VERSION ""

NS_ :

BS_:

BU_:  Inverter  Battery  Charger  Host

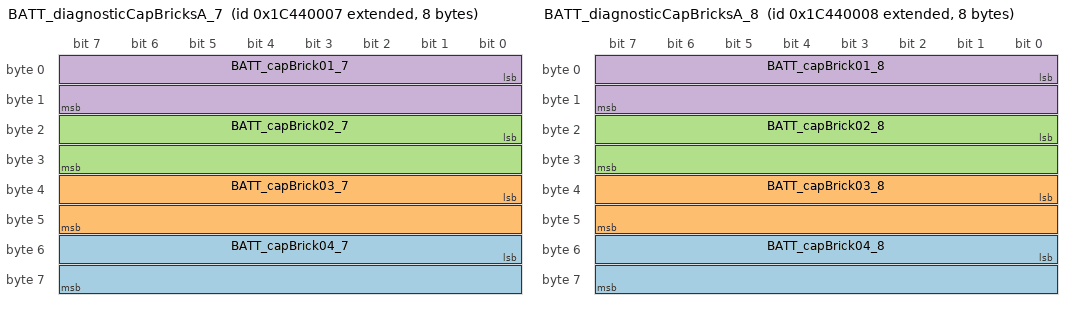
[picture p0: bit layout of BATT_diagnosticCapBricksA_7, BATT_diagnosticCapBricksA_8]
BO_ 2621702151 BATT_diagnosticCapBricksA_7: 8 Battery
 SG_ BATT_capBrick04_7 : 48|16@1+ (0.00075,0) [0|49.15125] "Ah" Host
 SG_ BATT_capBrick03_7 : 32|16@1+ (0.00075,0) [0|49.15125] "Ah" Host
 SG_ BATT_capBrick02_7 : 16|16@1+ (0.00075,0) [0|49.15125] "Ah" Host
 SG_ BATT_capBrick01_7 : 0|16@1+ (0.00075,0) [0|49.15125] "Ah" Host

BO_ 2621702152 BATT_diagnosticCapBricksA_8: 8 Battery
 SG_ BATT_capBrick04_8 : 48|16@1+ (0.00075,0) [0|49.15125] "Ah" Host
 SG_ BATT_capBrick03_8 : 32|16@1+ (0.00075,0) [0|49.15125] "Ah" Host
 SG_ BATT_capBrick02_8 : 16|16@1+ (0.00075,0) [0|49.15125] "Ah" Host
 SG_ BATT_capBrick01_8 : 0|16@1+ (0.00075,0) [0|49.15125] "Ah" Host

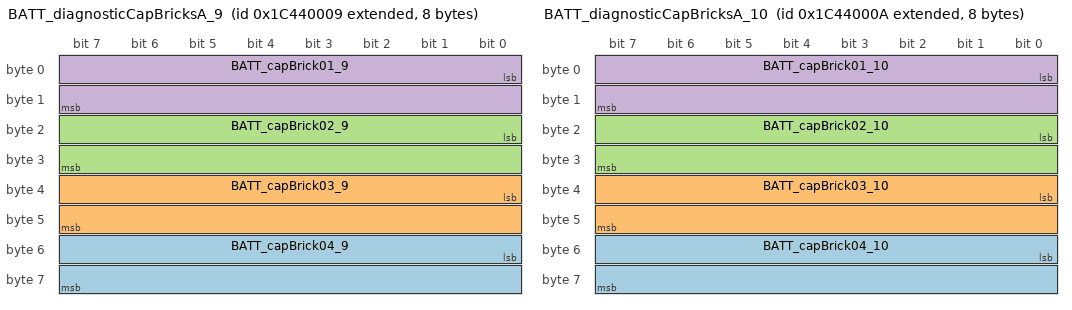
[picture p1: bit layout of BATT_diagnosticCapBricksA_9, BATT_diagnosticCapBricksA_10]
BO_ 2621702153 BATT_diagnosticCapBricksA_9: 8 Battery
 SG_ BATT_capBrick04_9 : 48|16@1+ (0.00075,0) [0|49.15125] "Ah" Host
 SG_ BATT_capBrick03_9 : 32|16@1+ (0.00075,0) [0|49.15125] "Ah" Host
 SG_ BATT_capBrick02_9 : 16|16@1+ (0.00075,0) [0|49.15125] "Ah" Host
 SG_ BATT_capBrick01_9 : 0|16@1+ (0.00075,0) [0|49.15125] "Ah" Host

BO_ 2621702154 BATT_diagnosticCapBricksA_10: 8 Battery
 SG_ BATT_capBrick04_10 : 48|16@1+ (0.00075,0) [0|49.15125] "Ah" Host
 SG_ BATT_capBrick03_10 : 32|16@1+ (0.00075,0) [0|49.15125] "Ah" Host
 SG_ BATT_capBrick02_10 : 16|16@1+ (0.00075,0) [0|49.15125] "Ah" Host
 SG_ BATT_capBrick01_10 : 0|16@1+ (0.00075,0) [0|49.15125] "Ah" Host

BO_ 2621702155 BATT_diagnosticCapBricksA_11: 8 Battery
 SG_ BATT_capBrick04_11 : 48|16@1+ (0.00075,0) [0|49.15125] "Ah" Host
 SG_ BATT_capBrick03_11 : 32|16@1+ (0.00075,0) [0|49.15125] "Ah" Host
 SG_ BATT_capBrick02_11 : 16|16@1+ (0.00075,0) [0|49.15125] "Ah" Host
 SG_ BATT_capBrick01_11 : 0|16@1+ (0.00075,0) [0|49.15125] "Ah" Host

BO_ 2621964288 BATT_diagnosticCapBricksB_0: 8 Battery
 SG_ BATT_capBrick08_0 : 48|16@1+ (0.00075,0) [0|49.15125] "Ah" Host
 SG_ BATT_capBrick07_0 : 32|16@1+ (0.00075,0) [0|49.15125] "Ah" Host
 SG_ BATT_capBrick06_0 : 16|16@1+ (0.00075,0) [0|49.15125] "Ah" Host
 SG_ BATT_capBrick05_0 : 0|16@1+ (0.00075,0) [0|49.15125] "Ah" Host

BO_ 2621964289 BATT_diagnosticCapBricksB_1: 8 Battery
 SG_ BATT_capBrick08_1 : 48|16@1+ (0.00075,0) [0|49.15125] "Ah" Host
 SG_ BATT_capBrick07_1 : 32|16@1+ (0.00075,0) [0|49.15125] "Ah" Host
 SG_ BATT_capBrick06_1 : 16|16@1+ (0.00075,0) [0|49.15125] "Ah" Host
 SG_ BATT_capBrick05_1 : 0|16@1+ (0.00075,0) [0|49.15125] "Ah" Host

BO_ 2621964290 BATT_diagnosticCapBricksB_2: 8 Battery
 SG_ BATT_capBrick08_2 : 48|16@1+ (0.00075,0) [0|49.15125] "Ah" Host
 SG_ BATT_capBrick07_2 : 32|16@1+ (0.00075,0) [0|49.15125] "Ah" Host
 SG_ BATT_capBrick06_2 : 16|16@1+ (0.00075,0) [0|49.15125] "Ah" Host
 SG_ BATT_capBrick05_2 : 0|16@1+ (0.00075,0) [0|49.15125] "Ah" Host

BO_ 2621964291 BATT_diagnosticCapBricksB_3: 8 Battery
 SG_ BATT_capBrick08_3 : 48|16@1+ (0.00075,0) [0|49.15125] "Ah" Host
 SG_ BATT_capBrick07_3 : 32|16@1+ (0.00075,0) [0|49.15125] "Ah" Host
 SG_ BATT_capBrick06_3 : 16|16@1+ (0.00075,0) [0|49.15125] "Ah" Host
 SG_ BATT_capBrick05_3 : 0|16@1+ (0.00075,0) [0|49.15125] "Ah" Host

BO_ 2621964292 BATT_diagnosticCapBricksB_4: 8 Battery
 SG_ BATT_capBrick08_4 : 48|16@1+ (0.00075,0) [0|49.15125] "Ah" Host
 SG_ BATT_capBrick07_4 : 32|16@1+ (0.00075,0) [0|49.15125] "Ah" Host
 SG_ BATT_capBrick06_4 : 16|16@1+ (0.00075,0) [0|49.15125] "Ah" Host
 SG_ BATT_capBrick05_4 : 0|16@1+ (0.00075,0) [0|49.15125] "Ah" Host

BO_ 2621964293 BATT_diagnosticCapBricksB_5: 8 Battery
 SG_ BATT_capBrick08_5 : 48|16@1+ (0.00075,0) [0|49.15125] "Ah" Host
 SG_ BATT_capBrick07_5 : 32|16@1+ (0.00075,0) [0|49.15125] "Ah" Host
 SG_ BATT_capBrick06_5 : 16|16@1+ (0.00075,0) [0|49.15125] "Ah" Host
 SG_ BATT_capBrick05_5 : 0|16@1+ (0.00075,0) [0|49.15125] "Ah" Host

BO_ 2621964294 BATT_diagnosticCapBricksB_6: 8 Battery
 SG_ BATT_capBrick08_6 : 48|16@1+ (0.00075,0) [0|49.15125] "Ah" Host
 SG_ BATT_capBrick07_6 : 32|16@1+ (0.00075,0) [0|49.15125] "Ah" Host
 SG_ BATT_capBrick06_6 : 16|16@1+ (0.00075,0) [0|49.15125] "Ah" Host
 SG_ BATT_capBrick05_6 : 0|16@1+ (0.00075,0) [0|49.15125] "Ah" Host

BO_ 2621964295 BATT_diagnosticCapBricksB_7: 8 Battery
 SG_ BATT_capBrick08_7 : 48|16@1+ (0.00075,0) [0|49.15125] "Ah" Host
 SG_ BATT_capBrick07_7 : 32|16@1+ (0.00075,0) [0|49.15125] "Ah" Host
 SG_ BATT_capBrick06_7 : 16|16@1+ (0.00075,0) [0|49.15125] "Ah" Host
 SG_ BATT_capBrick05_7 : 0|16@1+ (0.00075,0) [0|49.15125] "Ah" Host

BO_ 2621964296 BATT_diagnosticCapBricksB_8: 8 Battery
 SG_ BATT_capBrick08_8 : 48|16@1+ (0.00075,0) [0|49.15125] "Ah" Host
 SG_ BATT_capBrick07_8 : 32|16@1+ (0.00075,0) [0|49.15125] "Ah" Host
 SG_ BATT_capBrick06_8 : 16|16@1+ (0.00075,0) [0|49.15125] "Ah" Host
 SG_ BATT_capBrick05_8 : 0|16@1+ (0.00075,0) [0|49.15125] "Ah" Host

BO_ 2621964297 BATT_diagnosticCapBricksB_9: 8 Battery
 SG_ BATT_capBrick08_9 : 48|16@1+ (0.00075,0) [0|49.15125] "Ah" Host
 SG_ BATT_capBrick07_9 : 32|16@1+ (0.00075,0) [0|49.15125] "Ah" Host
 SG_ BATT_capBrick06_9 : 16|16@1+ (0.00075,0) [0|49.15125] "Ah" Host
 SG_ BATT_capBrick05_9 : 0|16@1+ (0.00075,0) [0|49.15125] "Ah" Host

BO_ 2621964298 BATT_diagnosticCapBricksB_10: 8 Battery
 SG_ BATT_capBrick08_10 : 48|16@1+ (0.00075,0) [0|49.15125] "Ah" Host
 SG_ BATT_capBrick07_10 : 32|16@1+ (0.00075,0) [0|49.15125] "Ah" Host
 SG_ BATT_capBrick06_10 : 16|16@1+ (0.00075,0) [0|49.15125] "Ah" Host
 SG_ BATT_capBrick05_10 : 0|16@1+ (0.00075,0) [0|49.15125] "Ah" Host

BO_ 2621964299 BATT_diagnosticCapBricksB_11: 8 Battery
 SG_ BATT_capBrick08_11 : 48|16@1+ (0.00075,0) [0|49.15125] "Ah" Host
 SG_ BATT_capBrick07_11 : 32|16@1+ (0.00075,0) [0|49.15125] "Ah" Host
 SG_ BATT_capBrick06_11 : 16|16@1+ (0.00075,0) [0|49.15125] "Ah" Host
 SG_ BATT_capBrick05_11 : 0|16@1+ (0.00075,0) [0|49.15125] "Ah" Host

BO_ 2622226432 BATT_diagnosticCapBricksC_0: 8 Battery
 SG_ BATT_capBrick12_0 : 48|16@1+ (0.00075,0) [0|49.15125] "Ah" Host
 SG_ BATT_capBrick11_0 : 32|16@1+ (0.00075,0) [0|49.15125] "Ah" Host
 SG_ BATT_capBrick09_0 : 0|16@1+ (0.00075,0) [0|49.15125] "Ah" Host
 SG_ BATT_capBrick10_0 : 16|16@1+ (0.00075,0) [0|49.15125] "Ah" Host

BO_ 2622226433 BATT_diagnosticCapBricksC_1: 8 Battery
 SG_ BATT_capBrick12_1 : 48|16@1+ (0.00075,0) [0|49.15125] "Ah" Host
 SG_ BATT_capBrick11_1 : 32|16@1+ (0.00075,0) [0|49.15125] "Ah" Host
 SG_ BATT_capBrick09_1 : 0|16@1+ (0.00075,0) [0|49.15125] "Ah" Host
 SG_ BATT_capBrick10_1 : 16|16@1+ (0.00075,0) [0|49.15125] "Ah" Host

BO_ 2622226434 BATT_diagnosticCapBricksC_2: 8 Battery
 SG_ BATT_capBrick12_2 : 48|16@1+ (0.00075,0) [0|49.15125] "Ah" Host
 SG_ BATT_capBrick11_2 : 32|16@1+ (0.00075,0) [0|49.15125] "Ah" Host
 SG_ BATT_capBrick09_2 : 0|16@1+ (0.00075,0) [0|49.15125] "Ah" Host
 SG_ BATT_capBrick10_2 : 16|16@1+ (0.00075,0) [0|49.15125] "Ah" Host

BO_ 2622226435 BATT_diagnosticCapBricksC_3: 8 Battery
 SG_ BATT_capBrick12_3 : 48|16@1+ (0.00075,0) [0|49.15125] "Ah" Host
 SG_ BATT_capBrick11_3 : 32|16@1+ (0.00075,0) [0|49.15125] "Ah" Host
 SG_ BATT_capBrick09_3 : 0|16@1+ (0.00075,0) [0|49.15125] "Ah" Host
 SG_ BATT_capBrick10_3 : 16|16@1+ (0.00075,0) [0|49.15125] "Ah" Host

BO_ 2622226436 BATT_diagnosticCapBricksC_4: 8 Battery
 SG_ BATT_capBrick12_4 : 48|16@1+ (0.00075,0) [0|49.15125] "Ah" Host
 SG_ BATT_capBrick11_4 : 32|16@1+ (0.00075,0) [0|49.15125] "Ah" Host
 SG_ BATT_capBrick09_4 : 0|16@1+ (0.00075,0) [0|49.15125] "Ah" Host
 SG_ BATT_capBrick10_4 : 16|16@1+ (0.00075,0) [0|49.15125] "Ah" Host

BO_ 2622226437 BATT_diagnosticCapBricksC_5: 8 Battery
 SG_ BATT_capBrick12_5 : 48|16@1+ (0.00075,0) [0|49.15125] "Ah" Host
 SG_ BATT_capBrick11_5 : 32|16@1+ (0.00075,0) [0|49.15125] "Ah" Host
 SG_ BATT_capBrick09_5 : 0|16@1+ (0.00075,0) [0|49.15125] "Ah" Host
 SG_ BATT_capBrick10_5 : 16|16@1+ (0.00075,0) [0|49.15125] "Ah" Host

BO_ 2622226438 BATT_diagnosticCapBricksC_6: 8 Battery
 SG_ BATT_capBrick12_6 : 48|16@1+ (0.00075,0) [0|49.15125] "Ah" Host
 SG_ BATT_capBrick11_6 : 32|16@1+ (0.00075,0) [0|49.15125] "Ah" Host
 SG_ BATT_capBrick09_6 : 0|16@1+ (0.00075,0) [0|49.15125] "Ah" Host
 SG_ BATT_capBrick10_6 : 16|16@1+ (0.00075,0) [0|49.15125] "Ah" Host

BO_ 2622226439 BATT_diagnosticCapBricksC_7: 8 Battery
 SG_ BATT_capBrick12_7 : 48|16@1+ (0.00075,0) [0|49.15125] "Ah" Host
 SG_ BATT_capBrick11_7 : 32|16@1+ (0.00075,0) [0|49.15125] "Ah" Host
 SG_ BATT_capBrick09_7 : 0|16@1+ (0.00075,0) [0|49.15125] "Ah" Host
 SG_ BATT_capBrick10_7 : 16|16@1+ (0.00075,0) [0|49.15125] "Ah" Host

BO_ 2622226440 BATT_diagnosticCapBricksC_8: 8 Battery
 SG_ BATT_capBrick12_8 : 48|16@1+ (0.00075,0) [0|49.15125] "Ah" Host
 SG_ BATT_capBrick11_8 : 32|16@1+ (0.00075,0) [0|49.15125] "Ah" Host
 SG_ BATT_capBrick09_8 : 0|16@1+ (0.00075,0) [0|49.15125] "Ah" Host
 SG_ BATT_capBrick10_8 : 16|16@1+ (0.00075,0) [0|49.15125] "Ah" Host

BO_ 2622226441 BATT_diagnosticCapBricksC_9: 8 Battery
 SG_ BATT_capBrick12_9 : 48|16@1+ (0.00075,0) [0|49.15125] "Ah" Host
 SG_ BATT_capBrick11_9 : 32|16@1+ (0.00075,0) [0|49.15125] "Ah" Host
 SG_ BATT_capBrick09_9 : 0|16@1+ (0.00075,0) [0|49.15125] "Ah" Host
 SG_ BATT_capBrick10_9 : 16|16@1+ (0.00075,0) [0|49.15125] "Ah" Host

BO_ 2622226442 BATT_diagnosticCapBricksC_10: 8 Battery
 SG_ BATT_capBrick12_10 : 48|16@1+ (0.00075,0) [0|49.15125] "Ah" Host
 SG_ BATT_capBrick11_10 : 32|16@1+ (0.00075,0) [0|49.15125] "Ah" Host
 SG_ BATT_capBrick09_10 : 0|16@1+ (0.00075,0) [0|49.15125] "Ah" Host
 SG_ BATT_capBrick10_10 : 16|16@1+ (0.00075,0) [0|49.15125] "Ah" Host

BO_ 2622226443 BATT_diagnosticCapBricksC_11: 8 Battery
 SG_ BATT_capBrick12_11 : 48|16@1+ (0.00075,0) [0|49.15125] "Ah" Host
 SG_ BATT_capBrick11_11 : 32|16@1+ (0.00075,0) [0|49.15125] "Ah" Host
 SG_ BATT_capBrick09_11 : 0|16@1+ (0.00075,0) [0|49.15125] "Ah" Host
 SG_ BATT_capBrick10_11 : 16|16@1+ (0.00075,0) [0|49.15125] "Ah" Host

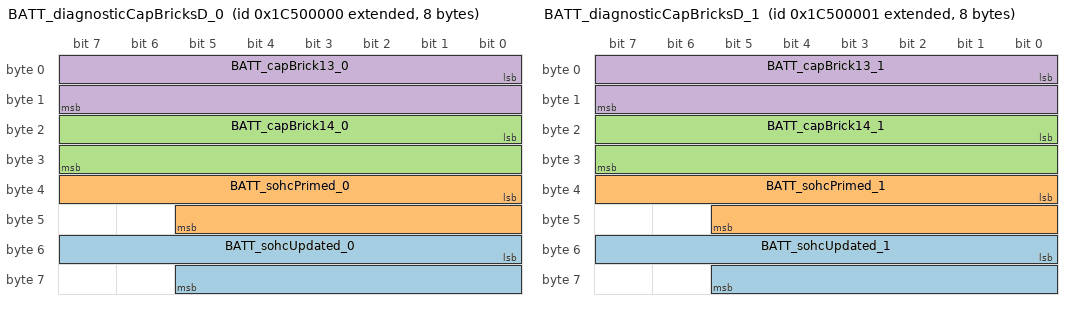
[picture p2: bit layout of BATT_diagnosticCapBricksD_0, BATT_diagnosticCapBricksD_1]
BO_ 2622488576 BATT_diagnosticCapBricksD_0: 8 Battery
 SG_ BATT_sohcUpdated_0 : 48|14@1+ (1,0) [0|16383] "" Host
 SG_ BATT_sohcPrimed_0 : 32|14@1+ (1,0) [0|16383] "" Host
 SG_ BATT_capBrick14_0 : 16|16@1+ (0.00075,0) [0|49.15125] "Ah" Host
 SG_ BATT_capBrick13_0 : 0|16@1+ (0.00075,0) [0|49.15125] "Ah" Host

BO_ 2622488577 BATT_diagnosticCapBricksD_1: 8 Battery
 SG_ BATT_sohcUpdated_1 : 48|14@1+ (1,0) [0|16383] "" Host
 SG_ BATT_sohcPrimed_1 : 32|14@1+ (1,0) [0|16383] "" Host
 SG_ BATT_capBrick14_1 : 16|16@1+ (0.00075,0) [0|49.15125] "Ah" Host
 SG_ BATT_capBrick13_1 : 0|16@1+ (0.00075,0) [0|49.15125] "Ah" Host

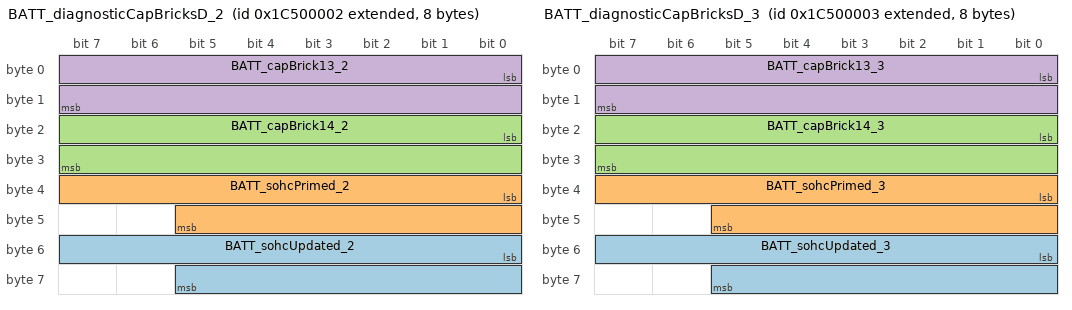
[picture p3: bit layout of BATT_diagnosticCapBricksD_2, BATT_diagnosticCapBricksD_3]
BO_ 2622488578 BATT_diagnosticCapBricksD_2: 8 Battery
 SG_ BATT_sohcUpdated_2 : 48|14@1+ (1,0) [0|16383] "" Host
 SG_ BATT_sohcPrimed_2 : 32|14@1+ (1,0) [0|16383] "" Host
 SG_ BATT_capBrick14_2 : 16|16@1+ (0.00075,0) [0|49.15125] "Ah" Host
 SG_ BATT_capBrick13_2 : 0|16@1+ (0.00075,0) [0|49.15125] "Ah" Host

BO_ 2622488579 BATT_diagnosticCapBricksD_3: 8 Battery
 SG_ BATT_sohcUpdated_3 : 48|14@1+ (1,0) [0|16383] "" Host
 SG_ BATT_sohcPrimed_3 : 32|14@1+ (1,0) [0|16383] "" Host
 SG_ BATT_capBrick14_3 : 16|16@1+ (0.00075,0) [0|49.15125] "Ah" Host
 SG_ BATT_capBrick13_3 : 0|16@1+ (0.00075,0) [0|49.15125] "Ah" Host

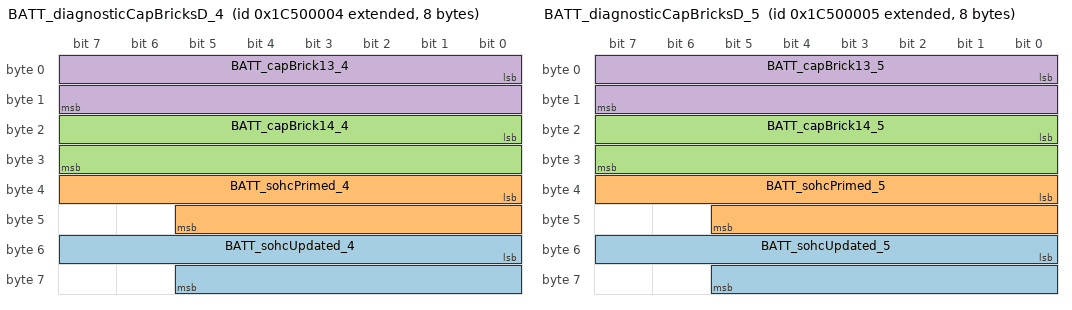
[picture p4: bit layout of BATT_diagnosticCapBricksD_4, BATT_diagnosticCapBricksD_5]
BO_ 2622488580 BATT_diagnosticCapBricksD_4: 8 Battery
 SG_ BATT_sohcUpdated_4 : 48|14@1+ (1,0) [0|16383] "" Host
 SG_ BATT_sohcPrimed_4 : 32|14@1+ (1,0) [0|16383] "" Host
 SG_ BATT_capBrick14_4 : 16|16@1+ (0.00075,0) [0|49.15125] "Ah" Host
 SG_ BATT_capBrick13_4 : 0|16@1+ (0.00075,0) [0|49.15125] "Ah" Host

BO_ 2622488581 BATT_diagnosticCapBricksD_5: 8 Battery
 SG_ BATT_sohcUpdated_5 : 48|14@1+ (1,0) [0|16383] "" Host
 SG_ BATT_sohcPrimed_5 : 32|14@1+ (1,0) [0|16383] "" Host
 SG_ BATT_capBrick14_5 : 16|16@1+ (0.00075,0) [0|49.15125] "Ah" Host
 SG_ BATT_capBrick13_5 : 0|16@1+ (0.00075,0) [0|49.15125] "Ah" Host

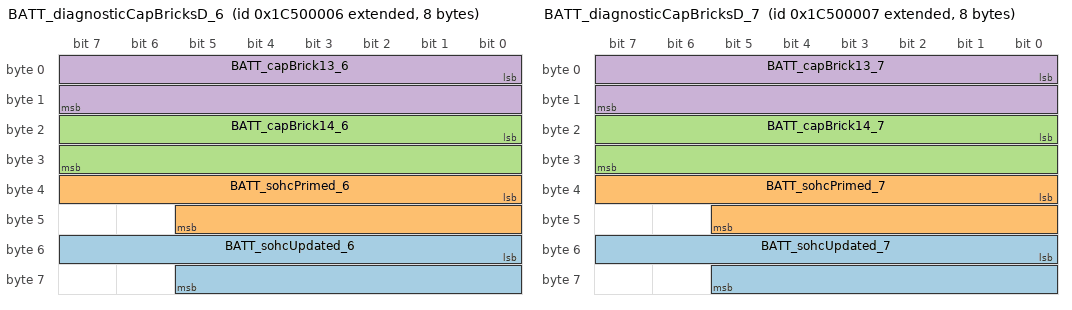
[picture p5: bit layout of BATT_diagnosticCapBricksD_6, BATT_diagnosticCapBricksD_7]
BO_ 2622488582 BATT_diagnosticCapBricksD_6: 8 Battery
 SG_ BATT_sohcUpdated_6 : 48|14@1+ (1,0) [0|16383] "" Host
 SG_ BATT_sohcPrimed_6 : 32|14@1+ (1,0) [0|16383] "" Host
 SG_ BATT_capBrick14_6 : 16|16@1+ (0.00075,0) [0|49.15125] "Ah" Host
 SG_ BATT_capBrick13_6 : 0|16@1+ (0.00075,0) [0|49.15125] "Ah" Host

BO_ 2622488583 BATT_diagnosticCapBricksD_7: 8 Battery
 SG_ BATT_sohcUpdated_7 : 48|14@1+ (1,0) [0|16383] "" Host
 SG_ BATT_sohcPrimed_7 : 32|14@1+ (1,0) [0|16383] "" Host
 SG_ BATT_capBrick14_7 : 16|16@1+ (0.00075,0) [0|49.15125] "Ah" Host
 SG_ BATT_capBrick13_7 : 0|16@1+ (0.00075,0) [0|49.15125] "Ah" Host

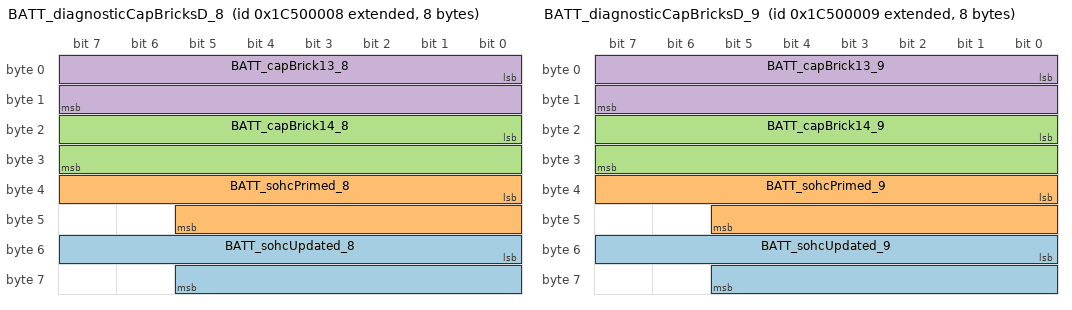
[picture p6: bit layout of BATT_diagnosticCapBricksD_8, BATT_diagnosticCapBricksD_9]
BO_ 2622488584 BATT_diagnosticCapBricksD_8: 8 Battery
 SG_ BATT_sohcUpdated_8 : 48|14@1+ (1,0) [0|16383] "" Host
 SG_ BATT_sohcPrimed_8 : 32|14@1+ (1,0) [0|16383] "" Host
 SG_ BATT_capBrick14_8 : 16|16@1+ (0.00075,0) [0|49.15125] "Ah" Host
 SG_ BATT_capBrick13_8 : 0|16@1+ (0.00075,0) [0|49.15125] "Ah" Host

BO_ 2622488585 BATT_diagnosticCapBricksD_9: 8 Battery
 SG_ BATT_sohcUpdated_9 : 48|14@1+ (1,0) [0|16383] "" Host
 SG_ BATT_sohcPrimed_9 : 32|14@1+ (1,0) [0|16383] "" Host
 SG_ BATT_capBrick14_9 : 16|16@1+ (0.00075,0) [0|49.15125] "Ah" Host
 SG_ BATT_capBrick13_9 : 0|16@1+ (0.00075,0) [0|49.15125] "Ah" Host

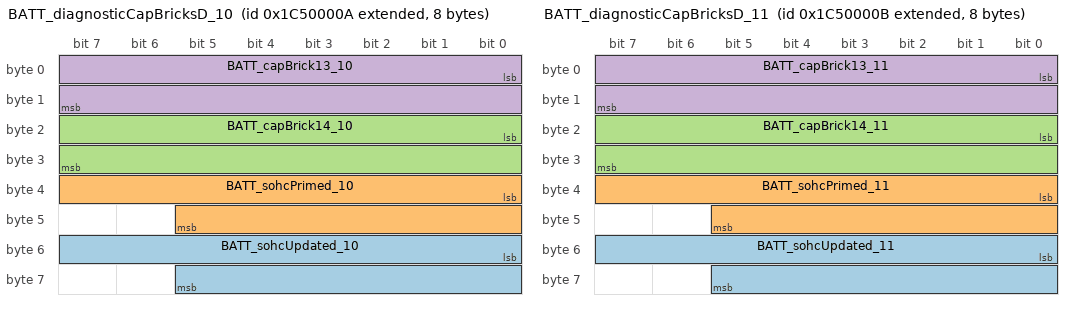
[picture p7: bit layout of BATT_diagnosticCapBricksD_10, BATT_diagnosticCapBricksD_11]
BO_ 2622488586 BATT_diagnosticCapBricksD_10: 8 Battery
 SG_ BATT_sohcUpdated_10 : 48|14@1+ (1,0) [0|16383] "" Host
 SG_ BATT_sohcPrimed_10 : 32|14@1+ (1,0) [0|16383] "" Host
 SG_ BATT_capBrick14_10 : 16|16@1+ (0.00075,0) [0|49.15125] "Ah" Host
 SG_ BATT_capBrick13_10 : 0|16@1+ (0.00075,0) [0|49.15125] "Ah" Host

BO_ 2622488587 BATT_diagnosticCapBricksD_11: 8 Battery
 SG_ BATT_sohcUpdated_11 : 48|14@1+ (1,0) [0|16383] "" Host
 SG_ BATT_sohcPrimed_11 : 32|14@1+ (1,0) [0|16383] "" Host
 SG_ BATT_capBrick14_11 : 16|16@1+ (0.00075,0) [0|49.15125] "Ah" Host
 SG_ BATT_capBrick13_11 : 0|16@1+ (0.00075,0) [0|49.15125] "Ah" Host

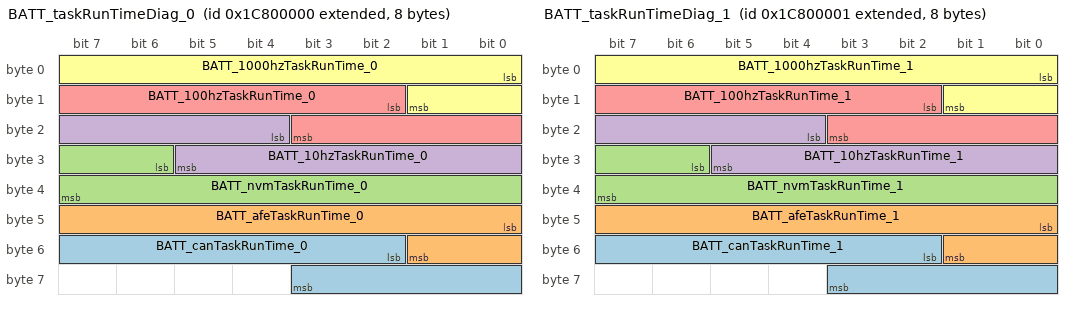
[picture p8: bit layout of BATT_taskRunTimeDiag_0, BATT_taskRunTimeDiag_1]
BO_ 2625634304 BATT_taskRunTimeDiag_0: 8 Battery
 SG_ BATT_canTaskRunTime_0 : 50|10@1+ (1,0) [0|1023] "ms" Host
 SG_ BATT_afeTaskRunTime_0 : 40|10@1+ (1,0) [0|1023] "ms" Host
 SG_ BATT_nvmTaskRunTime_0 : 30|10@1+ (1,0) [0|1023] "ms" Host
 SG_ BATT_10hzTaskRunTime_0 : 20|10@1+ (1,0) [0|1023] "ms" Host
 SG_ BATT_100hzTaskRunTime_0 : 10|10@1+ (1,0) [0|1023] "ms" Host
 SG_ BATT_1000hzTaskRunTime_0 : 0|10@1+ (1,0) [0|1023] "ms" Host

BO_ 2625634305 BATT_taskRunTimeDiag_1: 8 Battery
 SG_ BATT_canTaskRunTime_1 : 50|10@1+ (1,0) [0|1023] "ms" Host
 SG_ BATT_afeTaskRunTime_1 : 40|10@1+ (1,0) [0|1023] "ms" Host
 SG_ BATT_nvmTaskRunTime_1 : 30|10@1+ (1,0) [0|1023] "ms" Host
 SG_ BATT_10hzTaskRunTime_1 : 20|10@1+ (1,0) [0|1023] "ms" Host
 SG_ BATT_100hzTaskRunTime_1 : 10|10@1+ (1,0) [0|1023] "ms" Host
 SG_ BATT_1000hzTaskRunTime_1 : 0|10@1+ (1,0) [0|1023] "ms" Host

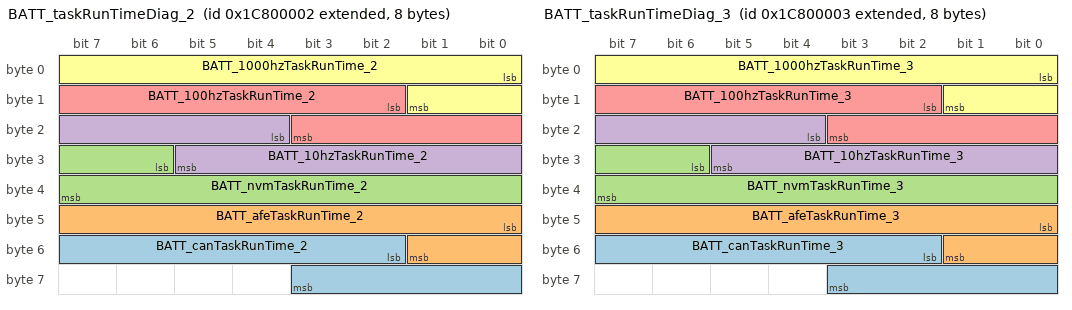
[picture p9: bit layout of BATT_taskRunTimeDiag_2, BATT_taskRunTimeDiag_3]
BO_ 2625634306 BATT_taskRunTimeDiag_2: 8 Battery
 SG_ BATT_canTaskRunTime_2 : 50|10@1+ (1,0) [0|1023] "ms" Host
 SG_ BATT_afeTaskRunTime_2 : 40|10@1+ (1,0) [0|1023] "ms" Host
 SG_ BATT_nvmTaskRunTime_2 : 30|10@1+ (1,0) [0|1023] "ms" Host
 SG_ BATT_10hzTaskRunTime_2 : 20|10@1+ (1,0) [0|1023] "ms" Host
 SG_ BATT_100hzTaskRunTime_2 : 10|10@1+ (1,0) [0|1023] "ms" Host
 SG_ BATT_1000hzTaskRunTime_2 : 0|10@1+ (1,0) [0|1023] "ms" Host

BO_ 2625634307 BATT_taskRunTimeDiag_3: 8 Battery
 SG_ BATT_canTaskRunTime_3 : 50|10@1+ (1,0) [0|1023] "ms" Host
 SG_ BATT_afeTaskRunTime_3 : 40|10@1+ (1,0) [0|1023] "ms" Host
 SG_ BATT_nvmTaskRunTime_3 : 30|10@1+ (1,0) [0|1023] "ms" Host
 SG_ BATT_10hzTaskRunTime_3 : 20|10@1+ (1,0) [0|1023] "ms" Host
 SG_ BATT_100hzTaskRunTime_3 : 10|10@1+ (1,0) [0|1023] "ms" Host
 SG_ BATT_1000hzTaskRunTime_3 : 0|10@1+ (1,0) [0|1023] "ms" Host

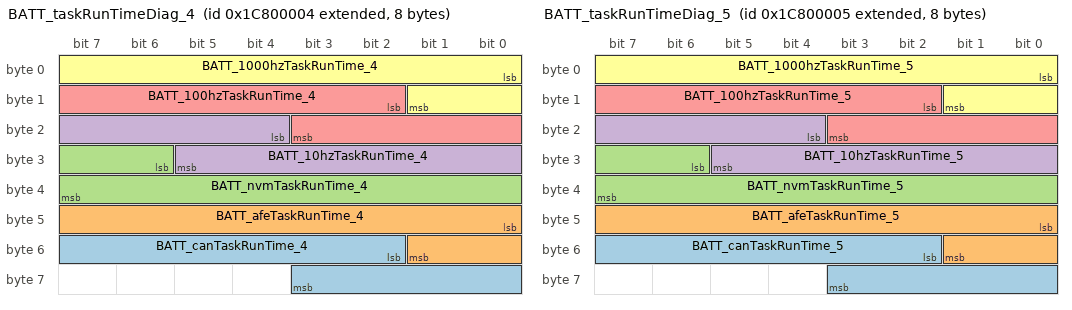
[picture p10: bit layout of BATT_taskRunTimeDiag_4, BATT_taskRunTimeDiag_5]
BO_ 2625634308 BATT_taskRunTimeDiag_4: 8 Battery
 SG_ BATT_canTaskRunTime_4 : 50|10@1+ (1,0) [0|1023] "ms" Host
 SG_ BATT_afeTaskRunTime_4 : 40|10@1+ (1,0) [0|1023] "ms" Host
 SG_ BATT_nvmTaskRunTime_4 : 30|10@1+ (1,0) [0|1023] "ms" Host
 SG_ BATT_10hzTaskRunTime_4 : 20|10@1+ (1,0) [0|1023] "ms" Host
 SG_ BATT_100hzTaskRunTime_4 : 10|10@1+ (1,0) [0|1023] "ms" Host
 SG_ BATT_1000hzTaskRunTime_4 : 0|10@1+ (1,0) [0|1023] "ms" Host

BO_ 2625634309 BATT_taskRunTimeDiag_5: 8 Battery
 SG_ BATT_canTaskRunTime_5 : 50|10@1+ (1,0) [0|1023] "ms" Host
 SG_ BATT_afeTaskRunTime_5 : 40|10@1+ (1,0) [0|1023] "ms" Host
 SG_ BATT_nvmTaskRunTime_5 : 30|10@1+ (1,0) [0|1023] "ms" Host
 SG_ BATT_10hzTaskRunTime_5 : 20|10@1+ (1,0) [0|1023] "ms" Host
 SG_ BATT_100hzTaskRunTime_5 : 10|10@1+ (1,0) [0|1023] "ms" Host
 SG_ BATT_1000hzTaskRunTime_5 : 0|10@1+ (1,0) [0|1023] "ms" Host

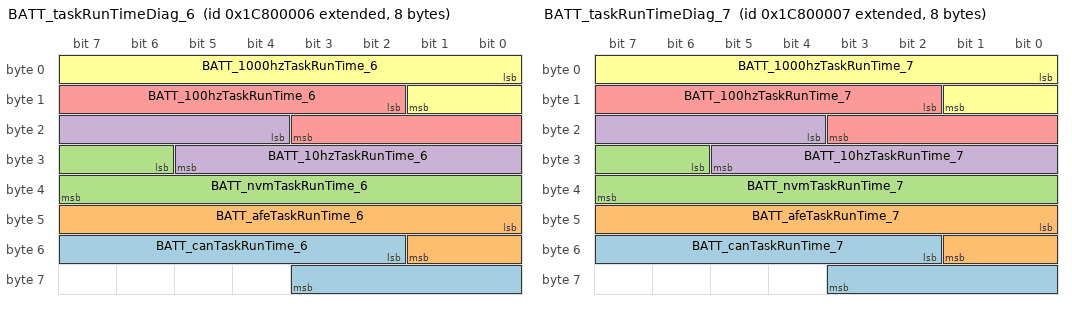
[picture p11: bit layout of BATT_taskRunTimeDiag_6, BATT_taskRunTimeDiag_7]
BO_ 2625634310 BATT_taskRunTimeDiag_6: 8 Battery
 SG_ BATT_canTaskRunTime_6 : 50|10@1+ (1,0) [0|1023] "ms" Host
 SG_ BATT_afeTaskRunTime_6 : 40|10@1+ (1,0) [0|1023] "ms" Host
 SG_ BATT_nvmTaskRunTime_6 : 30|10@1+ (1,0) [0|1023] "ms" Host
 SG_ BATT_10hzTaskRunTime_6 : 20|10@1+ (1,0) [0|1023] "ms" Host
 SG_ BATT_100hzTaskRunTime_6 : 10|10@1+ (1,0) [0|1023] "ms" Host
 SG_ BATT_1000hzTaskRunTime_6 : 0|10@1+ (1,0) [0|1023] "ms" Host

BO_ 2625634311 BATT_taskRunTimeDiag_7: 8 Battery
 SG_ BATT_canTaskRunTime_7 : 50|10@1+ (1,0) [0|1023] "ms" Host
 SG_ BATT_afeTaskRunTime_7 : 40|10@1+ (1,0) [0|1023] "ms" Host
 SG_ BATT_nvmTaskRunTime_7 : 30|10@1+ (1,0) [0|1023] "ms" Host
 SG_ BATT_10hzTaskRunTime_7 : 20|10@1+ (1,0) [0|1023] "ms" Host
 SG_ BATT_100hzTaskRunTime_7 : 10|10@1+ (1,0) [0|1023] "ms" Host
 SG_ BATT_1000hzTaskRunTime_7 : 0|10@1+ (1,0) [0|1023] "ms" Host

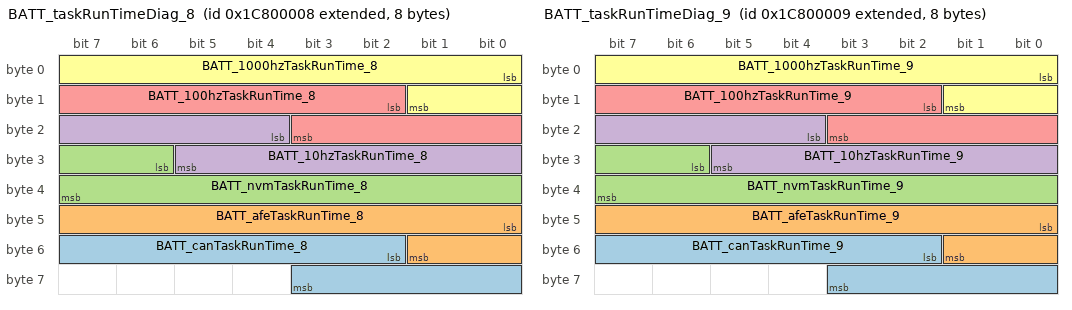
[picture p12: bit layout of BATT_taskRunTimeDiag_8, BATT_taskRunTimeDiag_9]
BO_ 2625634312 BATT_taskRunTimeDiag_8: 8 Battery
 SG_ BATT_canTaskRunTime_8 : 50|10@1+ (1,0) [0|1023] "ms" Host
 SG_ BATT_afeTaskRunTime_8 : 40|10@1+ (1,0) [0|1023] "ms" Host
 SG_ BATT_nvmTaskRunTime_8 : 30|10@1+ (1,0) [0|1023] "ms" Host
 SG_ BATT_10hzTaskRunTime_8 : 20|10@1+ (1,0) [0|1023] "ms" Host
 SG_ BATT_100hzTaskRunTime_8 : 10|10@1+ (1,0) [0|1023] "ms" Host
 SG_ BATT_1000hzTaskRunTime_8 : 0|10@1+ (1,0) [0|1023] "ms" Host

BO_ 2625634313 BATT_taskRunTimeDiag_9: 8 Battery
 SG_ BATT_canTaskRunTime_9 : 50|10@1+ (1,0) [0|1023] "ms" Host
 SG_ BATT_afeTaskRunTime_9 : 40|10@1+ (1,0) [0|1023] "ms" Host
 SG_ BATT_nvmTaskRunTime_9 : 30|10@1+ (1,0) [0|1023] "ms" Host
 SG_ BATT_10hzTaskRunTime_9 : 20|10@1+ (1,0) [0|1023] "ms" Host
 SG_ BATT_100hzTaskRunTime_9 : 10|10@1+ (1,0) [0|1023] "ms" Host
 SG_ BATT_1000hzTaskRunTime_9 : 0|10@1+ (1,0) [0|1023] "ms" Host

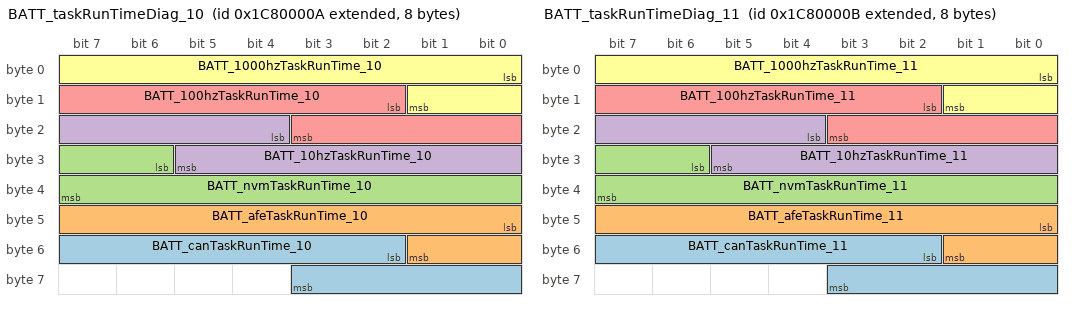
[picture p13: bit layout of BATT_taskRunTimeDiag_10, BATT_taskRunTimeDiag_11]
BO_ 2625634314 BATT_taskRunTimeDiag_10: 8 Battery
 SG_ BATT_canTaskRunTime_10 : 50|10@1+ (1,0) [0|1023] "ms" Host
 SG_ BATT_afeTaskRunTime_10 : 40|10@1+ (1,0) [0|1023] "ms" Host
 SG_ BATT_nvmTaskRunTime_10 : 30|10@1+ (1,0) [0|1023] "ms" Host
 SG_ BATT_10hzTaskRunTime_10 : 20|10@1+ (1,0) [0|1023] "ms" Host
 SG_ BATT_100hzTaskRunTime_10 : 10|10@1+ (1,0) [0|1023] "ms" Host
 SG_ BATT_1000hzTaskRunTime_10 : 0|10@1+ (1,0) [0|1023] "ms" Host

BO_ 2625634315 BATT_taskRunTimeDiag_11: 8 Battery
 SG_ BATT_canTaskRunTime_11 : 50|10@1+ (1,0) [0|1023] "ms" Host
 SG_ BATT_afeTaskRunTime_11 : 40|10@1+ (1,0) [0|1023] "ms" Host
 SG_ BATT_nvmTaskRunTime_11 : 30|10@1+ (1,0) [0|1023] "ms" Host
 SG_ BATT_10hzTaskRunTime_11 : 20|10@1+ (1,0) [0|1023] "ms" Host
 SG_ BATT_100hzTaskRunTime_11 : 10|10@1+ (1,0) [0|1023] "ms" Host
 SG_ BATT_1000hzTaskRunTime_11 : 0|10@1+ (1,0) [0|1023] "ms" Host

BO_ 2625896448 BATT_diagnosticVBricksA_0: 8 Battery
 SG_ BATT_vBrick02_0 : 16|16@1+ (7.6e-05,0) [0|4.98066] "V" Host
 SG_ BATT_vBrick03_0 : 32|16@1+ (7.6e-05,0) [0|4.98066] "V" Host
 SG_ BATT_vBrick01_0 : 0|16@1+ (7.6e-05,0) [0|4.98066] "V" Host
 SG_ BATT_vBrick04_0 : 48|16@1+ (7.6e-05,0) [0|4.98066] "V" Host

BO_ 2625896449 BATT_diagnosticVBricksA_1: 8 Battery
 SG_ BATT_vBrick02_1 : 16|16@1+ (7.6e-05,0) [0|4.98066] "V" Host
 SG_ BATT_vBrick03_1 : 32|16@1+ (7.6e-05,0) [0|4.98066] "V" Host
 SG_ BATT_vBrick01_1 : 0|16@1+ (7.6e-05,0) [0|4.98066] "V" Host
 SG_ BATT_vBrick04_1 : 48|16@1+ (7.6e-05,0) [0|4.98066] "V" Host

BO_ 2625896450 BATT_diagnosticVBricksA_2: 8 Battery
 SG_ BATT_vBrick02_2 : 16|16@1+ (7.6e-05,0) [0|4.98066] "V" Host
 SG_ BATT_vBrick03_2 : 32|16@1+ (7.6e-05,0) [0|4.98066] "V" Host
 SG_ BATT_vBrick01_2 : 0|16@1+ (7.6e-05,0) [0|4.98066] "V" Host
 SG_ BATT_vBrick04_2 : 48|16@1+ (7.6e-05,0) [0|4.98066] "V" Host

BO_ 2625896451 BATT_diagnosticVBricksA_3: 8 Battery
 SG_ BATT_vBrick02_3 : 16|16@1+ (7.6e-05,0) [0|4.98066] "V" Host
 SG_ BATT_vBrick03_3 : 32|16@1+ (7.6e-05,0) [0|4.98066] "V" Host
 SG_ BATT_vBrick01_3 : 0|16@1+ (7.6e-05,0) [0|4.98066] "V" Host
 SG_ BATT_vBrick04_3 : 48|16@1+ (7.6e-05,0) [0|4.98066] "V" Host

BO_ 2625896452 BATT_diagnosticVBricksA_4: 8 Battery
 SG_ BATT_vBrick02_4 : 16|16@1+ (7.6e-05,0) [0|4.98066] "V" Host
 SG_ BATT_vBrick03_4 : 32|16@1+ (7.6e-05,0) [0|4.98066] "V" Host
 SG_ BATT_vBrick01_4 : 0|16@1+ (7.6e-05,0) [0|4.98066] "V" Host
 SG_ BATT_vBrick04_4 : 48|16@1+ (7.6e-05,0) [0|4.98066] "V" Host

BO_ 2625896453 BATT_diagnosticVBricksA_5: 8 Battery
 SG_ BATT_vBrick02_5 : 16|16@1+ (7.6e-05,0) [0|4.98066] "V" Host
 SG_ BATT_vBrick03_5 : 32|16@1+ (7.6e-05,0) [0|4.98066] "V" Host
 SG_ BATT_vBrick01_5 : 0|16@1+ (7.6e-05,0) [0|4.98066] "V" Host
 SG_ BATT_vBrick04_5 : 48|16@1+ (7.6e-05,0) [0|4.98066] "V" Host

BO_ 2625896454 BATT_diagnosticVBricksA_6: 8 Battery
 SG_ BATT_vBrick02_6 : 16|16@1+ (7.6e-05,0) [0|4.98066] "V" Host
 SG_ BATT_vBrick03_6 : 32|16@1+ (7.6e-05,0) [0|4.98066] "V" Host
 SG_ BATT_vBrick01_6 : 0|16@1+ (7.6e-05,0) [0|4.98066] "V" Host
 SG_ BATT_vBrick04_6 : 48|16@1+ (7.6e-05,0) [0|4.98066] "V" Host

BO_ 2625896455 BATT_diagnosticVBricksA_7: 8 Battery
 SG_ BATT_vBrick02_7 : 16|16@1+ (7.6e-05,0) [0|4.98066] "V" Host
 SG_ BATT_vBrick03_7 : 32|16@1+ (7.6e-05,0) [0|4.98066] "V" Host
 SG_ BATT_vBrick01_7 : 0|16@1+ (7.6e-05,0) [0|4.98066] "V" Host
 SG_ BATT_vBrick04_7 : 48|16@1+ (7.6e-05,0) [0|4.98066] "V" Host

BO_ 2625896456 BATT_diagnosticVBricksA_8: 8 Battery
 SG_ BATT_vBrick02_8 : 16|16@1+ (7.6e-05,0) [0|4.98066] "V" Host
 SG_ BATT_vBrick03_8 : 32|16@1+ (7.6e-05,0) [0|4.98066] "V" Host
 SG_ BATT_vBrick01_8 : 0|16@1+ (7.6e-05,0) [0|4.98066] "V" Host
 SG_ BATT_vBrick04_8 : 48|16@1+ (7.6e-05,0) [0|4.98066] "V" Host

BO_ 2625896457 BATT_diagnosticVBricksA_9: 8 Battery
 SG_ BATT_vBrick02_9 : 16|16@1+ (7.6e-05,0) [0|4.98066] "V" Host
 SG_ BATT_vBrick03_9 : 32|16@1+ (7.6e-05,0) [0|4.98066] "V" Host
 SG_ BATT_vBrick01_9 : 0|16@1+ (7.6e-05,0) [0|4.98066] "V" Host
 SG_ BATT_vBrick04_9 : 48|16@1+ (7.6e-05,0) [0|4.98066] "V" Host

BO_ 2625896458 BATT_diagnosticVBricksA_10: 8 Battery
 SG_ BATT_vBrick02_10 : 16|16@1+ (7.6e-05,0) [0|4.98066] "V" Host
 SG_ BATT_vBrick03_10 : 32|16@1+ (7.6e-05,0) [0|4.98066] "V" Host
 SG_ BATT_vBrick01_10 : 0|16@1+ (7.6e-05,0) [0|4.98066] "V" Host
 SG_ BATT_vBrick04_10 : 48|16@1+ (7.6e-05,0) [0|4.98066] "V" Host

BO_ 2625896459 BATT_diagnosticVBricksA_11: 8 Battery
 SG_ BATT_vBrick02_11 : 16|16@1+ (7.6e-05,0) [0|4.98066] "V" Host
 SG_ BATT_vBrick03_11 : 32|16@1+ (7.6e-05,0) [0|4.98066] "V" Host
 SG_ BATT_vBrick01_11 : 0|16@1+ (7.6e-05,0) [0|4.98066] "V" Host
 SG_ BATT_vBrick04_11 : 48|16@1+ (7.6e-05,0) [0|4.98066] "V" Host

BO_ 2626158592 BATT_diagnosticVBricksB_0: 8 Battery
 SG_ BATT_vBrick06_0 : 16|16@1+ (7.6e-05,0) [0|4.98066] "V" Host
 SG_ BATT_vBrick07_0 : 32|16@1+ (7.6e-05,0) [0|4.98066] "V" Host
 SG_ BATT_vBrick05_0 : 0|16@1+ (7.6e-05,0) [0|4.98066] "V" Host
 SG_ BATT_vBrick08_0 : 48|16@1+ (7.6e-05,0) [0|4.98066] "V" Host

BO_ 2626158593 BATT_diagnosticVBricksB_1: 8 Battery
 SG_ BATT_vBrick06_1 : 16|16@1+ (7.6e-05,0) [0|4.98066] "V" Host
 SG_ BATT_vBrick07_1 : 32|16@1+ (7.6e-05,0) [0|4.98066] "V" Host
 SG_ BATT_vBrick05_1 : 0|16@1+ (7.6e-05,0) [0|4.98066] "V" Host
 SG_ BATT_vBrick08_1 : 48|16@1+ (7.6e-05,0) [0|4.98066] "V" Host

BO_ 2626158594 BATT_diagnosticVBricksB_2: 8 Battery
 SG_ BATT_vBrick06_2 : 16|16@1+ (7.6e-05,0) [0|4.98066] "V" Host
 SG_ BATT_vBrick07_2 : 32|16@1+ (7.6e-05,0) [0|4.98066] "V" Host
 SG_ BATT_vBrick05_2 : 0|16@1+ (7.6e-05,0) [0|4.98066] "V" Host
 SG_ BATT_vBrick08_2 : 48|16@1+ (7.6e-05,0) [0|4.98066] "V" Host

BO_ 2626158595 BATT_diagnosticVBricksB_3: 8 Battery
 SG_ BATT_vBrick06_3 : 16|16@1+ (7.6e-05,0) [0|4.98066] "V" Host
 SG_ BATT_vBrick07_3 : 32|16@1+ (7.6e-05,0) [0|4.98066] "V" Host
 SG_ BATT_vBrick05_3 : 0|16@1+ (7.6e-05,0) [0|4.98066] "V" Host
 SG_ BATT_vBrick08_3 : 48|16@1+ (7.6e-05,0) [0|4.98066] "V" Host

BO_ 2626158596 BATT_diagnosticVBricksB_4: 8 Battery
 SG_ BATT_vBrick06_4 : 16|16@1+ (7.6e-05,0) [0|4.98066] "V" Host
 SG_ BATT_vBrick07_4 : 32|16@1+ (7.6e-05,0) [0|4.98066] "V" Host
 SG_ BATT_vBrick05_4 : 0|16@1+ (7.6e-05,0) [0|4.98066] "V" Host
 SG_ BATT_vBrick08_4 : 48|16@1+ (7.6e-05,0) [0|4.98066] "V" Host

BO_ 2626158597 BATT_diagnosticVBricksB_5: 8 Battery
 SG_ BATT_vBrick06_5 : 16|16@1+ (7.6e-05,0) [0|4.98066] "V" Host
 SG_ BATT_vBrick07_5 : 32|16@1+ (7.6e-05,0) [0|4.98066] "V" Host
 SG_ BATT_vBrick05_5 : 0|16@1+ (7.6e-05,0) [0|4.98066] "V" Host
 SG_ BATT_vBrick08_5 : 48|16@1+ (7.6e-05,0) [0|4.98066] "V" Host

BO_ 2626158598 BATT_diagnosticVBricksB_6: 8 Battery
 SG_ BATT_vBrick06_6 : 16|16@1+ (7.6e-05,0) [0|4.98066] "V" Host
 SG_ BATT_vBrick07_6 : 32|16@1+ (7.6e-05,0) [0|4.98066] "V" Host
 SG_ BATT_vBrick05_6 : 0|16@1+ (7.6e-05,0) [0|4.98066] "V" Host
 SG_ BATT_vBrick08_6 : 48|16@1+ (7.6e-05,0) [0|4.98066] "V" Host

BO_ 2626158599 BATT_diagnosticVBricksB_7: 8 Battery
 SG_ BATT_vBrick06_7 : 16|16@1+ (7.6e-05,0) [0|4.98066] "V" Host
 SG_ BATT_vBrick07_7 : 32|16@1+ (7.6e-05,0) [0|4.98066] "V" Host
 SG_ BATT_vBrick05_7 : 0|16@1+ (7.6e-05,0) [0|4.98066] "V" Host
 SG_ BATT_vBrick08_7 : 48|16@1+ (7.6e-05,0) [0|4.98066] "V" Host

BO_ 2626158600 BATT_diagnosticVBricksB_8: 8 Battery
 SG_ BATT_vBrick06_8 : 16|16@1+ (7.6e-05,0) [0|4.98066] "V" Host
 SG_ BATT_vBrick07_8 : 32|16@1+ (7.6e-05,0) [0|4.98066] "V" Host
 SG_ BATT_vBrick05_8 : 0|16@1+ (7.6e-05,0) [0|4.98066] "V" Host
 SG_ BATT_vBrick08_8 : 48|16@1+ (7.6e-05,0) [0|4.98066] "V" Host

BO_ 2626158601 BATT_diagnosticVBricksB_9: 8 Battery
 SG_ BATT_vBrick06_9 : 16|16@1+ (7.6e-05,0) [0|4.98066] "V" Host
 SG_ BATT_vBrick07_9 : 32|16@1+ (7.6e-05,0) [0|4.98066] "V" Host
 SG_ BATT_vBrick05_9 : 0|16@1+ (7.6e-05,0) [0|4.98066] "V" Host
 SG_ BATT_vBrick08_9 : 48|16@1+ (7.6e-05,0) [0|4.98066] "V" Host

BO_ 2626158602 BATT_diagnosticVBricksB_10: 8 Battery
 SG_ BATT_vBrick06_10 : 16|16@1+ (7.6e-05,0) [0|4.98066] "V" Host
 SG_ BATT_vBrick07_10 : 32|16@1+ (7.6e-05,0) [0|4.98066] "V" Host
 SG_ BATT_vBrick05_10 : 0|16@1+ (7.6e-05,0) [0|4.98066] "V" Host
 SG_ BATT_vBrick08_10 : 48|16@1+ (7.6e-05,0) [0|4.98066] "V" Host

BO_ 2626158603 BATT_diagnosticVBricksB_11: 8 Battery
 SG_ BATT_vBrick06_11 : 16|16@1+ (7.6e-05,0) [0|4.98066] "V" Host
 SG_ BATT_vBrick07_11 : 32|16@1+ (7.6e-05,0) [0|4.98066] "V" Host
 SG_ BATT_vBrick05_11 : 0|16@1+ (7.6e-05,0) [0|4.98066] "V" Host
 SG_ BATT_vBrick08_11 : 48|16@1+ (7.6e-05,0) [0|4.98066] "V" Host

BO_ 2626420736 BATT_diagnosticVBricksC_0: 8 Battery
 SG_ BATT_vBrick12_0 : 48|16@1+ (7.6e-05,0) [0|4.98066] "V" Host
 SG_ BATT_vBrick11_0 : 32|16@1+ (7.6e-05,0) [0|4.98066] "V" Host
 SG_ BATT_vBrick10_0 : 16|16@1+ (7.6e-05,0) [0|4.98066] "V" Host
 SG_ BATT_vBrick09_0 : 0|16@1+ (7.6e-05,0) [0|4.98066] "V" Host

BO_ 2626420737 BATT_diagnosticVBricksC_1: 8 Battery
 SG_ BATT_vBrick12_1 : 48|16@1+ (7.6e-05,0) [0|4.98066] "V" Host
 SG_ BATT_vBrick11_1 : 32|16@1+ (7.6e-05,0) [0|4.98066] "V" Host
 SG_ BATT_vBrick10_1 : 16|16@1+ (7.6e-05,0) [0|4.98066] "V" Host
 SG_ BATT_vBrick09_1 : 0|16@1+ (7.6e-05,0) [0|4.98066] "V" Host

BO_ 2626420738 BATT_diagnosticVBricksC_2: 8 Battery
 SG_ BATT_vBrick12_2 : 48|16@1+ (7.6e-05,0) [0|4.98066] "V" Host
 SG_ BATT_vBrick11_2 : 32|16@1+ (7.6e-05,0) [0|4.98066] "V" Host
 SG_ BATT_vBrick10_2 : 16|16@1+ (7.6e-05,0) [0|4.98066] "V" Host
 SG_ BATT_vBrick09_2 : 0|16@1+ (7.6e-05,0) [0|4.98066] "V" Host

BO_ 2626420739 BATT_diagnosticVBricksC_3: 8 Battery
 SG_ BATT_vBrick12_3 : 48|16@1+ (7.6e-05,0) [0|4.98066] "V" Host
 SG_ BATT_vBrick11_3 : 32|16@1+ (7.6e-05,0) [0|4.98066] "V" Host
 SG_ BATT_vBrick10_3 : 16|16@1+ (7.6e-05,0) [0|4.98066] "V" Host
 SG_ BATT_vBrick09_3 : 0|16@1+ (7.6e-05,0) [0|4.98066] "V" Host

BO_ 2626420740 BATT_diagnosticVBricksC_4: 8 Battery
 SG_ BATT_vBrick12_4 : 48|16@1+ (7.6e-05,0) [0|4.98066] "V" Host
 SG_ BATT_vBrick11_4 : 32|16@1+ (7.6e-05,0) [0|4.98066] "V" Host
 SG_ BATT_vBrick10_4 : 16|16@1+ (7.6e-05,0) [0|4.98066] "V" Host
 SG_ BATT_vBrick09_4 : 0|16@1+ (7.6e-05,0) [0|4.98066] "V" Host

BO_ 2626420741 BATT_diagnosticVBricksC_5: 8 Battery
 SG_ BATT_vBrick12_5 : 48|16@1+ (7.6e-05,0) [0|4.98066] "V" Host
 SG_ BATT_vBrick11_5 : 32|16@1+ (7.6e-05,0) [0|4.98066] "V" Host
 SG_ BATT_vBrick10_5 : 16|16@1+ (7.6e-05,0) [0|4.98066] "V" Host
 SG_ BATT_vBrick09_5 : 0|16@1+ (7.6e-05,0) [0|4.98066] "V" Host

BO_ 2626420742 BATT_diagnosticVBricksC_6: 8 Battery
 SG_ BATT_vBrick12_6 : 48|16@1+ (7.6e-05,0) [0|4.98066] "V" Host
 SG_ BATT_vBrick11_6 : 32|16@1+ (7.6e-05,0) [0|4.98066] "V" Host
 SG_ BATT_vBrick10_6 : 16|16@1+ (7.6e-05,0) [0|4.98066] "V" Host
 SG_ BATT_vBrick09_6 : 0|16@1+ (7.6e-05,0) [0|4.98066] "V" Host

BO_ 2626420743 BATT_diagnosticVBricksC_7: 8 Battery
 SG_ BATT_vBrick12_7 : 48|16@1+ (7.6e-05,0) [0|4.98066] "V" Host
 SG_ BATT_vBrick11_7 : 32|16@1+ (7.6e-05,0) [0|4.98066] "V" Host
 SG_ BATT_vBrick10_7 : 16|16@1+ (7.6e-05,0) [0|4.98066] "V" Host
 SG_ BATT_vBrick09_7 : 0|16@1+ (7.6e-05,0) [0|4.98066] "V" Host

BO_ 2626420744 BATT_diagnosticVBricksC_8: 8 Battery
 SG_ BATT_vBrick12_8 : 48|16@1+ (7.6e-05,0) [0|4.98066] "V" Host
 SG_ BATT_vBrick11_8 : 32|16@1+ (7.6e-05,0) [0|4.98066] "V" Host
 SG_ BATT_vBrick10_8 : 16|16@1+ (7.6e-05,0) [0|4.98066] "V" Host
 SG_ BATT_vBrick09_8 : 0|16@1+ (7.6e-05,0) [0|4.98066] "V" Host

BO_ 2626420745 BATT_diagnosticVBricksC_9: 8 Battery
 SG_ BATT_vBrick12_9 : 48|16@1+ (7.6e-05,0) [0|4.98066] "V" Host
 SG_ BATT_vBrick11_9 : 32|16@1+ (7.6e-05,0) [0|4.98066] "V" Host
 SG_ BATT_vBrick10_9 : 16|16@1+ (7.6e-05,0) [0|4.98066] "V" Host
 SG_ BATT_vBrick09_9 : 0|16@1+ (7.6e-05,0) [0|4.98066] "V" Host

BO_ 2626420746 BATT_diagnosticVBricksC_10: 8 Battery
 SG_ BATT_vBrick12_10 : 48|16@1+ (7.6e-05,0) [0|4.98066] "V" Host
 SG_ BATT_vBrick11_10 : 32|16@1+ (7.6e-05,0) [0|4.98066] "V" Host
 SG_ BATT_vBrick10_10 : 16|16@1+ (7.6e-05,0) [0|4.98066] "V" Host
 SG_ BATT_vBrick09_10 : 0|16@1+ (7.6e-05,0) [0|4.98066] "V" Host

BO_ 2626420747 BATT_diagnosticVBricksC_11: 8 Battery
 SG_ BATT_vBrick12_11 : 48|16@1+ (7.6e-05,0) [0|4.98066] "V" Host
 SG_ BATT_vBrick11_11 : 32|16@1+ (7.6e-05,0) [0|4.98066] "V" Host
 SG_ BATT_vBrick10_11 : 16|16@1+ (7.6e-05,0) [0|4.98066] "V" Host
 SG_ BATT_vBrick09_11 : 0|16@1+ (7.6e-05,0) [0|4.98066] "V" Host

BO_ 2626682880 BATT_diagnosticVBricksD_0: 4 Battery
 SG_ BATT_vBrick14_0 : 16|16@1+ (7.6e-05,0) [0|4.98066] "V" Host
 SG_ BATT_vBrick13_0 : 0|16@1+ (7.6e-05,0) [0|4.98066] "V" Host

BO_ 2626682881 BATT_diagnosticVBricksD_1: 4 Battery
 SG_ BATT_vBrick14_1 : 16|16@1+ (7.6e-05,0) [0|4.98066] "V" Host
 SG_ BATT_vBrick13_1 : 0|16@1+ (7.6e-05,0) [0|4.98066] "V" Host

BO_ 2626682882 BATT_diagnosticVBricksD_2: 4 Battery
 SG_ BATT_vBrick14_2 : 16|16@1+ (7.6e-05,0) [0|4.98066] "V" Host
 SG_ BATT_vBrick13_2 : 0|16@1+ (7.6e-05,0) [0|4.98066] "V" Host

BO_ 2626682883 BATT_diagnosticVBricksD_3: 4 Battery
 SG_ BATT_vBrick14_3 : 16|16@1+ (7.6e-05,0) [0|4.98066] "V" Host
 SG_ BATT_vBrick13_3 : 0|16@1+ (7.6e-05,0) [0|4.98066] "V" Host

BO_ 2626682884 BATT_diagnosticVBricksD_4: 4 Battery
 SG_ BATT_vBrick14_4 : 16|16@1+ (7.6e-05,0) [0|4.98066] "V" Host
 SG_ BATT_vBrick13_4 : 0|16@1+ (7.6e-05,0) [0|4.98066] "V" Host

BO_ 2626682885 BATT_diagnosticVBricksD_5: 4 Battery
 SG_ BATT_vBrick14_5 : 16|16@1+ (7.6e-05,0) [0|4.98066] "V" Host
 SG_ BATT_vBrick13_5 : 0|16@1+ (7.6e-05,0) [0|4.98066] "V" Host

BO_ 2626682886 BATT_diagnosticVBricksD_6: 4 Battery
 SG_ BATT_vBrick14_6 : 16|16@1+ (7.6e-05,0) [0|4.98066] "V" Host
 SG_ BATT_vBrick13_6 : 0|16@1+ (7.6e-05,0) [0|4.98066] "V" Host

BO_ 2626682887 BATT_diagnosticVBricksD_7: 4 Battery
 SG_ BATT_vBrick14_7 : 16|16@1+ (7.6e-05,0) [0|4.98066] "V" Host
 SG_ BATT_vBrick13_7 : 0|16@1+ (7.6e-05,0) [0|4.98066] "V" Host

BO_ 2626682888 BATT_diagnosticVBricksD_8: 4 Battery
 SG_ BATT_vBrick14_8 : 16|16@1+ (7.6e-05,0) [0|4.98066] "V" Host
 SG_ BATT_vBrick13_8 : 0|16@1+ (7.6e-05,0) [0|4.98066] "V" Host

BO_ 2626682889 BATT_diagnosticVBricksD_9: 4 Battery
 SG_ BATT_vBrick14_9 : 16|16@1+ (7.6e-05,0) [0|4.98066] "V" Host
 SG_ BATT_vBrick13_9 : 0|16@1+ (7.6e-05,0) [0|4.98066] "V" Host

BO_ 2626682890 BATT_diagnosticVBricksD_10: 4 Battery
 SG_ BATT_vBrick14_10 : 16|16@1+ (7.6e-05,0) [0|4.98066] "V" Host
 SG_ BATT_vBrick13_10 : 0|16@1+ (7.6e-05,0) [0|4.98066] "V" Host

BO_ 2626682891 BATT_diagnosticVBricksD_11: 4 Battery
 SG_ BATT_vBrick14_11 : 16|16@1+ (7.6e-05,0) [0|4.98066] "V" Host
 SG_ BATT_vBrick13_11 : 0|16@1+ (7.6e-05,0) [0|4.98066] "V" Host

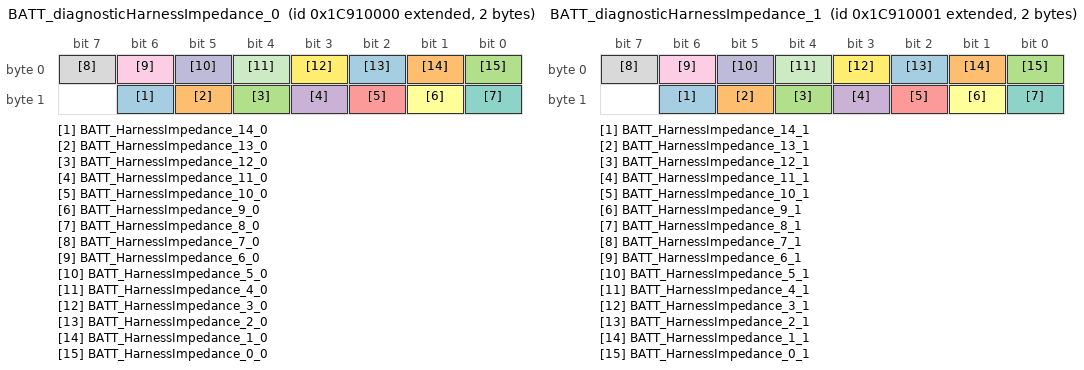
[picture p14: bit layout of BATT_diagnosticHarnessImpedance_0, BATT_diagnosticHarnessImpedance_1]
BO_ 2626748416 BATT_diagnosticHarnessImpedance_0: 2 Battery
 SG_ BATT_HarnessImpedance_14_0 : 14|1@1+ (1,0) [0|1] "mOhms" Host
 SG_ BATT_HarnessImpedance_13_0 : 13|1@1+ (1,0) [0|1] "mOhms" Host
 SG_ BATT_HarnessImpedance_12_0 : 12|1@1+ (1,0) [0|1] "mOhms" Host
 SG_ BATT_HarnessImpedance_11_0 : 11|1@1+ (1,0) [0|1] "mOhms" Host
 SG_ BATT_HarnessImpedance_10_0 : 10|1@1+ (1,0) [0|1] "mOhms" Host
 SG_ BATT_HarnessImpedance_9_0 : 9|1@1+ (1,0) [0|1] "mOhms" Host
 SG_ BATT_HarnessImpedance_8_0 : 8|1@1+ (1,0) [0|1] "mOhms" Host
 SG_ BATT_HarnessImpedance_7_0 : 7|1@1+ (1,0) [0|1] "mOhms" Host
 SG_ BATT_HarnessImpedance_6_0 : 6|1@1+ (1,0) [0|1] "mOhms" Host
 SG_ BATT_HarnessImpedance_5_0 : 5|1@1+ (1,0) [0|1] "mOhms" Host
 SG_ BATT_HarnessImpedance_4_0 : 4|1@1+ (1,0) [0|1] "mOhms" Host
 SG_ BATT_HarnessImpedance_3_0 : 3|1@1+ (1,0) [0|1] "mOhms" Host
 SG_ BATT_HarnessImpedance_2_0 : 2|1@1+ (1,0) [0|1] "mOhms" Host
 SG_ BATT_HarnessImpedance_1_0 : 1|1@1+ (1,0) [0|1] "mOhms" Host
 SG_ BATT_HarnessImpedance_0_0 : 0|1@1+ (1,0) [0|1] "mOhms" Host

BO_ 2626748417 BATT_diagnosticHarnessImpedance_1: 2 Battery
 SG_ BATT_HarnessImpedance_14_1 : 14|1@1+ (1,0) [0|1] "mOhms" Host
 SG_ BATT_HarnessImpedance_13_1 : 13|1@1+ (1,0) [0|1] "mOhms" Host
 SG_ BATT_HarnessImpedance_12_1 : 12|1@1+ (1,0) [0|1] "mOhms" Host
 SG_ BATT_HarnessImpedance_11_1 : 11|1@1+ (1,0) [0|1] "mOhms" Host
 SG_ BATT_HarnessImpedance_10_1 : 10|1@1+ (1,0) [0|1] "mOhms" Host
 SG_ BATT_HarnessImpedance_9_1 : 9|1@1+ (1,0) [0|1] "mOhms" Host
 SG_ BATT_HarnessImpedance_8_1 : 8|1@1+ (1,0) [0|1] "mOhms" Host
 SG_ BATT_HarnessImpedance_7_1 : 7|1@1+ (1,0) [0|1] "mOhms" Host
 SG_ BATT_HarnessImpedance_6_1 : 6|1@1+ (1,0) [0|1] "mOhms" Host
 SG_ BATT_HarnessImpedance_5_1 : 5|1@1+ (1,0) [0|1] "mOhms" Host
 SG_ BATT_HarnessImpedance_4_1 : 4|1@1+ (1,0) [0|1] "mOhms" Host
 SG_ BATT_HarnessImpedance_3_1 : 3|1@1+ (1,0) [0|1] "mOhms" Host
 SG_ BATT_HarnessImpedance_2_1 : 2|1@1+ (1,0) [0|1] "mOhms" Host
 SG_ BATT_HarnessImpedance_1_1 : 1|1@1+ (1,0) [0|1] "mOhms" Host
 SG_ BATT_HarnessImpedance_0_1 : 0|1@1+ (1,0) [0|1] "mOhms" Host

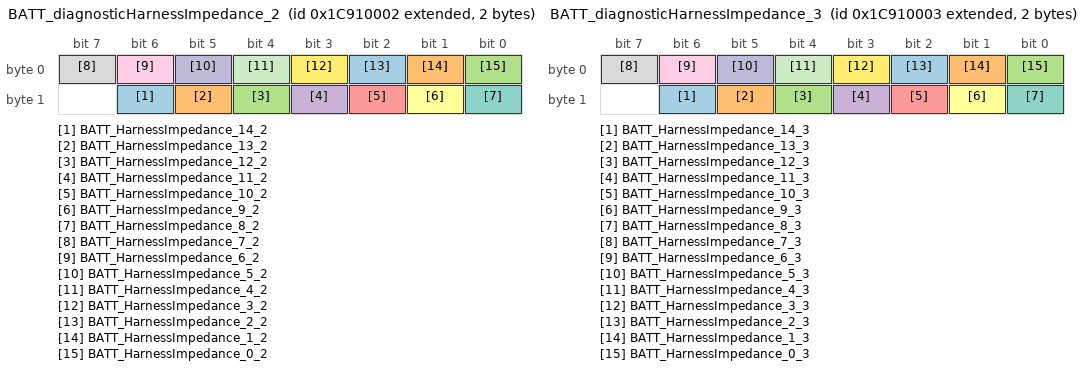
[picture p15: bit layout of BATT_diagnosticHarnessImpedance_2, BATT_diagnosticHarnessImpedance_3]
BO_ 2626748418 BATT_diagnosticHarnessImpedance_2: 2 Battery
 SG_ BATT_HarnessImpedance_14_2 : 14|1@1+ (1,0) [0|1] "mOhms" Host
 SG_ BATT_HarnessImpedance_13_2 : 13|1@1+ (1,0) [0|1] "mOhms" Host
 SG_ BATT_HarnessImpedance_12_2 : 12|1@1+ (1,0) [0|1] "mOhms" Host
 SG_ BATT_HarnessImpedance_11_2 : 11|1@1+ (1,0) [0|1] "mOhms" Host
 SG_ BATT_HarnessImpedance_10_2 : 10|1@1+ (1,0) [0|1] "mOhms" Host
 SG_ BATT_HarnessImpedance_9_2 : 9|1@1+ (1,0) [0|1] "mOhms" Host
 SG_ BATT_HarnessImpedance_8_2 : 8|1@1+ (1,0) [0|1] "mOhms" Host
 SG_ BATT_HarnessImpedance_7_2 : 7|1@1+ (1,0) [0|1] "mOhms" Host
 SG_ BATT_HarnessImpedance_6_2 : 6|1@1+ (1,0) [0|1] "mOhms" Host
 SG_ BATT_HarnessImpedance_5_2 : 5|1@1+ (1,0) [0|1] "mOhms" Host
 SG_ BATT_HarnessImpedance_4_2 : 4|1@1+ (1,0) [0|1] "mOhms" Host
 SG_ BATT_HarnessImpedance_3_2 : 3|1@1+ (1,0) [0|1] "mOhms" Host
 SG_ BATT_HarnessImpedance_2_2 : 2|1@1+ (1,0) [0|1] "mOhms" Host
 SG_ BATT_HarnessImpedance_1_2 : 1|1@1+ (1,0) [0|1] "mOhms" Host
 SG_ BATT_HarnessImpedance_0_2 : 0|1@1+ (1,0) [0|1] "mOhms" Host

BO_ 2626748419 BATT_diagnosticHarnessImpedance_3: 2 Battery
 SG_ BATT_HarnessImpedance_14_3 : 14|1@1+ (1,0) [0|1] "mOhms" Host
 SG_ BATT_HarnessImpedance_13_3 : 13|1@1+ (1,0) [0|1] "mOhms" Host
 SG_ BATT_HarnessImpedance_12_3 : 12|1@1+ (1,0) [0|1] "mOhms" Host
 SG_ BATT_HarnessImpedance_11_3 : 11|1@1+ (1,0) [0|1] "mOhms" Host
 SG_ BATT_HarnessImpedance_10_3 : 10|1@1+ (1,0) [0|1] "mOhms" Host
 SG_ BATT_HarnessImpedance_9_3 : 9|1@1+ (1,0) [0|1] "mOhms" Host
 SG_ BATT_HarnessImpedance_8_3 : 8|1@1+ (1,0) [0|1] "mOhms" Host
 SG_ BATT_HarnessImpedance_7_3 : 7|1@1+ (1,0) [0|1] "mOhms" Host
 SG_ BATT_HarnessImpedance_6_3 : 6|1@1+ (1,0) [0|1] "mOhms" Host
 SG_ BATT_HarnessImpedance_5_3 : 5|1@1+ (1,0) [0|1] "mOhms" Host
 SG_ BATT_HarnessImpedance_4_3 : 4|1@1+ (1,0) [0|1] "mOhms" Host
 SG_ BATT_HarnessImpedance_3_3 : 3|1@1+ (1,0) [0|1] "mOhms" Host
 SG_ BATT_HarnessImpedance_2_3 : 2|1@1+ (1,0) [0|1] "mOhms" Host
 SG_ BATT_HarnessImpedance_1_3 : 1|1@1+ (1,0) [0|1] "mOhms" Host
 SG_ BATT_HarnessImpedance_0_3 : 0|1@1+ (1,0) [0|1] "mOhms" Host

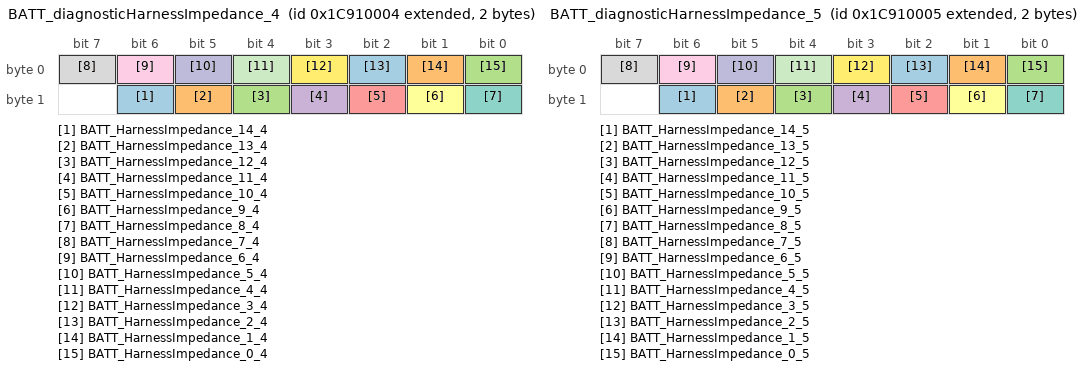
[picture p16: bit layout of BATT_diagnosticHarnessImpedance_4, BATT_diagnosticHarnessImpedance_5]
BO_ 2626748420 BATT_diagnosticHarnessImpedance_4: 2 Battery
 SG_ BATT_HarnessImpedance_14_4 : 14|1@1+ (1,0) [0|1] "mOhms" Host
 SG_ BATT_HarnessImpedance_13_4 : 13|1@1+ (1,0) [0|1] "mOhms" Host
 SG_ BATT_HarnessImpedance_12_4 : 12|1@1+ (1,0) [0|1] "mOhms" Host
 SG_ BATT_HarnessImpedance_11_4 : 11|1@1+ (1,0) [0|1] "mOhms" Host
 SG_ BATT_HarnessImpedance_10_4 : 10|1@1+ (1,0) [0|1] "mOhms" Host
 SG_ BATT_HarnessImpedance_9_4 : 9|1@1+ (1,0) [0|1] "mOhms" Host
 SG_ BATT_HarnessImpedance_8_4 : 8|1@1+ (1,0) [0|1] "mOhms" Host
 SG_ BATT_HarnessImpedance_7_4 : 7|1@1+ (1,0) [0|1] "mOhms" Host
 SG_ BATT_HarnessImpedance_6_4 : 6|1@1+ (1,0) [0|1] "mOhms" Host
 SG_ BATT_HarnessImpedance_5_4 : 5|1@1+ (1,0) [0|1] "mOhms" Host
 SG_ BATT_HarnessImpedance_4_4 : 4|1@1+ (1,0) [0|1] "mOhms" Host
 SG_ BATT_HarnessImpedance_3_4 : 3|1@1+ (1,0) [0|1] "mOhms" Host
 SG_ BATT_HarnessImpedance_2_4 : 2|1@1+ (1,0) [0|1] "mOhms" Host
 SG_ BATT_HarnessImpedance_1_4 : 1|1@1+ (1,0) [0|1] "mOhms" Host
 SG_ BATT_HarnessImpedance_0_4 : 0|1@1+ (1,0) [0|1] "mOhms" Host

BO_ 2626748421 BATT_diagnosticHarnessImpedance_5: 2 Battery
 SG_ BATT_HarnessImpedance_14_5 : 14|1@1+ (1,0) [0|1] "mOhms" Host
 SG_ BATT_HarnessImpedance_13_5 : 13|1@1+ (1,0) [0|1] "mOhms" Host
 SG_ BATT_HarnessImpedance_12_5 : 12|1@1+ (1,0) [0|1] "mOhms" Host
 SG_ BATT_HarnessImpedance_11_5 : 11|1@1+ (1,0) [0|1] "mOhms" Host
 SG_ BATT_HarnessImpedance_10_5 : 10|1@1+ (1,0) [0|1] "mOhms" Host
 SG_ BATT_HarnessImpedance_9_5 : 9|1@1+ (1,0) [0|1] "mOhms" Host
 SG_ BATT_HarnessImpedance_8_5 : 8|1@1+ (1,0) [0|1] "mOhms" Host
 SG_ BATT_HarnessImpedance_7_5 : 7|1@1+ (1,0) [0|1] "mOhms" Host
 SG_ BATT_HarnessImpedance_6_5 : 6|1@1+ (1,0) [0|1] "mOhms" Host
 SG_ BATT_HarnessImpedance_5_5 : 5|1@1+ (1,0) [0|1] "mOhms" Host
 SG_ BATT_HarnessImpedance_4_5 : 4|1@1+ (1,0) [0|1] "mOhms" Host
 SG_ BATT_HarnessImpedance_3_5 : 3|1@1+ (1,0) [0|1] "mOhms" Host
 SG_ BATT_HarnessImpedance_2_5 : 2|1@1+ (1,0) [0|1] "mOhms" Host
 SG_ BATT_HarnessImpedance_1_5 : 1|1@1+ (1,0) [0|1] "mOhms" Host
 SG_ BATT_HarnessImpedance_0_5 : 0|1@1+ (1,0) [0|1] "mOhms" Host

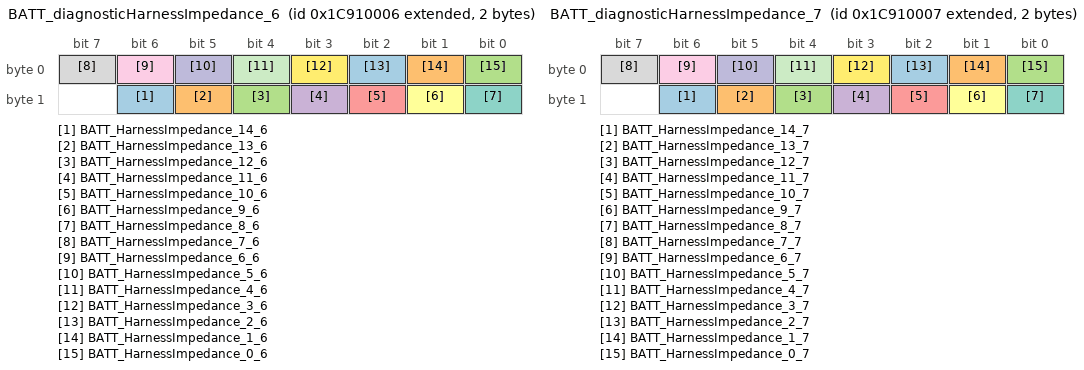
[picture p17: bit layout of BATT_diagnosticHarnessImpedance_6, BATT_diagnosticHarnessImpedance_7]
BO_ 2626748422 BATT_diagnosticHarnessImpedance_6: 2 Battery
 SG_ BATT_HarnessImpedance_14_6 : 14|1@1+ (1,0) [0|1] "mOhms" Host
 SG_ BATT_HarnessImpedance_13_6 : 13|1@1+ (1,0) [0|1] "mOhms" Host
 SG_ BATT_HarnessImpedance_12_6 : 12|1@1+ (1,0) [0|1] "mOhms" Host
 SG_ BATT_HarnessImpedance_11_6 : 11|1@1+ (1,0) [0|1] "mOhms" Host
 SG_ BATT_HarnessImpedance_10_6 : 10|1@1+ (1,0) [0|1] "mOhms" Host
 SG_ BATT_HarnessImpedance_9_6 : 9|1@1+ (1,0) [0|1] "mOhms" Host
 SG_ BATT_HarnessImpedance_8_6 : 8|1@1+ (1,0) [0|1] "mOhms" Host
 SG_ BATT_HarnessImpedance_7_6 : 7|1@1+ (1,0) [0|1] "mOhms" Host
 SG_ BATT_HarnessImpedance_6_6 : 6|1@1+ (1,0) [0|1] "mOhms" Host
 SG_ BATT_HarnessImpedance_5_6 : 5|1@1+ (1,0) [0|1] "mOhms" Host
 SG_ BATT_HarnessImpedance_4_6 : 4|1@1+ (1,0) [0|1] "mOhms" Host
 SG_ BATT_HarnessImpedance_3_6 : 3|1@1+ (1,0) [0|1] "mOhms" Host
 SG_ BATT_HarnessImpedance_2_6 : 2|1@1+ (1,0) [0|1] "mOhms" Host
 SG_ BATT_HarnessImpedance_1_6 : 1|1@1+ (1,0) [0|1] "mOhms" Host
 SG_ BATT_HarnessImpedance_0_6 : 0|1@1+ (1,0) [0|1] "mOhms" Host

BO_ 2626748423 BATT_diagnosticHarnessImpedance_7: 2 Battery
 SG_ BATT_HarnessImpedance_14_7 : 14|1@1+ (1,0) [0|1] "mOhms" Host
 SG_ BATT_HarnessImpedance_13_7 : 13|1@1+ (1,0) [0|1] "mOhms" Host
 SG_ BATT_HarnessImpedance_12_7 : 12|1@1+ (1,0) [0|1] "mOhms" Host
 SG_ BATT_HarnessImpedance_11_7 : 11|1@1+ (1,0) [0|1] "mOhms" Host
 SG_ BATT_HarnessImpedance_10_7 : 10|1@1+ (1,0) [0|1] "mOhms" Host
 SG_ BATT_HarnessImpedance_9_7 : 9|1@1+ (1,0) [0|1] "mOhms" Host
 SG_ BATT_HarnessImpedance_8_7 : 8|1@1+ (1,0) [0|1] "mOhms" Host
 SG_ BATT_HarnessImpedance_7_7 : 7|1@1+ (1,0) [0|1] "mOhms" Host
 SG_ BATT_HarnessImpedance_6_7 : 6|1@1+ (1,0) [0|1] "mOhms" Host
 SG_ BATT_HarnessImpedance_5_7 : 5|1@1+ (1,0) [0|1] "mOhms" Host
 SG_ BATT_HarnessImpedance_4_7 : 4|1@1+ (1,0) [0|1] "mOhms" Host
 SG_ BATT_HarnessImpedance_3_7 : 3|1@1+ (1,0) [0|1] "mOhms" Host
 SG_ BATT_HarnessImpedance_2_7 : 2|1@1+ (1,0) [0|1] "mOhms" Host
 SG_ BATT_HarnessImpedance_1_7 : 1|1@1+ (1,0) [0|1] "mOhms" Host
 SG_ BATT_HarnessImpedance_0_7 : 0|1@1+ (1,0) [0|1] "mOhms" Host

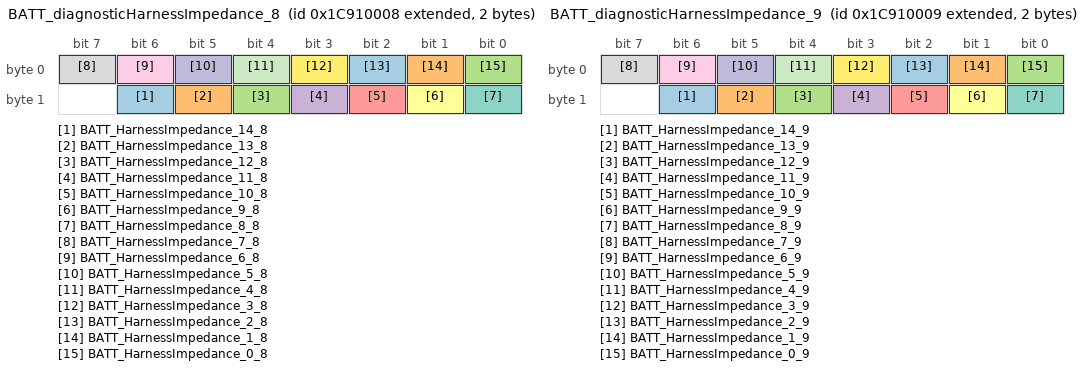
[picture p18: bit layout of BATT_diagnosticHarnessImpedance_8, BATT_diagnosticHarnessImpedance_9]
BO_ 2626748424 BATT_diagnosticHarnessImpedance_8: 2 Battery
 SG_ BATT_HarnessImpedance_14_8 : 14|1@1+ (1,0) [0|1] "mOhms" Host
 SG_ BATT_HarnessImpedance_13_8 : 13|1@1+ (1,0) [0|1] "mOhms" Host
 SG_ BATT_HarnessImpedance_12_8 : 12|1@1+ (1,0) [0|1] "mOhms" Host
 SG_ BATT_HarnessImpedance_11_8 : 11|1@1+ (1,0) [0|1] "mOhms" Host
 SG_ BATT_HarnessImpedance_10_8 : 10|1@1+ (1,0) [0|1] "mOhms" Host
 SG_ BATT_HarnessImpedance_9_8 : 9|1@1+ (1,0) [0|1] "mOhms" Host
 SG_ BATT_HarnessImpedance_8_8 : 8|1@1+ (1,0) [0|1] "mOhms" Host
 SG_ BATT_HarnessImpedance_7_8 : 7|1@1+ (1,0) [0|1] "mOhms" Host
 SG_ BATT_HarnessImpedance_6_8 : 6|1@1+ (1,0) [0|1] "mOhms" Host
 SG_ BATT_HarnessImpedance_5_8 : 5|1@1+ (1,0) [0|1] "mOhms" Host
 SG_ BATT_HarnessImpedance_4_8 : 4|1@1+ (1,0) [0|1] "mOhms" Host
 SG_ BATT_HarnessImpedance_3_8 : 3|1@1+ (1,0) [0|1] "mOhms" Host
 SG_ BATT_HarnessImpedance_2_8 : 2|1@1+ (1,0) [0|1] "mOhms" Host
 SG_ BATT_HarnessImpedance_1_8 : 1|1@1+ (1,0) [0|1] "mOhms" Host
 SG_ BATT_HarnessImpedance_0_8 : 0|1@1+ (1,0) [0|1] "mOhms" Host

BO_ 2626748425 BATT_diagnosticHarnessImpedance_9: 2 Battery
 SG_ BATT_HarnessImpedance_14_9 : 14|1@1+ (1,0) [0|1] "mOhms" Host
 SG_ BATT_HarnessImpedance_13_9 : 13|1@1+ (1,0) [0|1] "mOhms" Host
 SG_ BATT_HarnessImpedance_12_9 : 12|1@1+ (1,0) [0|1] "mOhms" Host
 SG_ BATT_HarnessImpedance_11_9 : 11|1@1+ (1,0) [0|1] "mOhms" Host
 SG_ BATT_HarnessImpedance_10_9 : 10|1@1+ (1,0) [0|1] "mOhms" Host
 SG_ BATT_HarnessImpedance_9_9 : 9|1@1+ (1,0) [0|1] "mOhms" Host
 SG_ BATT_HarnessImpedance_8_9 : 8|1@1+ (1,0) [0|1] "mOhms" Host
 SG_ BATT_HarnessImpedance_7_9 : 7|1@1+ (1,0) [0|1] "mOhms" Host
 SG_ BATT_HarnessImpedance_6_9 : 6|1@1+ (1,0) [0|1] "mOhms" Host
 SG_ BATT_HarnessImpedance_5_9 : 5|1@1+ (1,0) [0|1] "mOhms" Host
 SG_ BATT_HarnessImpedance_4_9 : 4|1@1+ (1,0) [0|1] "mOhms" Host
 SG_ BATT_HarnessImpedance_3_9 : 3|1@1+ (1,0) [0|1] "mOhms" Host
 SG_ BATT_HarnessImpedance_2_9 : 2|1@1+ (1,0) [0|1] "mOhms" Host
 SG_ BATT_HarnessImpedance_1_9 : 1|1@1+ (1,0) [0|1] "mOhms" Host
 SG_ BATT_HarnessImpedance_0_9 : 0|1@1+ (1,0) [0|1] "mOhms" Host

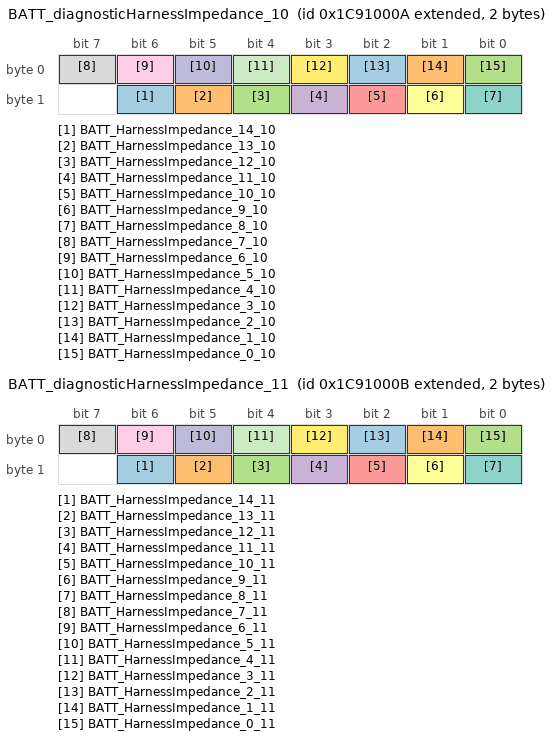
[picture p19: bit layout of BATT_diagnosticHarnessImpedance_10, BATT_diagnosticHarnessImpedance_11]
BO_ 2626748426 BATT_diagnosticHarnessImpedance_10: 2 Battery
 SG_ BATT_HarnessImpedance_14_10 : 14|1@1+ (1,0) [0|1] "mOhms" Host
 SG_ BATT_HarnessImpedance_13_10 : 13|1@1+ (1,0) [0|1] "mOhms" Host
 SG_ BATT_HarnessImpedance_12_10 : 12|1@1+ (1,0) [0|1] "mOhms" Host
 SG_ BATT_HarnessImpedance_11_10 : 11|1@1+ (1,0) [0|1] "mOhms" Host
 SG_ BATT_HarnessImpedance_10_10 : 10|1@1+ (1,0) [0|1] "mOhms" Host
 SG_ BATT_HarnessImpedance_9_10 : 9|1@1+ (1,0) [0|1] "mOhms" Host
 SG_ BATT_HarnessImpedance_8_10 : 8|1@1+ (1,0) [0|1] "mOhms" Host
 SG_ BATT_HarnessImpedance_7_10 : 7|1@1+ (1,0) [0|1] "mOhms" Host
 SG_ BATT_HarnessImpedance_6_10 : 6|1@1+ (1,0) [0|1] "mOhms" Host
 SG_ BATT_HarnessImpedance_5_10 : 5|1@1+ (1,0) [0|1] "mOhms" Host
 SG_ BATT_HarnessImpedance_4_10 : 4|1@1+ (1,0) [0|1] "mOhms" Host
 SG_ BATT_HarnessImpedance_3_10 : 3|1@1+ (1,0) [0|1] "mOhms" Host
 SG_ BATT_HarnessImpedance_2_10 : 2|1@1+ (1,0) [0|1] "mOhms" Host
 SG_ BATT_HarnessImpedance_1_10 : 1|1@1+ (1,0) [0|1] "mOhms" Host
 SG_ BATT_HarnessImpedance_0_10 : 0|1@1+ (1,0) [0|1] "mOhms" Host

BO_ 2626748427 BATT_diagnosticHarnessImpedance_11: 2 Battery
 SG_ BATT_HarnessImpedance_14_11 : 14|1@1+ (1,0) [0|1] "mOhms" Host
 SG_ BATT_HarnessImpedance_13_11 : 13|1@1+ (1,0) [0|1] "mOhms" Host
 SG_ BATT_HarnessImpedance_12_11 : 12|1@1+ (1,0) [0|1] "mOhms" Host
 SG_ BATT_HarnessImpedance_11_11 : 11|1@1+ (1,0) [0|1] "mOhms" Host
 SG_ BATT_HarnessImpedance_10_11 : 10|1@1+ (1,0) [0|1] "mOhms" Host
 SG_ BATT_HarnessImpedance_9_11 : 9|1@1+ (1,0) [0|1] "mOhms" Host
 SG_ BATT_HarnessImpedance_8_11 : 8|1@1+ (1,0) [0|1] "mOhms" Host
 SG_ BATT_HarnessImpedance_7_11 : 7|1@1+ (1,0) [0|1] "mOhms" Host
 SG_ BATT_HarnessImpedance_6_11 : 6|1@1+ (1,0) [0|1] "mOhms" Host
 SG_ BATT_HarnessImpedance_5_11 : 5|1@1+ (1,0) [0|1] "mOhms" Host
 SG_ BATT_HarnessImpedance_4_11 : 4|1@1+ (1,0) [0|1] "mOhms" Host
 SG_ BATT_HarnessImpedance_3_11 : 3|1@1+ (1,0) [0|1] "mOhms" Host
 SG_ BATT_HarnessImpedance_2_11 : 2|1@1+ (1,0) [0|1] "mOhms" Host
 SG_ BATT_HarnessImpedance_1_11 : 1|1@1+ (1,0) [0|1] "mOhms" Host
 SG_ BATT_HarnessImpedance_0_11 : 0|1@1+ (1,0) [0|1] "mOhms" Host

BO_ 2626813952 BATT_diagnosticHrnsImpDleta_0_0: 8 Battery
 SG_ BATT_HrnsImpDelta_3_0 : 48|16@1- (0.001,0) [-32.768|32.767] "mV" Host
 SG_ BATT_HrnsImpDelta_2_0 : 32|16@1- (0.001,0) [-32.768|32.767] "mV" Host
 SG_ BATT_HrnsImpDelta_1_0 : 16|16@1- (0.001,0) [-32.768|32.767] "mV" Host
 SG_ BATT_HrnsImpDelta_0_0 : 0|16@1- (0.001,0) [-32.768|32.767] "mV" Host

BO_ 2626813953 BATT_diagnosticHrnsImpDleta_0_1: 8 Battery
 SG_ BATT_HrnsImpDelta_3_1 : 48|16@1- (0.001,0) [-32.768|32.767] "mV" Host
 SG_ BATT_HrnsImpDelta_2_1 : 32|16@1- (0.001,0) [-32.768|32.767] "mV" Host
 SG_ BATT_HrnsImpDelta_1_1 : 16|16@1- (0.001,0) [-32.768|32.767] "mV" Host
 SG_ BATT_HrnsImpDelta_0_1 : 0|16@1- (0.001,0) [-32.768|32.767] "mV" Host

BO_ 2626813954 BATT_diagnosticHrnsImpDleta_0_2: 8 Battery
 SG_ BATT_HrnsImpDelta_3_2 : 48|16@1- (0.001,0) [-32.768|32.767] "mV" Host
 SG_ BATT_HrnsImpDelta_2_2 : 32|16@1- (0.001,0) [-32.768|32.767] "mV" Host
 SG_ BATT_HrnsImpDelta_1_2 : 16|16@1- (0.001,0) [-32.768|32.767] "mV" Host
 SG_ BATT_HrnsImpDelta_0_2 : 0|16@1- (0.001,0) [-32.768|32.767] "mV" Host

BO_ 2626813955 BATT_diagnosticHrnsImpDleta_0_3: 8 Battery
 SG_ BATT_HrnsImpDelta_3_3 : 48|16@1- (0.001,0) [-32.768|32.767] "mV" Host
 SG_ BATT_HrnsImpDelta_2_3 : 32|16@1- (0.001,0) [-32.768|32.767] "mV" Host
 SG_ BATT_HrnsImpDelta_1_3 : 16|16@1- (0.001,0) [-32.768|32.767] "mV" Host
 SG_ BATT_HrnsImpDelta_0_3 : 0|16@1- (0.001,0) [-32.768|32.767] "mV" Host

BO_ 2626813956 BATT_diagnosticHrnsImpDleta_0_4: 8 Battery
 SG_ BATT_HrnsImpDelta_3_4 : 48|16@1- (0.001,0) [-32.768|32.767] "mV" Host
 SG_ BATT_HrnsImpDelta_2_4 : 32|16@1- (0.001,0) [-32.768|32.767] "mV" Host
 SG_ BATT_HrnsImpDelta_1_4 : 16|16@1- (0.001,0) [-32.768|32.767] "mV" Host
 SG_ BATT_HrnsImpDelta_0_4 : 0|16@1- (0.001,0) [-32.768|32.767] "mV" Host

BO_ 2626813957 BATT_diagnosticHrnsImpDleta_0_5: 8 Battery
 SG_ BATT_HrnsImpDelta_3_5 : 48|16@1- (0.001,0) [-32.768|32.767] "mV" Host
 SG_ BATT_HrnsImpDelta_2_5 : 32|16@1- (0.001,0) [-32.768|32.767] "mV" Host
 SG_ BATT_HrnsImpDelta_1_5 : 16|16@1- (0.001,0) [-32.768|32.767] "mV" Host
 SG_ BATT_HrnsImpDelta_0_5 : 0|16@1- (0.001,0) [-32.768|32.767] "mV" Host

CM_ BO_ 2621702151 "Capacity of bricks 1-4";
CM_ SG_ 2621702151 BATT_capBrick04_7 "Capacity of brick 4";
CM_ SG_ 2621702151 BATT_capBrick03_7 "Capacity of brick 3";
CM_ SG_ 2621702151 BATT_capBrick02_7 "Capacity of brick 2";
CM_ SG_ 2621702151 BATT_capBrick01_7 "Capacity of brick 1";
CM_ BO_ 2621702152 "Capacity of bricks 1-4";
CM_ SG_ 2621702152 BATT_capBrick04_8 "Capacity of brick 4";
CM_ SG_ 2621702152 BATT_capBrick03_8 "Capacity of brick 3";
CM_ SG_ 2621702152 BATT_capBrick02_8 "Capacity of brick 2";
CM_ SG_ 2621702152 BATT_capBrick01_8 "Capacity of brick 1";
CM_ BO_ 2621702153 "Capacity of bricks 1-4";
CM_ SG_ 2621702153 BATT_capBrick04_9 "Capacity of brick 4";
CM_ SG_ 2621702153 BATT_capBrick03_9 "Capacity of brick 3";
CM_ SG_ 2621702153 BATT_capBrick02_9 "Capacity of brick 2";
CM_ SG_ 2621702153 BATT_capBrick01_9 "Capacity of brick 1";
CM_ BO_ 2621702154 "Capacity of bricks 1-4";
CM_ SG_ 2621702154 BATT_capBrick04_10 "Capacity of brick 4";
CM_ SG_ 2621702154 BATT_capBrick03_10 "Capacity of brick 3";
CM_ SG_ 2621702154 BATT_capBrick02_10 "Capacity of brick 2";
CM_ SG_ 2621702154 BATT_capBrick01_10 "Capacity of brick 1";
CM_ BO_ 2621702155 "Capacity of bricks 1-4";
CM_ SG_ 2621702155 BATT_capBrick04_11 "Capacity of brick 4";
CM_ SG_ 2621702155 BATT_capBrick03_11 "Capacity of brick 3";
CM_ SG_ 2621702155 BATT_capBrick02_11 "Capacity of brick 2";
CM_ SG_ 2621702155 BATT_capBrick01_11 "Capacity of brick 1";
CM_ BO_ 2621964288 "Capacity of bricks 5-8";
CM_ SG_ 2621964288 BATT_capBrick08_0 "Capacity of brick 8";
CM_ SG_ 2621964288 BATT_capBrick07_0 "Capacity of brick 7";
CM_ SG_ 2621964288 BATT_capBrick06_0 "Capacity of brick 6";
CM_ SG_ 2621964288 BATT_capBrick05_0 "Capacity of brick 5";
CM_ BO_ 2621964289 "Capacity of bricks 5-8";
CM_ SG_ 2621964289 BATT_capBrick08_1 "Capacity of brick 8";
CM_ SG_ 2621964289 BATT_capBrick07_1 "Capacity of brick 7";
CM_ SG_ 2621964289 BATT_capBrick06_1 "Capacity of brick 6";
CM_ SG_ 2621964289 BATT_capBrick05_1 "Capacity of brick 5";
CM_ BO_ 2621964290 "Capacity of bricks 5-8";
CM_ SG_ 2621964290 BATT_capBrick08_2 "Capacity of brick 8";
CM_ SG_ 2621964290 BATT_capBrick07_2 "Capacity of brick 7";
CM_ SG_ 2621964290 BATT_capBrick06_2 "Capacity of brick 6";
CM_ SG_ 2621964290 BATT_capBrick05_2 "Capacity of brick 5";
CM_ BO_ 2621964291 "Capacity of bricks 5-8";
CM_ SG_ 2621964291 BATT_capBrick08_3 "Capacity of brick 8";
CM_ SG_ 2621964291 BATT_capBrick07_3 "Capacity of brick 7";
CM_ SG_ 2621964291 BATT_capBrick06_3 "Capacity of brick 6";
CM_ SG_ 2621964291 BATT_capBrick05_3 "Capacity of brick 5";
CM_ BO_ 2621964292 "Capacity of bricks 5-8";
CM_ SG_ 2621964292 BATT_capBrick08_4 "Capacity of brick 8";
CM_ SG_ 2621964292 BATT_capBrick07_4 "Capacity of brick 7";
CM_ SG_ 2621964292 BATT_capBrick06_4 "Capacity of brick 6";
CM_ SG_ 2621964292 BATT_capBrick05_4 "Capacity of brick 5";
CM_ BO_ 2621964293 "Capacity of bricks 5-8";
CM_ SG_ 2621964293 BATT_capBrick08_5 "Capacity of brick 8";
CM_ SG_ 2621964293 BATT_capBrick07_5 "Capacity of brick 7";
CM_ SG_ 2621964293 BATT_capBrick06_5 "Capacity of brick 6";
CM_ SG_ 2621964293 BATT_capBrick05_5 "Capacity of brick 5";
CM_ BO_ 2621964294 "Capacity of bricks 5-8";
CM_ SG_ 2621964294 BATT_capBrick08_6 "Capacity of brick 8";
CM_ SG_ 2621964294 BATT_capBrick07_6 "Capacity of brick 7";
CM_ SG_ 2621964294 BATT_capBrick06_6 "Capacity of brick 6";
CM_ SG_ 2621964294 BATT_capBrick05_6 "Capacity of brick 5";
CM_ BO_ 2621964295 "Capacity of bricks 5-8";
CM_ SG_ 2621964295 BATT_capBrick08_7 "Capacity of brick 8";
CM_ SG_ 2621964295 BATT_capBrick07_7 "Capacity of brick 7";
CM_ SG_ 2621964295 BATT_capBrick06_7 "Capacity of brick 6";
CM_ SG_ 2621964295 BATT_capBrick05_7 "Capacity of brick 5";
CM_ BO_ 2621964296 "Capacity of bricks 5-8";
CM_ SG_ 2621964296 BATT_capBrick08_8 "Capacity of brick 8";
CM_ SG_ 2621964296 BATT_capBrick07_8 "Capacity of brick 7";
CM_ SG_ 2621964296 BATT_capBrick06_8 "Capacity of brick 6";
CM_ SG_ 2621964296 BATT_capBrick05_8 "Capacity of brick 5";
CM_ BO_ 2621964297 "Capacity of bricks 5-8";
CM_ SG_ 2621964297 BATT_capBrick08_9 "Capacity of brick 8";
CM_ SG_ 2621964297 BATT_capBrick07_9 "Capacity of brick 7";
CM_ SG_ 2621964297 BATT_capBrick06_9 "Capacity of brick 6";
CM_ SG_ 2621964297 BATT_capBrick05_9 "Capacity of brick 5";
CM_ BO_ 2621964298 "Capacity of bricks 5-8";
CM_ SG_ 2621964298 BATT_capBrick08_10 "Capacity of brick 8";
CM_ SG_ 2621964298 BATT_capBrick07_10 "Capacity of brick 7";
CM_ SG_ 2621964298 BATT_capBrick06_10 "Capacity of brick 6";
CM_ SG_ 2621964298 BATT_capBrick05_10 "Capacity of brick 5";
CM_ BO_ 2621964299 "Capacity of bricks 5-8";
CM_ SG_ 2621964299 BATT_capBrick08_11 "Capacity of brick 8";
CM_ SG_ 2621964299 BATT_capBrick07_11 "Capacity of brick 7";
CM_ SG_ 2621964299 BATT_capBrick06_11 "Capacity of brick 6";
CM_ SG_ 2621964299 BATT_capBrick05_11 "Capacity of brick 5";
CM_ BO_ 2622226432 "Capacity of bricks 9-12";
CM_ SG_ 2622226432 BATT_capBrick12_0 "Capacity of brick 12";
CM_ SG_ 2622226432 BATT_capBrick11_0 "Capacity of brick 11";
CM_ SG_ 2622226432 BATT_capBrick09_0 "Capacity of brick 9";
CM_ SG_ 2622226432 BATT_capBrick10_0 "Capacity of brick 10";
CM_ BO_ 2622226433 "Capacity of bricks 9-12";
CM_ SG_ 2622226433 BATT_capBrick12_1 "Capacity of brick 12";
CM_ SG_ 2622226433 BATT_capBrick11_1 "Capacity of brick 11";
CM_ SG_ 2622226433 BATT_capBrick09_1 "Capacity of brick 9";
CM_ SG_ 2622226433 BATT_capBrick10_1 "Capacity of brick 10";
CM_ BO_ 2622226434 "Capacity of bricks 9-12";
CM_ SG_ 2622226434 BATT_capBrick12_2 "Capacity of brick 12";
CM_ SG_ 2622226434 BATT_capBrick11_2 "Capacity of brick 11";
CM_ SG_ 2622226434 BATT_capBrick09_2 "Capacity of brick 9";
CM_ SG_ 2622226434 BATT_capBrick10_2 "Capacity of brick 10";
CM_ BO_ 2622226435 "Capacity of bricks 9-12";
CM_ SG_ 2622226435 BATT_capBrick12_3 "Capacity of brick 12";
CM_ SG_ 2622226435 BATT_capBrick11_3 "Capacity of brick 11";
CM_ SG_ 2622226435 BATT_capBrick09_3 "Capacity of brick 9";
CM_ SG_ 2622226435 BATT_capBrick10_3 "Capacity of brick 10";
CM_ BO_ 2622226436 "Capacity of bricks 9-12";
CM_ SG_ 2622226436 BATT_capBrick12_4 "Capacity of brick 12";
CM_ SG_ 2622226436 BATT_capBrick11_4 "Capacity of brick 11";
CM_ SG_ 2622226436 BATT_capBrick09_4 "Capacity of brick 9";
CM_ SG_ 2622226436 BATT_capBrick10_4 "Capacity of brick 10";
CM_ BO_ 2622226437 "Capacity of bricks 9-12";
CM_ SG_ 2622226437 BATT_capBrick12_5 "Capacity of brick 12";
CM_ SG_ 2622226437 BATT_capBrick11_5 "Capacity of brick 11";
CM_ SG_ 2622226437 BATT_capBrick09_5 "Capacity of brick 9";
CM_ SG_ 2622226437 BATT_capBrick10_5 "Capacity of brick 10";
CM_ BO_ 2622226438 "Capacity of bricks 9-12";
CM_ SG_ 2622226438 BATT_capBrick12_6 "Capacity of brick 12";
CM_ SG_ 2622226438 BATT_capBrick11_6 "Capacity of brick 11";
CM_ SG_ 2622226438 BATT_capBrick09_6 "Capacity of brick 9";
CM_ SG_ 2622226438 BATT_capBrick10_6 "Capacity of brick 10";
CM_ BO_ 2622226439 "Capacity of bricks 9-12";
CM_ SG_ 2622226439 BATT_capBrick12_7 "Capacity of brick 12";
CM_ SG_ 2622226439 BATT_capBrick11_7 "Capacity of brick 11";
CM_ SG_ 2622226439 BATT_capBrick09_7 "Capacity of brick 9";
CM_ SG_ 2622226439 BATT_capBrick10_7 "Capacity of brick 10";
CM_ BO_ 2622226440 "Capacity of bricks 9-12";
CM_ SG_ 2622226440 BATT_capBrick12_8 "Capacity of brick 12";
CM_ SG_ 2622226440 BATT_capBrick11_8 "Capacity of brick 11";
CM_ SG_ 2622226440 BATT_capBrick09_8 "Capacity of brick 9";
CM_ SG_ 2622226440 BATT_capBrick10_8 "Capacity of brick 10";
CM_ BO_ 2622226441 "Capacity of bricks 9-12";
CM_ SG_ 2622226441 BATT_capBrick12_9 "Capacity of brick 12";
CM_ SG_ 2622226441 BATT_capBrick11_9 "Capacity of brick 11";
CM_ SG_ 2622226441 BATT_capBrick09_9 "Capacity of brick 9";
CM_ SG_ 2622226441 BATT_capBrick10_9 "Capacity of brick 10";
CM_ BO_ 2622226442 "Capacity of bricks 9-12";
CM_ SG_ 2622226442 BATT_capBrick12_10 "Capacity of brick 12";
CM_ SG_ 2622226442 BATT_capBrick11_10 "Capacity of brick 11";
CM_ SG_ 2622226442 BATT_capBrick09_10 "Capacity of brick 9";
CM_ SG_ 2622226442 BATT_capBrick10_10 "Capacity of brick 10";
CM_ BO_ 2622226443 "Capacity of bricks 9-12";
CM_ SG_ 2622226443 BATT_capBrick12_11 "Capacity of brick 12";
CM_ SG_ 2622226443 BATT_capBrick11_11 "Capacity of brick 11";
CM_ SG_ 2622226443 BATT_capBrick09_11 "Capacity of brick 9";
CM_ SG_ 2622226443 BATT_capBrick10_11 "Capacity of brick 10";
CM_ BO_ 2622488576 "Capacity of bricks 13-14";
CM_ SG_ 2622488576 BATT_sohcUpdated_0 "SOHC Updated Mask";
CM_ SG_ 2622488576 BATT_sohcPrimed_0 "SOHC Primed Mask";
CM_ SG_ 2622488576 BATT_capBrick14_0 "Capacity of brick 14";
CM_ SG_ 2622488576 BATT_capBrick13_0 "Capacity of brick 13";
CM_ BO_ 2622488577 "Capacity of bricks 13-14";
CM_ SG_ 2622488577 BATT_sohcUpdated_1 "SOHC Updated Mask";
CM_ SG_ 2622488577 BATT_sohcPrimed_1 "SOHC Primed Mask";
CM_ SG_ 2622488577 BATT_capBrick14_1 "Capacity of brick 14";
CM_ SG_ 2622488577 BATT_capBrick13_1 "Capacity of brick 13";
CM_ BO_ 2622488578 "Capacity of bricks 13-14";
CM_ SG_ 2622488578 BATT_sohcUpdated_2 "SOHC Updated Mask";
CM_ SG_ 2622488578 BATT_sohcPrimed_2 "SOHC Primed Mask";
CM_ SG_ 2622488578 BATT_capBrick14_2 "Capacity of brick 14";
CM_ SG_ 2622488578 BATT_capBrick13_2 "Capacity of brick 13";
CM_ BO_ 2622488579 "Capacity of bricks 13-14";
CM_ SG_ 2622488579 BATT_sohcUpdated_3 "SOHC Updated Mask";
CM_ SG_ 2622488579 BATT_sohcPrimed_3 "SOHC Primed Mask";
CM_ SG_ 2622488579 BATT_capBrick14_3 "Capacity of brick 14";
CM_ SG_ 2622488579 BATT_capBrick13_3 "Capacity of brick 13";
CM_ BO_ 2622488580 "Capacity of bricks 13-14";
CM_ SG_ 2622488580 BATT_sohcUpdated_4 "SOHC Updated Mask";
CM_ SG_ 2622488580 BATT_sohcPrimed_4 "SOHC Primed Mask";
CM_ SG_ 2622488580 BATT_capBrick14_4 "Capacity of brick 14";
CM_ SG_ 2622488580 BATT_capBrick13_4 "Capacity of brick 13";
CM_ BO_ 2622488581 "Capacity of bricks 13-14";
CM_ SG_ 2622488581 BATT_sohcUpdated_5 "SOHC Updated Mask";
CM_ SG_ 2622488581 BATT_sohcPrimed_5 "SOHC Primed Mask";
CM_ SG_ 2622488581 BATT_capBrick14_5 "Capacity of brick 14";
CM_ SG_ 2622488581 BATT_capBrick13_5 "Capacity of brick 13";
CM_ BO_ 2622488582 "Capacity of bricks 13-14";
CM_ SG_ 2622488582 BATT_sohcUpdated_6 "SOHC Updated Mask";
CM_ SG_ 2622488582 BATT_sohcPrimed_6 "SOHC Primed Mask";
CM_ SG_ 2622488582 BATT_capBrick14_6 "Capacity of brick 14";
CM_ SG_ 2622488582 BATT_capBrick13_6 "Capacity of brick 13";
CM_ BO_ 2622488583 "Capacity of bricks 13-14";
CM_ SG_ 2622488583 BATT_sohcUpdated_7 "SOHC Updated Mask";
CM_ SG_ 2622488583 BATT_sohcPrimed_7 "SOHC Primed Mask";
CM_ SG_ 2622488583 BATT_capBrick14_7 "Capacity of brick 14";
CM_ SG_ 2622488583 BATT_capBrick13_7 "Capacity of brick 13";
CM_ BO_ 2622488584 "Capacity of bricks 13-14";
CM_ SG_ 2622488584 BATT_sohcUpdated_8 "SOHC Updated Mask";
CM_ SG_ 2622488584 BATT_sohcPrimed_8 "SOHC Primed Mask";
CM_ SG_ 2622488584 BATT_capBrick14_8 "Capacity of brick 14";
CM_ SG_ 2622488584 BATT_capBrick13_8 "Capacity of brick 13";
CM_ BO_ 2622488585 "Capacity of bricks 13-14";
CM_ SG_ 2622488585 BATT_sohcUpdated_9 "SOHC Updated Mask";
CM_ SG_ 2622488585 BATT_sohcPrimed_9 "SOHC Primed Mask";
CM_ SG_ 2622488585 BATT_capBrick14_9 "Capacity of brick 14";
CM_ SG_ 2622488585 BATT_capBrick13_9 "Capacity of brick 13";
CM_ BO_ 2622488586 "Capacity of bricks 13-14";
CM_ SG_ 2622488586 BATT_sohcUpdated_10 "SOHC Updated Mask";
CM_ SG_ 2622488586 BATT_sohcPrimed_10 "SOHC Primed Mask";
CM_ SG_ 2622488586 BATT_capBrick14_10 "Capacity of brick 14";
CM_ SG_ 2622488586 BATT_capBrick13_10 "Capacity of brick 13";
CM_ BO_ 2622488587 "Capacity of bricks 13-14";
CM_ SG_ 2622488587 BATT_sohcUpdated_11 "SOHC Updated Mask";
CM_ SG_ 2622488587 BATT_sohcPrimed_11 "SOHC Primed Mask";
CM_ SG_ 2622488587 BATT_capBrick14_11 "Capacity of brick 14";
CM_ SG_ 2622488587 BATT_capBrick13_11 "Capacity of brick 13";
CM_ BO_ 2625896448 "Voltages of bricks 1-4";
CM_ SG_ 2625896448 BATT_vBrick02_0 "Voltage of brick 2";
CM_ SG_ 2625896448 BATT_vBrick03_0 "Voltage of brick 3";
CM_ SG_ 2625896448 BATT_vBrick01_0 "Voltage of brick 1";
CM_ SG_ 2625896448 BATT_vBrick04_0 "Voltage of brick 4";
CM_ BO_ 2625896449 "Voltages of bricks 1-4";
CM_ SG_ 2625896449 BATT_vBrick02_1 "Voltage of brick 2";
CM_ SG_ 2625896449 BATT_vBrick03_1 "Voltage of brick 3";
CM_ SG_ 2625896449 BATT_vBrick01_1 "Voltage of brick 1";
CM_ SG_ 2625896449 BATT_vBrick04_1 "Voltage of brick 4";
CM_ BO_ 2625896450 "Voltages of bricks 1-4";
CM_ SG_ 2625896450 BATT_vBrick02_2 "Voltage of brick 2";
CM_ SG_ 2625896450 BATT_vBrick03_2 "Voltage of brick 3";
CM_ SG_ 2625896450 BATT_vBrick01_2 "Voltage of brick 1";
CM_ SG_ 2625896450 BATT_vBrick04_2 "Voltage of brick 4";
CM_ BO_ 2625896451 "Voltages of bricks 1-4";
CM_ SG_ 2625896451 BATT_vBrick02_3 "Voltage of brick 2";
CM_ SG_ 2625896451 BATT_vBrick03_3 "Voltage of brick 3";
CM_ SG_ 2625896451 BATT_vBrick01_3 "Voltage of brick 1";
CM_ SG_ 2625896451 BATT_vBrick04_3 "Voltage of brick 4";
CM_ BO_ 2625896452 "Voltages of bricks 1-4";
CM_ SG_ 2625896452 BATT_vBrick02_4 "Voltage of brick 2";
CM_ SG_ 2625896452 BATT_vBrick03_4 "Voltage of brick 3";
CM_ SG_ 2625896452 BATT_vBrick01_4 "Voltage of brick 1";
CM_ SG_ 2625896452 BATT_vBrick04_4 "Voltage of brick 4";
CM_ BO_ 2625896453 "Voltages of bricks 1-4";
CM_ SG_ 2625896453 BATT_vBrick02_5 "Voltage of brick 2";
CM_ SG_ 2625896453 BATT_vBrick03_5 "Voltage of brick 3";
CM_ SG_ 2625896453 BATT_vBrick01_5 "Voltage of brick 1";
CM_ SG_ 2625896453 BATT_vBrick04_5 "Voltage of brick 4";
CM_ BO_ 2625896454 "Voltages of bricks 1-4";
CM_ SG_ 2625896454 BATT_vBrick02_6 "Voltage of brick 2";
CM_ SG_ 2625896454 BATT_vBrick03_6 "Voltage of brick 3";
CM_ SG_ 2625896454 BATT_vBrick01_6 "Voltage of brick 1";
CM_ SG_ 2625896454 BATT_vBrick04_6 "Voltage of brick 4";
CM_ BO_ 2625896455 "Voltages of bricks 1-4";
CM_ SG_ 2625896455 BATT_vBrick02_7 "Voltage of brick 2";
CM_ SG_ 2625896455 BATT_vBrick03_7 "Voltage of brick 3";
CM_ SG_ 2625896455 BATT_vBrick01_7 "Voltage of brick 1";
CM_ SG_ 2625896455 BATT_vBrick04_7 "Voltage of brick 4";
CM_ BO_ 2625896456 "Voltages of bricks 1-4";
CM_ SG_ 2625896456 BATT_vBrick02_8 "Voltage of brick 2";
CM_ SG_ 2625896456 BATT_vBrick03_8 "Voltage of brick 3";
CM_ SG_ 2625896456 BATT_vBrick01_8 "Voltage of brick 1";
CM_ SG_ 2625896456 BATT_vBrick04_8 "Voltage of brick 4";
CM_ BO_ 2625896457 "Voltages of bricks 1-4";
CM_ SG_ 2625896457 BATT_vBrick02_9 "Voltage of brick 2";
CM_ SG_ 2625896457 BATT_vBrick03_9 "Voltage of brick 3";
CM_ SG_ 2625896457 BATT_vBrick01_9 "Voltage of brick 1";
CM_ SG_ 2625896457 BATT_vBrick04_9 "Voltage of brick 4";
CM_ BO_ 2625896458 "Voltages of bricks 1-4";
CM_ SG_ 2625896458 BATT_vBrick02_10 "Voltage of brick 2";
CM_ SG_ 2625896458 BATT_vBrick03_10 "Voltage of brick 3";
CM_ SG_ 2625896458 BATT_vBrick01_10 "Voltage of brick 1";
CM_ SG_ 2625896458 BATT_vBrick04_10 "Voltage of brick 4";
CM_ BO_ 2625896459 "Voltages of bricks 1-4";
CM_ SG_ 2625896459 BATT_vBrick02_11 "Voltage of brick 2";
CM_ SG_ 2625896459 BATT_vBrick03_11 "Voltage of brick 3";
CM_ SG_ 2625896459 BATT_vBrick01_11 "Voltage of brick 1";
CM_ SG_ 2625896459 BATT_vBrick04_11 "Voltage of brick 4";
CM_ BO_ 2626158592 "Voltages of bricks 5-8";
CM_ SG_ 2626158592 BATT_vBrick06_0 "Voltage of brick 6";
CM_ SG_ 2626158592 BATT_vBrick07_0 "Voltage of brick 7";
CM_ SG_ 2626158592 BATT_vBrick05_0 "Voltage of brick 5";
CM_ SG_ 2626158592 BATT_vBrick08_0 "Voltage of brick 8";
CM_ BO_ 2626158593 "Voltages of bricks 5-8";
CM_ SG_ 2626158593 BATT_vBrick06_1 "Voltage of brick 6";
CM_ SG_ 2626158593 BATT_vBrick07_1 "Voltage of brick 7";
CM_ SG_ 2626158593 BATT_vBrick05_1 "Voltage of brick 5";
CM_ SG_ 2626158593 BATT_vBrick08_1 "Voltage of brick 8";
CM_ BO_ 2626158594 "Voltages of bricks 5-8";
CM_ SG_ 2626158594 BATT_vBrick06_2 "Voltage of brick 6";
CM_ SG_ 2626158594 BATT_vBrick07_2 "Voltage of brick 7";
CM_ SG_ 2626158594 BATT_vBrick05_2 "Voltage of brick 5";
CM_ SG_ 2626158594 BATT_vBrick08_2 "Voltage of brick 8";
CM_ BO_ 2626158595 "Voltages of bricks 5-8";
CM_ SG_ 2626158595 BATT_vBrick06_3 "Voltage of brick 6";
CM_ SG_ 2626158595 BATT_vBrick07_3 "Voltage of brick 7";
CM_ SG_ 2626158595 BATT_vBrick05_3 "Voltage of brick 5";
CM_ SG_ 2626158595 BATT_vBrick08_3 "Voltage of brick 8";
CM_ BO_ 2626158596 "Voltages of bricks 5-8";
CM_ SG_ 2626158596 BATT_vBrick06_4 "Voltage of brick 6";
CM_ SG_ 2626158596 BATT_vBrick07_4 "Voltage of brick 7";
CM_ SG_ 2626158596 BATT_vBrick05_4 "Voltage of brick 5";
CM_ SG_ 2626158596 BATT_vBrick08_4 "Voltage of brick 8";
CM_ BO_ 2626158597 "Voltages of bricks 5-8";
CM_ SG_ 2626158597 BATT_vBrick06_5 "Voltage of brick 6";
CM_ SG_ 2626158597 BATT_vBrick07_5 "Voltage of brick 7";
CM_ SG_ 2626158597 BATT_vBrick05_5 "Voltage of brick 5";
CM_ SG_ 2626158597 BATT_vBrick08_5 "Voltage of brick 8";
CM_ BO_ 2626158598 "Voltages of bricks 5-8";
CM_ SG_ 2626158598 BATT_vBrick06_6 "Voltage of brick 6";
CM_ SG_ 2626158598 BATT_vBrick07_6 "Voltage of brick 7";
CM_ SG_ 2626158598 BATT_vBrick05_6 "Voltage of brick 5";
CM_ SG_ 2626158598 BATT_vBrick08_6 "Voltage of brick 8";
CM_ BO_ 2626158599 "Voltages of bricks 5-8";
CM_ SG_ 2626158599 BATT_vBrick06_7 "Voltage of brick 6";
CM_ SG_ 2626158599 BATT_vBrick07_7 "Voltage of brick 7";
CM_ SG_ 2626158599 BATT_vBrick05_7 "Voltage of brick 5";
CM_ SG_ 2626158599 BATT_vBrick08_7 "Voltage of brick 8";
CM_ BO_ 2626158600 "Voltages of bricks 5-8";
CM_ SG_ 2626158600 BATT_vBrick06_8 "Voltage of brick 6";
CM_ SG_ 2626158600 BATT_vBrick07_8 "Voltage of brick 7";
CM_ SG_ 2626158600 BATT_vBrick05_8 "Voltage of brick 5";
CM_ SG_ 2626158600 BATT_vBrick08_8 "Voltage of brick 8";
CM_ BO_ 2626158601 "Voltages of bricks 5-8";
CM_ SG_ 2626158601 BATT_vBrick06_9 "Voltage of brick 6";
CM_ SG_ 2626158601 BATT_vBrick07_9 "Voltage of brick 7";
CM_ SG_ 2626158601 BATT_vBrick05_9 "Voltage of brick 5";
CM_ SG_ 2626158601 BATT_vBrick08_9 "Voltage of brick 8";
CM_ BO_ 2626158602 "Voltages of bricks 5-8";
CM_ SG_ 2626158602 BATT_vBrick06_10 "Voltage of brick 6";
CM_ SG_ 2626158602 BATT_vBrick07_10 "Voltage of brick 7";
CM_ SG_ 2626158602 BATT_vBrick05_10 "Voltage of brick 5";
CM_ SG_ 2626158602 BATT_vBrick08_10 "Voltage of brick 8";
CM_ BO_ 2626158603 "Voltages of bricks 5-8";
CM_ SG_ 2626158603 BATT_vBrick06_11 "Voltage of brick 6";
CM_ SG_ 2626158603 BATT_vBrick07_11 "Voltage of brick 7";
CM_ SG_ 2626158603 BATT_vBrick05_11 "Voltage of brick 5";
CM_ SG_ 2626158603 BATT_vBrick08_11 "Voltage of brick 8";
CM_ BO_ 2626420736 "Voltages of bricks 9-12";
CM_ SG_ 2626420736 BATT_vBrick12_0 "Voltage of brick 12";
CM_ SG_ 2626420736 BATT_vBrick11_0 "Voltage of brick 11";
CM_ SG_ 2626420736 BATT_vBrick10_0 "Voltage of brick 10";
CM_ SG_ 2626420736 BATT_vBrick09_0 "Voltage of brick 9";
CM_ BO_ 2626420737 "Voltages of bricks 9-12";
CM_ SG_ 2626420737 BATT_vBrick12_1 "Voltage of brick 12";
CM_ SG_ 2626420737 BATT_vBrick11_1 "Voltage of brick 11";
CM_ SG_ 2626420737 BATT_vBrick10_1 "Voltage of brick 10";
CM_ SG_ 2626420737 BATT_vBrick09_1 "Voltage of brick 9";
CM_ BO_ 2626420738 "Voltages of bricks 9-12";
CM_ SG_ 2626420738 BATT_vBrick12_2 "Voltage of brick 12";
CM_ SG_ 2626420738 BATT_vBrick11_2 "Voltage of brick 11";
CM_ SG_ 2626420738 BATT_vBrick10_2 "Voltage of brick 10";
CM_ SG_ 2626420738 BATT_vBrick09_2 "Voltage of brick 9";
CM_ BO_ 2626420739 "Voltages of bricks 9-12";
CM_ SG_ 2626420739 BATT_vBrick12_3 "Voltage of brick 12";
CM_ SG_ 2626420739 BATT_vBrick11_3 "Voltage of brick 11";
CM_ SG_ 2626420739 BATT_vBrick10_3 "Voltage of brick 10";
CM_ SG_ 2626420739 BATT_vBrick09_3 "Voltage of brick 9";
CM_ BO_ 2626420740 "Voltages of bricks 9-12";
CM_ SG_ 2626420740 BATT_vBrick12_4 "Voltage of brick 12";
CM_ SG_ 2626420740 BATT_vBrick11_4 "Voltage of brick 11";
CM_ SG_ 2626420740 BATT_vBrick10_4 "Voltage of brick 10";
CM_ SG_ 2626420740 BATT_vBrick09_4 "Voltage of brick 9";
CM_ BO_ 2626420741 "Voltages of bricks 9-12";
CM_ SG_ 2626420741 BATT_vBrick12_5 "Voltage of brick 12";
CM_ SG_ 2626420741 BATT_vBrick11_5 "Voltage of brick 11";
CM_ SG_ 2626420741 BATT_vBrick10_5 "Voltage of brick 10";
CM_ SG_ 2626420741 BATT_vBrick09_5 "Voltage of brick 9";
CM_ BO_ 2626420742 "Voltages of bricks 9-12";
CM_ SG_ 2626420742 BATT_vBrick12_6 "Voltage of brick 12";
CM_ SG_ 2626420742 BATT_vBrick11_6 "Voltage of brick 11";
CM_ SG_ 2626420742 BATT_vBrick10_6 "Voltage of brick 10";
CM_ SG_ 2626420742 BATT_vBrick09_6 "Voltage of brick 9";
CM_ BO_ 2626420743 "Voltages of bricks 9-12";
CM_ SG_ 2626420743 BATT_vBrick12_7 "Voltage of brick 12";
CM_ SG_ 2626420743 BATT_vBrick11_7 "Voltage of brick 11";
CM_ SG_ 2626420743 BATT_vBrick10_7 "Voltage of brick 10";
CM_ SG_ 2626420743 BATT_vBrick09_7 "Voltage of brick 9";
CM_ BO_ 2626420744 "Voltages of bricks 9-12";
CM_ SG_ 2626420744 BATT_vBrick12_8 "Voltage of brick 12";
CM_ SG_ 2626420744 BATT_vBrick11_8 "Voltage of brick 11";
CM_ SG_ 2626420744 BATT_vBrick10_8 "Voltage of brick 10";
CM_ SG_ 2626420744 BATT_vBrick09_8 "Voltage of brick 9";
CM_ BO_ 2626420745 "Voltages of bricks 9-12";
CM_ SG_ 2626420745 BATT_vBrick12_9 "Voltage of brick 12";
CM_ SG_ 2626420745 BATT_vBrick11_9 "Voltage of brick 11";
CM_ SG_ 2626420745 BATT_vBrick10_9 "Voltage of brick 10";
CM_ SG_ 2626420745 BATT_vBrick09_9 "Voltage of brick 9";
CM_ BO_ 2626420746 "Voltages of bricks 9-12";
CM_ SG_ 2626420746 BATT_vBrick12_10 "Voltage of brick 12";
CM_ SG_ 2626420746 BATT_vBrick11_10 "Voltage of brick 11";
CM_ SG_ 2626420746 BATT_vBrick10_10 "Voltage of brick 10";
CM_ SG_ 2626420746 BATT_vBrick09_10 "Voltage of brick 9";
CM_ BO_ 2626420747 "Voltages of bricks 9-12";
CM_ SG_ 2626420747 BATT_vBrick12_11 "Voltage of brick 12";
CM_ SG_ 2626420747 BATT_vBrick11_11 "Voltage of brick 11";
CM_ SG_ 2626420747 BATT_vBrick10_11 "Voltage of brick 10";
CM_ SG_ 2626420747 BATT_vBrick09_11 "Voltage of brick 9";
CM_ BO_ 2626682880 "Voltages of bricks 13-14";
CM_ SG_ 2626682880 BATT_vBrick14_0 "Voltage of brick 14";
CM_ SG_ 2626682880 BATT_vBrick13_0 "Voltage of brick 13";
CM_ BO_ 2626682881 "Voltages of bricks 13-14";
CM_ SG_ 2626682881 BATT_vBrick14_1 "Voltage of brick 14";
CM_ SG_ 2626682881 BATT_vBrick13_1 "Voltage of brick 13";
CM_ BO_ 2626682882 "Voltages of bricks 13-14";
CM_ SG_ 2626682882 BATT_vBrick14_2 "Voltage of brick 14";
CM_ SG_ 2626682882 BATT_vBrick13_2 "Voltage of brick 13";
CM_ BO_ 2626682883 "Voltages of bricks 13-14";
CM_ SG_ 2626682883 BATT_vBrick14_3 "Voltage of brick 14";
CM_ SG_ 2626682883 BATT_vBrick13_3 "Voltage of brick 13";
CM_ BO_ 2626682884 "Voltages of bricks 13-14";
CM_ SG_ 2626682884 BATT_vBrick14_4 "Voltage of brick 14";
CM_ SG_ 2626682884 BATT_vBrick13_4 "Voltage of brick 13";
CM_ BO_ 2626682885 "Voltages of bricks 13-14";
CM_ SG_ 2626682885 BATT_vBrick14_5 "Voltage of brick 14";
CM_ SG_ 2626682885 BATT_vBrick13_5 "Voltage of brick 13";
CM_ BO_ 2626682886 "Voltages of bricks 13-14";
CM_ SG_ 2626682886 BATT_vBrick14_6 "Voltage of brick 14";
CM_ SG_ 2626682886 BATT_vBrick13_6 "Voltage of brick 13";
CM_ BO_ 2626682887 "Voltages of bricks 13-14";
CM_ SG_ 2626682887 BATT_vBrick14_7 "Voltage of brick 14";
CM_ SG_ 2626682887 BATT_vBrick13_7 "Voltage of brick 13";
CM_ BO_ 2626682888 "Voltages of bricks 13-14";
CM_ SG_ 2626682888 BATT_vBrick14_8 "Voltage of brick 14";
CM_ SG_ 2626682888 BATT_vBrick13_8 "Voltage of brick 13";
CM_ BO_ 2626682889 "Voltages of bricks 13-14";
CM_ SG_ 2626682889 BATT_vBrick14_9 "Voltage of brick 14";
CM_ SG_ 2626682889 BATT_vBrick13_9 "Voltage of brick 13";
CM_ BO_ 2626682890 "Voltages of bricks 13-14";
CM_ SG_ 2626682890 BATT_vBrick14_10 "Voltage of brick 14";
CM_ SG_ 2626682890 BATT_vBrick13_10 "Voltage of brick 13";
CM_ BO_ 2626682891 "Voltages of bricks 13-14";
CM_ SG_ 2626682891 BATT_vBrick14_11 "Voltage of brick 14";
CM_ SG_ 2626682891 BATT_vBrick13_11 "Voltage of brick 13";
CM_ BO_ 2626748416 "Harness Impedance";
CM_ SG_ 2626748416 BATT_HarnessImpedance_14_0 "Impedance of Harness
";
CM_ SG_ 2626748416 BATT_HarnessImpedance_13_0 "Impedance of Harness
";
CM_ SG_ 2626748416 BATT_HarnessImpedance_12_0 "Impedance of Harness
";
CM_ SG_ 2626748416 BATT_HarnessImpedance_11_0 "Impedance of Harness
";
CM_ SG_ 2626748416 BATT_HarnessImpedance_10_0 "Impedance of Harness
";
CM_ SG_ 2626748416 BATT_HarnessImpedance_9_0 "Impedance of Harness
";
CM_ SG_ 2626748416 BATT_HarnessImpedance_8_0 "Impedance of Harness
";
CM_ SG_ 2626748416 BATT_HarnessImpedance_7_0 "Impedance of Harness
";
CM_ SG_ 2626748416 BATT_HarnessImpedance_6_0 "Impedance of Harness
";
CM_ SG_ 2626748416 BATT_HarnessImpedance_5_0 "Impedance of Harness
";
CM_ SG_ 2626748416 BATT_HarnessImpedance_4_0 "Impedance of Harness
";
CM_ SG_ 2626748416 BATT_HarnessImpedance_3_0 "Impedance of Harness
";
CM_ SG_ 2626748416 BATT_HarnessImpedance_2_0 "Impedance of Harness
";
CM_ SG_ 2626748416 BATT_HarnessImpedance_1_0 "Impedance of Harness
";
CM_ SG_ 2626748416 BATT_HarnessImpedance_0_0 "Impedance of Harness
";
CM_ BO_ 2626748417 "Harness Impedance";
CM_ SG_ 2626748417 BATT_HarnessImpedance_14_1 "Impedance of Harness
";
CM_ SG_ 2626748417 BATT_HarnessImpedance_13_1 "Impedance of Harness
";
CM_ SG_ 2626748417 BATT_HarnessImpedance_12_1 "Impedance of Harness
";
CM_ SG_ 2626748417 BATT_HarnessImpedance_11_1 "Impedance of Harness
";
CM_ SG_ 2626748417 BATT_HarnessImpedance_10_1 "Impedance of Harness
";
CM_ SG_ 2626748417 BATT_HarnessImpedance_9_1 "Impedance of Harness
";
CM_ SG_ 2626748417 BATT_HarnessImpedance_8_1 "Impedance of Harness
";
CM_ SG_ 2626748417 BATT_HarnessImpedance_7_1 "Impedance of Harness
";
CM_ SG_ 2626748417 BATT_HarnessImpedance_6_1 "Impedance of Harness
";
CM_ SG_ 2626748417 BATT_HarnessImpedance_5_1 "Impedance of Harness
";
CM_ SG_ 2626748417 BATT_HarnessImpedance_4_1 "Impedance of Harness
";
CM_ SG_ 2626748417 BATT_HarnessImpedance_3_1 "Impedance of Harness
";
CM_ SG_ 2626748417 BATT_HarnessImpedance_2_1 "Impedance of Harness
";
CM_ SG_ 2626748417 BATT_HarnessImpedance_1_1 "Impedance of Harness
";
CM_ SG_ 2626748417 BATT_HarnessImpedance_0_1 "Impedance of Harness
";
CM_ BO_ 2626748418 "Harness Impedance";
CM_ SG_ 2626748418 BATT_HarnessImpedance_14_2 "Impedance of Harness
";
CM_ SG_ 2626748418 BATT_HarnessImpedance_13_2 "Impedance of Harness
";
CM_ SG_ 2626748418 BATT_HarnessImpedance_12_2 "Impedance of Harness
";
CM_ SG_ 2626748418 BATT_HarnessImpedance_11_2 "Impedance of Harness
";
CM_ SG_ 2626748418 BATT_HarnessImpedance_10_2 "Impedance of Harness
";
CM_ SG_ 2626748418 BATT_HarnessImpedance_9_2 "Impedance of Harness
";
CM_ SG_ 2626748418 BATT_HarnessImpedance_8_2 "Impedance of Harness
";
CM_ SG_ 2626748418 BATT_HarnessImpedance_7_2 "Impedance of Harness
";
CM_ SG_ 2626748418 BATT_HarnessImpedance_6_2 "Impedance of Harness
";
CM_ SG_ 2626748418 BATT_HarnessImpedance_5_2 "Impedance of Harness
";
CM_ SG_ 2626748418 BATT_HarnessImpedance_4_2 "Impedance of Harness
";
CM_ SG_ 2626748418 BATT_HarnessImpedance_3_2 "Impedance of Harness
";
CM_ SG_ 2626748418 BATT_HarnessImpedance_2_2 "Impedance of Harness
";
CM_ SG_ 2626748418 BATT_HarnessImpedance_1_2 "Impedance of Harness
";
CM_ SG_ 2626748418 BATT_HarnessImpedance_0_2 "Impedance of Harness
";
CM_ BO_ 2626748419 "Harness Impedance";
CM_ SG_ 2626748419 BATT_HarnessImpedance_14_3 "Impedance of Harness
";
CM_ SG_ 2626748419 BATT_HarnessImpedance_13_3 "Impedance of Harness
";
CM_ SG_ 2626748419 BATT_HarnessImpedance_12_3 "Impedance of Harness
";
CM_ SG_ 2626748419 BATT_HarnessImpedance_11_3 "Impedance of Harness
";
CM_ SG_ 2626748419 BATT_HarnessImpedance_10_3 "Impedance of Harness
";
CM_ SG_ 2626748419 BATT_HarnessImpedance_9_3 "Impedance of Harness
";
CM_ SG_ 2626748419 BATT_HarnessImpedance_8_3 "Impedance of Harness
";
CM_ SG_ 2626748419 BATT_HarnessImpedance_7_3 "Impedance of Harness
";
CM_ SG_ 2626748419 BATT_HarnessImpedance_6_3 "Impedance of Harness
";
CM_ SG_ 2626748419 BATT_HarnessImpedance_5_3 "Impedance of Harness
";
CM_ SG_ 2626748419 BATT_HarnessImpedance_4_3 "Impedance of Harness
";
CM_ SG_ 2626748419 BATT_HarnessImpedance_3_3 "Impedance of Harness
";
CM_ SG_ 2626748419 BATT_HarnessImpedance_2_3 "Impedance of Harness
";
CM_ SG_ 2626748419 BATT_HarnessImpedance_1_3 "Impedance of Harness
";
CM_ SG_ 2626748419 BATT_HarnessImpedance_0_3 "Impedance of Harness
";
CM_ BO_ 2626748420 "Harness Impedance";
CM_ SG_ 2626748420 BATT_HarnessImpedance_14_4 "Impedance of Harness
";
CM_ SG_ 2626748420 BATT_HarnessImpedance_13_4 "Impedance of Harness
";
CM_ SG_ 2626748420 BATT_HarnessImpedance_12_4 "Impedance of Harness
";
CM_ SG_ 2626748420 BATT_HarnessImpedance_11_4 "Impedance of Harness
";
CM_ SG_ 2626748420 BATT_HarnessImpedance_10_4 "Impedance of Harness
";
CM_ SG_ 2626748420 BATT_HarnessImpedance_9_4 "Impedance of Harness
";
CM_ SG_ 2626748420 BATT_HarnessImpedance_8_4 "Impedance of Harness
";
CM_ SG_ 2626748420 BATT_HarnessImpedance_7_4 "Impedance of Harness
";
CM_ SG_ 2626748420 BATT_HarnessImpedance_6_4 "Impedance of Harness
";
CM_ SG_ 2626748420 BATT_HarnessImpedance_5_4 "Impedance of Harness
";
CM_ SG_ 2626748420 BATT_HarnessImpedance_4_4 "Impedance of Harness
";
CM_ SG_ 2626748420 BATT_HarnessImpedance_3_4 "Impedance of Harness
";
CM_ SG_ 2626748420 BATT_HarnessImpedance_2_4 "Impedance of Harness
";
CM_ SG_ 2626748420 BATT_HarnessImpedance_1_4 "Impedance of Harness
";
CM_ SG_ 2626748420 BATT_HarnessImpedance_0_4 "Impedance of Harness
";
CM_ BO_ 2626748421 "Harness Impedance";
CM_ SG_ 2626748421 BATT_HarnessImpedance_14_5 "Impedance of Harness
";
CM_ SG_ 2626748421 BATT_HarnessImpedance_13_5 "Impedance of Harness
";
CM_ SG_ 2626748421 BATT_HarnessImpedance_12_5 "Impedance of Harness
";
CM_ SG_ 2626748421 BATT_HarnessImpedance_11_5 "Impedance of Harness
";
CM_ SG_ 2626748421 BATT_HarnessImpedance_10_5 "Impedance of Harness
";
CM_ SG_ 2626748421 BATT_HarnessImpedance_9_5 "Impedance of Harness
";
CM_ SG_ 2626748421 BATT_HarnessImpedance_8_5 "Impedance of Harness
";
CM_ SG_ 2626748421 BATT_HarnessImpedance_7_5 "Impedance of Harness
";
CM_ SG_ 2626748421 BATT_HarnessImpedance_6_5 "Impedance of Harness
";
CM_ SG_ 2626748421 BATT_HarnessImpedance_5_5 "Impedance of Harness
";
CM_ SG_ 2626748421 BATT_HarnessImpedance_4_5 "Impedance of Harness
";
CM_ SG_ 2626748421 BATT_HarnessImpedance_3_5 "Impedance of Harness
";
CM_ SG_ 2626748421 BATT_HarnessImpedance_2_5 "Impedance of Harness
";
CM_ SG_ 2626748421 BATT_HarnessImpedance_1_5 "Impedance of Harness
";
CM_ SG_ 2626748421 BATT_HarnessImpedance_0_5 "Impedance of Harness
";
CM_ BO_ 2626748422 "Harness Impedance";
CM_ SG_ 2626748422 BATT_HarnessImpedance_14_6 "Impedance of Harness
";
CM_ SG_ 2626748422 BATT_HarnessImpedance_13_6 "Impedance of Harness
";
CM_ SG_ 2626748422 BATT_HarnessImpedance_12_6 "Impedance of Harness
";
CM_ SG_ 2626748422 BATT_HarnessImpedance_11_6 "Impedance of Harness
";
CM_ SG_ 2626748422 BATT_HarnessImpedance_10_6 "Impedance of Harness
";
CM_ SG_ 2626748422 BATT_HarnessImpedance_9_6 "Impedance of Harness
";
CM_ SG_ 2626748422 BATT_HarnessImpedance_8_6 "Impedance of Harness
";
CM_ SG_ 2626748422 BATT_HarnessImpedance_7_6 "Impedance of Harness
";
CM_ SG_ 2626748422 BATT_HarnessImpedance_6_6 "Impedance of Harness
";
CM_ SG_ 2626748422 BATT_HarnessImpedance_5_6 "Impedance of Harness
";
CM_ SG_ 2626748422 BATT_HarnessImpedance_4_6 "Impedance of Harness
";
CM_ SG_ 2626748422 BATT_HarnessImpedance_3_6 "Impedance of Harness
";
CM_ SG_ 2626748422 BATT_HarnessImpedance_2_6 "Impedance of Harness
";
CM_ SG_ 2626748422 BATT_HarnessImpedance_1_6 "Impedance of Harness
";
CM_ SG_ 2626748422 BATT_HarnessImpedance_0_6 "Impedance of Harness
";
CM_ BO_ 2626748423 "Harness Impedance";
CM_ SG_ 2626748423 BATT_HarnessImpedance_14_7 "Impedance of Harness
";
CM_ SG_ 2626748423 BATT_HarnessImpedance_13_7 "Impedance of Harness
";
CM_ SG_ 2626748423 BATT_HarnessImpedance_12_7 "Impedance of Harness
";
CM_ SG_ 2626748423 BATT_HarnessImpedance_11_7 "Impedance of Harness
";
CM_ SG_ 2626748423 BATT_HarnessImpedance_10_7 "Impedance of Harness
";
CM_ SG_ 2626748423 BATT_HarnessImpedance_9_7 "Impedance of Harness
";
CM_ SG_ 2626748423 BATT_HarnessImpedance_8_7 "Impedance of Harness
";
CM_ SG_ 2626748423 BATT_HarnessImpedance_7_7 "Impedance of Harness
";
CM_ SG_ 2626748423 BATT_HarnessImpedance_6_7 "Impedance of Harness
";
CM_ SG_ 2626748423 BATT_HarnessImpedance_5_7 "Impedance of Harness
";
CM_ SG_ 2626748423 BATT_HarnessImpedance_4_7 "Impedance of Harness
";
CM_ SG_ 2626748423 BATT_HarnessImpedance_3_7 "Impedance of Harness
";
CM_ SG_ 2626748423 BATT_HarnessImpedance_2_7 "Impedance of Harness
";
CM_ SG_ 2626748423 BATT_HarnessImpedance_1_7 "Impedance of Harness
";
CM_ SG_ 2626748423 BATT_HarnessImpedance_0_7 "Impedance of Harness
";
CM_ BO_ 2626748424 "Harness Impedance";
CM_ SG_ 2626748424 BATT_HarnessImpedance_14_8 "Impedance of Harness
";
CM_ SG_ 2626748424 BATT_HarnessImpedance_13_8 "Impedance of Harness
";
CM_ SG_ 2626748424 BATT_HarnessImpedance_12_8 "Impedance of Harness
";
CM_ SG_ 2626748424 BATT_HarnessImpedance_11_8 "Impedance of Harness
";
CM_ SG_ 2626748424 BATT_HarnessImpedance_10_8 "Impedance of Harness
";
CM_ SG_ 2626748424 BATT_HarnessImpedance_9_8 "Impedance of Harness
";
CM_ SG_ 2626748424 BATT_HarnessImpedance_8_8 "Impedance of Harness
";
CM_ SG_ 2626748424 BATT_HarnessImpedance_7_8 "Impedance of Harness
";
CM_ SG_ 2626748424 BATT_HarnessImpedance_6_8 "Impedance of Harness
";
CM_ SG_ 2626748424 BATT_HarnessImpedance_5_8 "Impedance of Harness
";
CM_ SG_ 2626748424 BATT_HarnessImpedance_4_8 "Impedance of Harness
";
CM_ SG_ 2626748424 BATT_HarnessImpedance_3_8 "Impedance of Harness
";
CM_ SG_ 2626748424 BATT_HarnessImpedance_2_8 "Impedance of Harness
";
CM_ SG_ 2626748424 BATT_HarnessImpedance_1_8 "Impedance of Harness
";
CM_ SG_ 2626748424 BATT_HarnessImpedance_0_8 "Impedance of Harness
";
CM_ BO_ 2626748425 "Harness Impedance";
CM_ SG_ 2626748425 BATT_HarnessImpedance_14_9 "Impedance of Harness
";
CM_ SG_ 2626748425 BATT_HarnessImpedance_13_9 "Impedance of Harness
";
CM_ SG_ 2626748425 BATT_HarnessImpedance_12_9 "Impedance of Harness
";
CM_ SG_ 2626748425 BATT_HarnessImpedance_11_9 "Impedance of Harness
";
CM_ SG_ 2626748425 BATT_HarnessImpedance_10_9 "Impedance of Harness
";
CM_ SG_ 2626748425 BATT_HarnessImpedance_9_9 "Impedance of Harness
";
CM_ SG_ 2626748425 BATT_HarnessImpedance_8_9 "Impedance of Harness
";
CM_ SG_ 2626748425 BATT_HarnessImpedance_7_9 "Impedance of Harness
";
CM_ SG_ 2626748425 BATT_HarnessImpedance_6_9 "Impedance of Harness
";
CM_ SG_ 2626748425 BATT_HarnessImpedance_5_9 "Impedance of Harness
";
CM_ SG_ 2626748425 BATT_HarnessImpedance_4_9 "Impedance of Harness
";
CM_ SG_ 2626748425 BATT_HarnessImpedance_3_9 "Impedance of Harness
";
CM_ SG_ 2626748425 BATT_HarnessImpedance_2_9 "Impedance of Harness
";
CM_ SG_ 2626748425 BATT_HarnessImpedance_1_9 "Impedance of Harness
";
CM_ SG_ 2626748425 BATT_HarnessImpedance_0_9 "Impedance of Harness
";
CM_ BO_ 2626748426 "Harness Impedance";
CM_ SG_ 2626748426 BATT_HarnessImpedance_14_10 "Impedance of Harness
";
CM_ SG_ 2626748426 BATT_HarnessImpedance_13_10 "Impedance of Harness
";
CM_ SG_ 2626748426 BATT_HarnessImpedance_12_10 "Impedance of Harness
";
CM_ SG_ 2626748426 BATT_HarnessImpedance_11_10 "Impedance of Harness
";
CM_ SG_ 2626748426 BATT_HarnessImpedance_10_10 "Impedance of Harness
";
CM_ SG_ 2626748426 BATT_HarnessImpedance_9_10 "Impedance of Harness
";
CM_ SG_ 2626748426 BATT_HarnessImpedance_8_10 "Impedance of Harness
";
CM_ SG_ 2626748426 BATT_HarnessImpedance_7_10 "Impedance of Harness
";
CM_ SG_ 2626748426 BATT_HarnessImpedance_6_10 "Impedance of Harness
";
CM_ SG_ 2626748426 BATT_HarnessImpedance_5_10 "Impedance of Harness
";
CM_ SG_ 2626748426 BATT_HarnessImpedance_4_10 "Impedance of Harness
";
CM_ SG_ 2626748426 BATT_HarnessImpedance_3_10 "Impedance of Harness
";
CM_ SG_ 2626748426 BATT_HarnessImpedance_2_10 "Impedance of Harness
";
CM_ SG_ 2626748426 BATT_HarnessImpedance_1_10 "Impedance of Harness
";
CM_ SG_ 2626748426 BATT_HarnessImpedance_0_10 "Impedance of Harness
";
CM_ BO_ 2626748427 "Harness Impedance";
CM_ SG_ 2626748427 BATT_HarnessImpedance_14_11 "Impedance of Harness
";
CM_ SG_ 2626748427 BATT_HarnessImpedance_13_11 "Impedance of Harness
";
CM_ SG_ 2626748427 BATT_HarnessImpedance_12_11 "Impedance of Harness
";
CM_ SG_ 2626748427 BATT_HarnessImpedance_11_11 "Impedance of Harness
";
CM_ SG_ 2626748427 BATT_HarnessImpedance_10_11 "Impedance of Harness
";
CM_ SG_ 2626748427 BATT_HarnessImpedance_9_11 "Impedance of Harness
";
CM_ SG_ 2626748427 BATT_HarnessImpedance_8_11 "Impedance of Harness
";
CM_ SG_ 2626748427 BATT_HarnessImpedance_7_11 "Impedance of Harness
";
CM_ SG_ 2626748427 BATT_HarnessImpedance_6_11 "Impedance of Harness
";
CM_ SG_ 2626748427 BATT_HarnessImpedance_5_11 "Impedance of Harness
";
CM_ SG_ 2626748427 BATT_HarnessImpedance_4_11 "Impedance of Harness
";
CM_ SG_ 2626748427 BATT_HarnessImpedance_3_11 "Impedance of Harness
";
CM_ SG_ 2626748427 BATT_HarnessImpedance_2_11 "Impedance of Harness
";
CM_ SG_ 2626748427 BATT_HarnessImpedance_1_11 "Impedance of Harness
";
CM_ SG_ 2626748427 BATT_HarnessImpedance_0_11 "Impedance of Harness
";
CM_ BO_ 2626813952 "Harness impedance Delta ";
CM_ SG_ 2626813952 BATT_HrnsImpDelta_3_0 "Delat value of Harness Impedance
";
CM_ SG_ 2626813952 BATT_HrnsImpDelta_2_0 "Delat value of Harness Impedance
";
CM_ SG_ 2626813952 BATT_HrnsImpDelta_1_0 "Delat value of Harness Impedance
";
CM_ SG_ 2626813952 BATT_HrnsImpDelta_0_0 "Delat value of Harness Impedance
";
CM_ BO_ 2626813953 "Harness impedance Delta ";
CM_ SG_ 2626813953 BATT_HrnsImpDelta_3_1 "Delat value of Harness Impedance
";
CM_ SG_ 2626813953 BATT_HrnsImpDelta_2_1 "Delat value of Harness Impedance
";
CM_ SG_ 2626813953 BATT_HrnsImpDelta_1_1 "Delat value of Harness Impedance
";
CM_ SG_ 2626813953 BATT_HrnsImpDelta_0_1 "Delat value of Harness Impedance
";
CM_ BO_ 2626813954 "Harness impedance Delta ";
CM_ SG_ 2626813954 BATT_HrnsImpDelta_3_2 "Delat value of Harness Impedance
";
CM_ SG_ 2626813954 BATT_HrnsImpDelta_2_2 "Delat value of Harness Impedance
";
CM_ SG_ 2626813954 BATT_HrnsImpDelta_1_2 "Delat value of Harness Impedance
";
CM_ SG_ 2626813954 BATT_HrnsImpDelta_0_2 "Delat value of Harness Impedance
";
CM_ BO_ 2626813955 "Harness impedance Delta ";
CM_ SG_ 2626813955 BATT_HrnsImpDelta_3_3 "Delat value of Harness Impedance
";
CM_ SG_ 2626813955 BATT_HrnsImpDelta_2_3 "Delat value of Harness Impedance
";
CM_ SG_ 2626813955 BATT_HrnsImpDelta_1_3 "Delat value of Harness Impedance
";
CM_ SG_ 2626813955 BATT_HrnsImpDelta_0_3 "Delat value of Harness Impedance
";
CM_ BO_ 2626813956 "Harness impedance Delta ";
CM_ SG_ 2626813956 BATT_HrnsImpDelta_3_4 "Delat value of Harness Impedance
";
CM_ SG_ 2626813956 BATT_HrnsImpDelta_2_4 "Delat value of Harness Impedance
";
CM_ SG_ 2626813956 BATT_HrnsImpDelta_1_4 "Delat value of Harness Impedance
";
CM_ SG_ 2626813956 BATT_HrnsImpDelta_0_4 "Delat value of Harness Impedance
";
CM_ BO_ 2626813957 "Harness impedance Delta ";
CM_ SG_ 2626813957 BATT_HrnsImpDelta_3_5 "Delat value of Harness Impedance
";
CM_ SG_ 2626813957 BATT_HrnsImpDelta_2_5 "Delat value of Harness Impedance
";
CM_ SG_ 2626813957 BATT_HrnsImpDelta_1_5 "Delat value of Harness Impedance
";
CM_ SG_ 2626813957 BATT_HrnsImpDelta_0_5 "Delat value of Harness Impedance
";

BA_DEF_ BO_  "GenMsgDiag" ENUM "No","Yes";
BA_DEF_ BO_  "GenMsgInstanced" STRING ;
BA_DEF_ SG_  "GenSigType" ENUM "Extended","Diagnostic","Standard","Modified";
BA_DEF_ BO_  "GenMsgCycleTime" INT 0 0;
BA_DEF_ SG_  "GenSigSNA" INT 0 65535;
BA_DEF_ SG_  "Access" ENUM "r","rw";
BA_DEF_DEF_  "GenMsgDiag" "No";
BA_DEF_DEF_  "GenMsgInstanced" "No";
BA_DEF_DEF_  "GenSigType" "Standard";
BA_DEF_DEF_  "GenMsgCycleTime" 0;
BA_DEF_DEF_  "GenSigSNA" 0;
BA_DEF_DEF_  "Access" "r";
BA_ "GenMsgDiag" BO_ 2621702151 1;
BA_ "GenMsgDiag" BO_ 2621702152 1;
BA_ "GenMsgDiag" BO_ 2621702153 1;
BA_ "GenMsgDiag" BO_ 2621702154 1;
BA_ "GenMsgDiag" BO_ 2621702155 1;
BA_ "GenMsgDiag" BO_ 2621964288 1;
BA_ "GenMsgDiag" BO_ 2621964289 1;
BA_ "GenMsgDiag" BO_ 2621964290 1;
BA_ "GenMsgDiag" BO_ 2621964291 1;
BA_ "GenMsgDiag" BO_ 2621964292 1;
BA_ "GenMsgDiag" BO_ 2621964293 1;
BA_ "GenMsgDiag" BO_ 2621964294 1;
BA_ "GenMsgDiag" BO_ 2621964295 1;
BA_ "GenMsgDiag" BO_ 2621964296 1;
BA_ "GenMsgDiag" BO_ 2621964297 1;
BA_ "GenMsgDiag" BO_ 2621964298 1;
BA_ "GenMsgDiag" BO_ 2621964299 1;
BA_ "GenMsgDiag" BO_ 2622226432 1;
BA_ "GenMsgDiag" BO_ 2622226433 1;
BA_ "GenMsgDiag" BO_ 2622226434 1;
BA_ "GenMsgDiag" BO_ 2622226435 1;
BA_ "GenMsgDiag" BO_ 2622226436 1;
BA_ "GenMsgDiag" BO_ 2622226437 1;
BA_ "GenMsgDiag" BO_ 2622226438 1;
BA_ "GenMsgDiag" BO_ 2622226439 1;
BA_ "GenMsgDiag" BO_ 2622226440 1;
BA_ "GenMsgDiag" BO_ 2622226441 1;
BA_ "GenMsgDiag" BO_ 2622226442 1;
BA_ "GenMsgDiag" BO_ 2622226443 1;
BA_ "GenMsgDiag" BO_ 2622488576 1;
BA_ "GenMsgDiag" BO_ 2622488577 1;
BA_ "GenMsgDiag" BO_ 2622488578 1;
BA_ "GenMsgDiag" BO_ 2622488579 1;
BA_ "GenMsgDiag" BO_ 2622488580 1;
BA_ "GenMsgDiag" BO_ 2622488581 1;
BA_ "GenMsgDiag" BO_ 2622488582 1;
BA_ "GenMsgDiag" BO_ 2622488583 1;
BA_ "GenMsgDiag" BO_ 2622488584 1;
BA_ "GenMsgDiag" BO_ 2622488585 1;
BA_ "GenMsgDiag" BO_ 2622488586 1;
BA_ "GenMsgDiag" BO_ 2622488587 1;
BA_ "GenMsgDiag" BO_ 2625896448 1;
BA_ "GenMsgDiag" BO_ 2625896449 1;
BA_ "GenMsgDiag" BO_ 2625896450 1;
BA_ "GenMsgDiag" BO_ 2625896451 1;
BA_ "GenMsgDiag" BO_ 2625896452 1;
BA_ "GenMsgDiag" BO_ 2625896453 1;
BA_ "GenMsgDiag" BO_ 2625896454 1;
BA_ "GenMsgDiag" BO_ 2625896455 1;
BA_ "GenMsgDiag" BO_ 2625896456 1;
BA_ "GenMsgDiag" BO_ 2625896457 1;
BA_ "GenMsgDiag" BO_ 2625896458 1;
BA_ "GenMsgDiag" BO_ 2625896459 1;
BA_ "GenMsgDiag" BO_ 2626158592 1;
BA_ "GenMsgDiag" BO_ 2626158593 1;
BA_ "GenMsgDiag" BO_ 2626158594 1;
BA_ "GenMsgDiag" BO_ 2626158595 1;
BA_ "GenMsgDiag" BO_ 2626158596 1;
BA_ "GenMsgDiag" BO_ 2626158597 1;
BA_ "GenMsgDiag" BO_ 2626158598 1;
BA_ "GenMsgDiag" BO_ 2626158599 1;
BA_ "GenMsgDiag" BO_ 2626158600 1;
BA_ "GenMsgDiag" BO_ 2626158601 1;
BA_ "GenMsgDiag" BO_ 2626158602 1;
BA_ "GenMsgDiag" BO_ 2626158603 1;
BA_ "GenMsgDiag" BO_ 2626748416 1;
BA_ "GenMsgDiag" BO_ 2626748417 1;
BA_ "GenMsgDiag" BO_ 2626748418 1;
BA_ "GenMsgDiag" BO_ 2626748419 1;
BA_ "GenMsgDiag" BO_ 2626748420 1;
BA_ "GenMsgDiag" BO_ 2626748421 1;
BA_ "GenMsgDiag" BO_ 2626748422 1;
BA_ "GenMsgDiag" BO_ 2626748423 1;
BA_ "GenMsgDiag" BO_ 2626748424 1;
BA_ "GenMsgDiag" BO_ 2626748425 1;
BA_ "GenMsgDiag" BO_ 2626748426 1;
BA_ "GenMsgDiag" BO_ 2626748427 1;
BA_ "GenMsgDiag" BO_ 2626813952 1;
BA_ "GenMsgDiag" BO_ 2626813953 1;
BA_ "GenMsgDiag" BO_ 2626813954 1;
BA_ "GenMsgDiag" BO_ 2626813955 1;
BA_ "GenMsgDiag" BO_ 2626813956 1;
BA_ "GenMsgDiag" BO_ 2626813957 1;
BA_ "GenMsgInstanced" BO_ 2621702151 "False";
BA_ "GenMsgInstanced" BO_ 2621702152 "False";
BA_ "GenMsgInstanced" BO_ 2621702153 "False";
BA_ "GenMsgInstanced" BO_ 2621702154 "False";
BA_ "GenMsgInstanced" BO_ 2621702155 "False";
BA_ "GenMsgInstanced" BO_ 2621964288 "False";
BA_ "GenMsgInstanced" BO_ 2621964289 "False";
BA_ "GenMsgInstanced" BO_ 2621964290 "False";
BA_ "GenMsgInstanced" BO_ 2621964291 "False";
BA_ "GenMsgInstanced" BO_ 2621964292 "False";
BA_ "GenMsgInstanced" BO_ 2621964293 "False";
BA_ "GenMsgInstanced" BO_ 2621964294 "False";
BA_ "GenMsgInstanced" BO_ 2621964295 "False";
BA_ "GenMsgInstanced" BO_ 2621964296 "False";
BA_ "GenMsgInstanced" BO_ 2621964297 "False";
BA_ "GenMsgInstanced" BO_ 2621964298 "False";
BA_ "GenMsgInstanced" BO_ 2621964299 "False";
BA_ "GenMsgInstanced" BO_ 2622226432 "False";
BA_ "GenMsgInstanced" BO_ 2622226433 "False";
BA_ "GenMsgInstanced" BO_ 2622226434 "False";
BA_ "GenMsgInstanced" BO_ 2622226435 "False";
BA_ "GenMsgInstanced" BO_ 2622226436 "False";
BA_ "GenMsgInstanced" BO_ 2622226437 "False";
BA_ "GenMsgInstanced" BO_ 2622226438 "False";
BA_ "GenMsgInstanced" BO_ 2622226439 "False";
BA_ "GenMsgInstanced" BO_ 2622226440 "False";
BA_ "GenMsgInstanced" BO_ 2622226441 "False";
BA_ "GenMsgInstanced" BO_ 2622226442 "False";
BA_ "GenMsgInstanced" BO_ 2622226443 "False";
BA_ "GenMsgInstanced" BO_ 2622488576 "False";
BA_ "GenMsgInstanced" BO_ 2622488577 "False";
BA_ "GenMsgInstanced" BO_ 2622488578 "False";
BA_ "GenMsgInstanced" BO_ 2622488579 "False";
BA_ "GenMsgInstanced" BO_ 2622488580 "False";
BA_ "GenMsgInstanced" BO_ 2622488581 "False";
BA_ "GenMsgInstanced" BO_ 2622488582 "False";
BA_ "GenMsgInstanced" BO_ 2622488583 "False";
BA_ "GenMsgInstanced" BO_ 2622488584 "False";
BA_ "GenMsgInstanced" BO_ 2622488585 "False";
BA_ "GenMsgInstanced" BO_ 2622488586 "False";
BA_ "GenMsgInstanced" BO_ 2622488587 "False";
BA_ "GenMsgInstanced" BO_ 2625634304 "False";
BA_ "GenMsgInstanced" BO_ 2625634305 "False";
BA_ "GenMsgInstanced" BO_ 2625634306 "False";
BA_ "GenMsgInstanced" BO_ 2625634307 "False";
BA_ "GenMsgInstanced" BO_ 2625634308 "False";
BA_ "GenMsgInstanced" BO_ 2625634309 "False";
BA_ "GenMsgInstanced" BO_ 2625634310 "False";
BA_ "GenMsgInstanced" BO_ 2625634311 "False";
BA_ "GenMsgInstanced" BO_ 2625634312 "False";
BA_ "GenMsgInstanced" BO_ 2625634313 "False";
BA_ "GenMsgInstanced" BO_ 2625634314 "False";
BA_ "GenMsgInstanced" BO_ 2625634315 "False";
BA_ "GenMsgInstanced" BO_ 2625896448 "False";
BA_ "GenMsgInstanced" BO_ 2625896449 "False";
BA_ "GenMsgInstanced" BO_ 2625896450 "False";
BA_ "GenMsgInstanced" BO_ 2625896451 "False";
BA_ "GenMsgInstanced" BO_ 2625896452 "False";
BA_ "GenMsgInstanced" BO_ 2625896453 "False";
BA_ "GenMsgInstanced" BO_ 2625896454 "False";
BA_ "GenMsgInstanced" BO_ 2625896455 "False";
BA_ "GenMsgInstanced" BO_ 2625896456 "False";
BA_ "GenMsgInstanced" BO_ 2625896457 "False";
BA_ "GenMsgInstanced" BO_ 2625896458 "False";
BA_ "GenMsgInstanced" BO_ 2625896459 "False";
BA_ "GenMsgInstanced" BO_ 2626158592 "False";
BA_ "GenMsgInstanced" BO_ 2626158593 "False";
BA_ "GenMsgInstanced" BO_ 2626158594 "False";
BA_ "GenMsgInstanced" BO_ 2626158595 "False";
BA_ "GenMsgInstanced" BO_ 2626158596 "False";
BA_ "GenMsgInstanced" BO_ 2626158597 "False";
BA_ "GenMsgInstanced" BO_ 2626158598 "False";
BA_ "GenMsgInstanced" BO_ 2626158599 "False";
BA_ "GenMsgInstanced" BO_ 2626158600 "False";
BA_ "GenMsgInstanced" BO_ 2626158601 "False";
BA_ "GenMsgInstanced" BO_ 2626158602 "False";
BA_ "GenMsgInstanced" BO_ 2626158603 "False";
BA_ "GenMsgInstanced" BO_ 2626420736 "False";
BA_ "GenMsgInstanced" BO_ 2626420737 "False";
BA_ "GenMsgInstanced" BO_ 2626420738 "False";
BA_ "GenMsgInstanced" BO_ 2626420739 "False";
BA_ "GenMsgInstanced" BO_ 2626420740 "False";
BA_ "GenMsgInstanced" BO_ 2626420741 "False";
BA_ "GenMsgInstanced" BO_ 2626420742 "False";
BA_ "GenMsgInstanced" BO_ 2626420743 "False";
BA_ "GenMsgInstanced" BO_ 2626420744 "False";
BA_ "GenMsgInstanced" BO_ 2626420745 "False";
BA_ "GenMsgInstanced" BO_ 2626420746 "False";
BA_ "GenMsgInstanced" BO_ 2626420747 "False";
BA_ "GenMsgInstanced" BO_ 2626682880 "False";
BA_ "GenMsgInstanced" BO_ 2626682881 "False";
BA_ "GenMsgInstanced" BO_ 2626682882 "False";
BA_ "GenMsgInstanced" BO_ 2626682883 "False";
BA_ "GenMsgInstanced" BO_ 2626682884 "False";
BA_ "GenMsgInstanced" BO_ 2626682885 "False";
BA_ "GenMsgInstanced" BO_ 2626682886 "False";
BA_ "GenMsgInstanced" BO_ 2626682887 "False";
BA_ "GenMsgInstanced" BO_ 2626682888 "False";
BA_ "GenMsgInstanced" BO_ 2626682889 "False";
BA_ "GenMsgInstanced" BO_ 2626682890 "False";
BA_ "GenMsgInstanced" BO_ 2626682891 "False";
BA_ "GenMsgInstanced" BO_ 2626748416 "False";
BA_ "GenMsgInstanced" BO_ 2626748417 "False";
BA_ "GenMsgInstanced" BO_ 2626748418 "False";
BA_ "GenMsgInstanced" BO_ 2626748419 "False";
BA_ "GenMsgInstanced" BO_ 2626748420 "False";
BA_ "GenMsgInstanced" BO_ 2626748421 "False";
BA_ "GenMsgInstanced" BO_ 2626748422 "False";
BA_ "GenMsgInstanced" BO_ 2626748423 "False";
BA_ "GenMsgInstanced" BO_ 2626748424 "False";
BA_ "GenMsgInstanced" BO_ 2626748425 "False";
BA_ "GenMsgInstanced" BO_ 2626748426 "False";
BA_ "GenMsgInstanced" BO_ 2626748427 "False";
BA_ "GenMsgInstanced" BO_ 2626813952 "False";
BA_ "GenMsgInstanced" BO_ 2626813953 "False";
BA_ "GenMsgInstanced" BO_ 2626813954 "False";
BA_ "GenMsgInstanced" BO_ 2626813955 "False";
BA_ "GenMsgInstanced" BO_ 2626813956 "False";
BA_ "GenMsgInstanced" BO_ 2626813957 "False";
BA_ "GenSigType" SG_ 2621702151 BATT_capBrick04_7 1;
BA_ "GenSigType" SG_ 2621702151 BATT_capBrick03_7 1;
BA_ "GenSigType" SG_ 2621702151 BATT_capBrick02_7 1;
BA_ "GenSigType" SG_ 2621702151 BATT_capBrick01_7 1;
BA_ "GenSigType" SG_ 2621702152 BATT_capBrick04_8 1;
BA_ "GenSigType" SG_ 2621702152 BATT_capBrick03_8 1;
BA_ "GenSigType" SG_ 2621702152 BATT_capBrick02_8 1;
BA_ "GenSigType" SG_ 2621702152 BATT_capBrick01_8 1;
BA_ "GenSigType" SG_ 2621702153 BATT_capBrick04_9 1;
BA_ "GenSigType" SG_ 2621702153 BATT_capBrick03_9 1;
BA_ "GenSigType" SG_ 2621702153 BATT_capBrick02_9 1;
BA_ "GenSigType" SG_ 2621702153 BATT_capBrick01_9 1;
BA_ "GenSigType" SG_ 2621702154 BATT_capBrick04_10 1;
BA_ "GenSigType" SG_ 2621702154 BATT_capBrick03_10 1;
BA_ "GenSigType" SG_ 2621702154 BATT_capBrick02_10 1;
BA_ "GenSigType" SG_ 2621702154 BATT_capBrick01_10 1;
BA_ "GenSigType" SG_ 2621702155 BATT_capBrick04_11 1;
BA_ "GenSigType" SG_ 2621702155 BATT_capBrick03_11 1;
BA_ "GenSigType" SG_ 2621702155 BATT_capBrick02_11 1;
BA_ "GenSigType" SG_ 2621702155 BATT_capBrick01_11 1;
BA_ "GenSigType" SG_ 2621964288 BATT_capBrick08_0 1;
BA_ "GenSigType" SG_ 2621964288 BATT_capBrick07_0 1;
BA_ "GenSigType" SG_ 2621964288 BATT_capBrick06_0 1;
BA_ "GenSigType" SG_ 2621964288 BATT_capBrick05_0 1;
BA_ "GenSigType" SG_ 2621964289 BATT_capBrick08_1 1;
BA_ "GenSigType" SG_ 2621964289 BATT_capBrick07_1 1;
BA_ "GenSigType" SG_ 2621964289 BATT_capBrick06_1 1;
BA_ "GenSigType" SG_ 2621964289 BATT_capBrick05_1 1;
BA_ "GenSigType" SG_ 2621964290 BATT_capBrick08_2 1;
BA_ "GenSigType" SG_ 2621964290 BATT_capBrick07_2 1;
BA_ "GenSigType" SG_ 2621964290 BATT_capBrick06_2 1;
BA_ "GenSigType" SG_ 2621964290 BATT_capBrick05_2 1;
BA_ "GenSigType" SG_ 2621964291 BATT_capBrick08_3 1;
BA_ "GenSigType" SG_ 2621964291 BATT_capBrick07_3 1;
BA_ "GenSigType" SG_ 2621964291 BATT_capBrick06_3 1;
BA_ "GenSigType" SG_ 2621964291 BATT_capBrick05_3 1;
BA_ "GenSigType" SG_ 2621964292 BATT_capBrick08_4 1;
BA_ "GenSigType" SG_ 2621964292 BATT_capBrick07_4 1;
BA_ "GenSigType" SG_ 2621964292 BATT_capBrick06_4 1;
BA_ "GenSigType" SG_ 2621964292 BATT_capBrick05_4 1;
BA_ "GenSigType" SG_ 2621964293 BATT_capBrick08_5 1;
BA_ "GenSigType" SG_ 2621964293 BATT_capBrick07_5 1;
BA_ "GenSigType" SG_ 2621964293 BATT_capBrick06_5 1;
BA_ "GenSigType" SG_ 2621964293 BATT_capBrick05_5 1;
BA_ "GenSigType" SG_ 2621964294 BATT_capBrick08_6 1;
BA_ "GenSigType" SG_ 2621964294 BATT_capBrick07_6 1;
BA_ "GenSigType" SG_ 2621964294 BATT_capBrick06_6 1;
BA_ "GenSigType" SG_ 2621964294 BATT_capBrick05_6 1;
BA_ "GenSigType" SG_ 2621964295 BATT_capBrick08_7 1;
BA_ "GenSigType" SG_ 2621964295 BATT_capBrick07_7 1;
BA_ "GenSigType" SG_ 2621964295 BATT_capBrick06_7 1;
BA_ "GenSigType" SG_ 2621964295 BATT_capBrick05_7 1;
BA_ "GenSigType" SG_ 2621964296 BATT_capBrick08_8 1;
BA_ "GenSigType" SG_ 2621964296 BATT_capBrick07_8 1;
BA_ "GenSigType" SG_ 2621964296 BATT_capBrick06_8 1;
BA_ "GenSigType" SG_ 2621964296 BATT_capBrick05_8 1;
BA_ "GenSigType" SG_ 2621964297 BATT_capBrick08_9 1;
BA_ "GenSigType" SG_ 2621964297 BATT_capBrick07_9 1;
BA_ "GenSigType" SG_ 2621964297 BATT_capBrick06_9 1;
BA_ "GenSigType" SG_ 2621964297 BATT_capBrick05_9 1;
BA_ "GenSigType" SG_ 2621964298 BATT_capBrick08_10 1;
BA_ "GenSigType" SG_ 2621964298 BATT_capBrick07_10 1;
BA_ "GenSigType" SG_ 2621964298 BATT_capBrick06_10 1;
BA_ "GenSigType" SG_ 2621964298 BATT_capBrick05_10 1;
BA_ "GenSigType" SG_ 2621964299 BATT_capBrick08_11 1;
BA_ "GenSigType" SG_ 2621964299 BATT_capBrick07_11 1;
BA_ "GenSigType" SG_ 2621964299 BATT_capBrick06_11 1;
BA_ "GenSigType" SG_ 2621964299 BATT_capBrick05_11 1;
BA_ "GenSigType" SG_ 2622226432 BATT_capBrick12_0 1;
BA_ "GenSigType" SG_ 2622226432 BATT_capBrick11_0 1;
BA_ "GenSigType" SG_ 2622226432 BATT_capBrick09_0 1;
BA_ "GenSigType" SG_ 2622226432 BATT_capBrick10_0 1;
BA_ "GenSigType" SG_ 2622226433 BATT_capBrick12_1 1;
BA_ "GenSigType" SG_ 2622226433 BATT_capBrick11_1 1;
BA_ "GenSigType" SG_ 2622226433 BATT_capBrick09_1 1;
BA_ "GenSigType" SG_ 2622226433 BATT_capBrick10_1 1;
BA_ "GenSigType" SG_ 2622226434 BATT_capBrick12_2 1;
BA_ "GenSigType" SG_ 2622226434 BATT_capBrick11_2 1;
BA_ "GenSigType" SG_ 2622226434 BATT_capBrick09_2 1;
BA_ "GenSigType" SG_ 2622226434 BATT_capBrick10_2 1;
BA_ "GenSigType" SG_ 2622226435 BATT_capBrick12_3 1;
BA_ "GenSigType" SG_ 2622226435 BATT_capBrick11_3 1;
BA_ "GenSigType" SG_ 2622226435 BATT_capBrick09_3 1;
BA_ "GenSigType" SG_ 2622226435 BATT_capBrick10_3 1;
BA_ "GenSigType" SG_ 2622226436 BATT_capBrick12_4 1;
BA_ "GenSigType" SG_ 2622226436 BATT_capBrick11_4 1;
BA_ "GenSigType" SG_ 2622226436 BATT_capBrick09_4 1;
BA_ "GenSigType" SG_ 2622226436 BATT_capBrick10_4 1;
BA_ "GenSigType" SG_ 2622226437 BATT_capBrick12_5 1;
BA_ "GenSigType" SG_ 2622226437 BATT_capBrick11_5 1;
BA_ "GenSigType" SG_ 2622226437 BATT_capBrick09_5 1;
BA_ "GenSigType" SG_ 2622226437 BATT_capBrick10_5 1;
BA_ "GenSigType" SG_ 2622226438 BATT_capBrick12_6 1;
BA_ "GenSigType" SG_ 2622226438 BATT_capBrick11_6 1;
BA_ "GenSigType" SG_ 2622226438 BATT_capBrick09_6 1;
BA_ "GenSigType" SG_ 2622226438 BATT_capBrick10_6 1;
BA_ "GenSigType" SG_ 2622226439 BATT_capBrick12_7 1;
BA_ "GenSigType" SG_ 2622226439 BATT_capBrick11_7 1;
BA_ "GenSigType" SG_ 2622226439 BATT_capBrick09_7 1;
BA_ "GenSigType" SG_ 2622226439 BATT_capBrick10_7 1;
BA_ "GenSigType" SG_ 2622226440 BATT_capBrick12_8 1;
BA_ "GenSigType" SG_ 2622226440 BATT_capBrick11_8 1;
BA_ "GenSigType" SG_ 2622226440 BATT_capBrick09_8 1;
BA_ "GenSigType" SG_ 2622226440 BATT_capBrick10_8 1;
BA_ "GenSigType" SG_ 2622226441 BATT_capBrick12_9 1;
BA_ "GenSigType" SG_ 2622226441 BATT_capBrick11_9 1;
BA_ "GenSigType" SG_ 2622226441 BATT_capBrick09_9 1;
BA_ "GenSigType" SG_ 2622226441 BATT_capBrick10_9 1;
BA_ "GenSigType" SG_ 2622226442 BATT_capBrick12_10 1;
BA_ "GenSigType" SG_ 2622226442 BATT_capBrick11_10 1;
BA_ "GenSigType" SG_ 2622226442 BATT_capBrick09_10 1;
BA_ "GenSigType" SG_ 2622226442 BATT_capBrick10_10 1;
BA_ "GenSigType" SG_ 2622226443 BATT_capBrick12_11 1;
BA_ "GenSigType" SG_ 2622226443 BATT_capBrick11_11 1;
BA_ "GenSigType" SG_ 2622226443 BATT_capBrick09_11 1;
BA_ "GenSigType" SG_ 2622226443 BATT_capBrick10_11 1;
BA_ "GenSigType" SG_ 2622488576 BATT_sohcUpdated_0 1;
BA_ "GenSigType" SG_ 2622488576 BATT_sohcPrimed_0 1;
BA_ "GenSigType" SG_ 2622488576 BATT_capBrick14_0 1;
BA_ "GenSigType" SG_ 2622488576 BATT_capBrick13_0 1;
BA_ "GenSigType" SG_ 2622488577 BATT_sohcUpdated_1 1;
BA_ "GenSigType" SG_ 2622488577 BATT_sohcPrimed_1 1;
BA_ "GenSigType" SG_ 2622488577 BATT_capBrick14_1 1;
BA_ "GenSigType" SG_ 2622488577 BATT_capBrick13_1 1;
BA_ "GenSigType" SG_ 2622488578 BATT_sohcUpdated_2 1;
BA_ "GenSigType" SG_ 2622488578 BATT_sohcPrimed_2 1;
BA_ "GenSigType" SG_ 2622488578 BATT_capBrick14_2 1;
BA_ "GenSigType" SG_ 2622488578 BATT_capBrick13_2 1;
BA_ "GenSigType" SG_ 2622488579 BATT_capBrick14_3 1;
BA_ "GenSigType" SG_ 2622488579 BATT_sohcUpdated_3 1;
BA_ "GenSigType" SG_ 2622488579 BATT_sohcPrimed_3 1;
BA_ "GenSigType" SG_ 2622488579 BATT_capBrick13_3 1;
BA_ "GenSigType" SG_ 2622488580 BATT_sohcUpdated_4 1;
BA_ "GenSigType" SG_ 2622488580 BATT_sohcPrimed_4 1;
BA_ "GenSigType" SG_ 2622488580 BATT_capBrick14_4 1;
BA_ "GenSigType" SG_ 2622488580 BATT_capBrick13_4 1;
BA_ "GenSigType" SG_ 2622488581 BATT_sohcUpdated_5 1;
BA_ "GenSigType" SG_ 2622488581 BATT_sohcPrimed_5 1;
BA_ "GenSigType" SG_ 2622488581 BATT_capBrick14_5 1;
BA_ "GenSigType" SG_ 2622488581 BATT_capBrick13_5 1;
BA_ "GenSigType" SG_ 2622488582 BATT_sohcUpdated_6 1;
BA_ "GenSigType" SG_ 2622488582 BATT_sohcPrimed_6 1;
BA_ "GenSigType" SG_ 2622488582 BATT_capBrick14_6 1;
BA_ "GenSigType" SG_ 2622488582 BATT_capBrick13_6 1;
BA_ "GenSigType" SG_ 2622488583 BATT_sohcUpdated_7 1;
BA_ "GenSigType" SG_ 2622488583 BATT_sohcPrimed_7 1;
BA_ "GenSigType" SG_ 2622488583 BATT_capBrick14_7 1;
BA_ "GenSigType" SG_ 2622488583 BATT_capBrick13_7 1;
BA_ "GenSigType" SG_ 2622488584 BATT_sohcUpdated_8 1;
BA_ "GenSigType" SG_ 2622488584 BATT_sohcPrimed_8 1;
BA_ "GenSigType" SG_ 2622488584 BATT_capBrick14_8 1;
BA_ "GenSigType" SG_ 2622488584 BATT_capBrick13_8 1;
BA_ "GenSigType" SG_ 2622488585 BATT_sohcUpdated_9 1;
BA_ "GenSigType" SG_ 2622488585 BATT_sohcPrimed_9 1;
BA_ "GenSigType" SG_ 2622488585 BATT_capBrick14_9 1;
BA_ "GenSigType" SG_ 2622488585 BATT_capBrick13_9 1;
BA_ "GenSigType" SG_ 2622488586 BATT_sohcUpdated_10 1;
BA_ "GenSigType" SG_ 2622488586 BATT_sohcPrimed_10 1;
BA_ "GenSigType" SG_ 2622488586 BATT_capBrick14_10 1;
BA_ "GenSigType" SG_ 2622488586 BATT_capBrick13_10 1;
BA_ "GenSigType" SG_ 2622488587 BATT_sohcUpdated_11 1;
BA_ "GenSigType" SG_ 2622488587 BATT_sohcPrimed_11 1;
BA_ "GenSigType" SG_ 2622488587 BATT_capBrick14_11 1;
BA_ "GenSigType" SG_ 2622488587 BATT_capBrick13_11 1;
BA_ "GenSigType" SG_ 2625896448 BATT_vBrick02_0 1;
BA_ "GenSigType" SG_ 2625896448 BATT_vBrick03_0 1;
BA_ "GenSigType" SG_ 2625896448 BATT_vBrick01_0 1;
BA_ "GenSigType" SG_ 2625896448 BATT_vBrick04_0 1;
BA_ "GenSigType" SG_ 2625896449 BATT_vBrick02_1 1;
BA_ "GenSigType" SG_ 2625896449 BATT_vBrick03_1 1;
BA_ "GenSigType" SG_ 2625896449 BATT_vBrick01_1 1;
BA_ "GenSigType" SG_ 2625896449 BATT_vBrick04_1 1;
BA_ "GenSigType" SG_ 2625896450 BATT_vBrick02_2 1;
BA_ "GenSigType" SG_ 2625896450 BATT_vBrick03_2 1;
BA_ "GenSigType" SG_ 2625896450 BATT_vBrick01_2 1;
BA_ "GenSigType" SG_ 2625896450 BATT_vBrick04_2 1;
BA_ "GenSigType" SG_ 2625896451 BATT_vBrick02_3 1;
BA_ "GenSigType" SG_ 2625896451 BATT_vBrick03_3 1;
BA_ "GenSigType" SG_ 2625896451 BATT_vBrick01_3 1;
BA_ "GenSigType" SG_ 2625896451 BATT_vBrick04_3 1;
BA_ "GenSigType" SG_ 2625896452 BATT_vBrick02_4 1;
BA_ "GenSigType" SG_ 2625896452 BATT_vBrick03_4 1;
BA_ "GenSigType" SG_ 2625896452 BATT_vBrick01_4 1;
BA_ "GenSigType" SG_ 2625896452 BATT_vBrick04_4 1;
BA_ "GenSigType" SG_ 2625896453 BATT_vBrick02_5 1;
BA_ "GenSigType" SG_ 2625896453 BATT_vBrick03_5 1;
BA_ "GenSigType" SG_ 2625896453 BATT_vBrick01_5 1;
BA_ "GenSigType" SG_ 2625896453 BATT_vBrick04_5 1;
BA_ "GenSigType" SG_ 2625896454 BATT_vBrick02_6 1;
BA_ "GenSigType" SG_ 2625896454 BATT_vBrick03_6 1;
BA_ "GenSigType" SG_ 2625896454 BATT_vBrick01_6 1;
BA_ "GenSigType" SG_ 2625896454 BATT_vBrick04_6 1;
BA_ "GenSigType" SG_ 2625896455 BATT_vBrick02_7 1;
BA_ "GenSigType" SG_ 2625896455 BATT_vBrick03_7 1;
BA_ "GenSigType" SG_ 2625896455 BATT_vBrick01_7 1;
BA_ "GenSigType" SG_ 2625896455 BATT_vBrick04_7 1;
BA_ "GenSigType" SG_ 2625896456 BATT_vBrick02_8 1;
BA_ "GenSigType" SG_ 2625896456 BATT_vBrick03_8 1;
BA_ "GenSigType" SG_ 2625896456 BATT_vBrick01_8 1;
BA_ "GenSigType" SG_ 2625896456 BATT_vBrick04_8 1;
BA_ "GenSigType" SG_ 2625896457 BATT_vBrick02_9 1;
BA_ "GenSigType" SG_ 2625896457 BATT_vBrick03_9 1;
BA_ "GenSigType" SG_ 2625896457 BATT_vBrick01_9 1;
BA_ "GenSigType" SG_ 2625896457 BATT_vBrick04_9 1;
BA_ "GenSigType" SG_ 2625896458 BATT_vBrick02_10 1;
BA_ "GenSigType" SG_ 2625896458 BATT_vBrick03_10 1;
BA_ "GenSigType" SG_ 2625896458 BATT_vBrick01_10 1;
BA_ "GenSigType" SG_ 2625896458 BATT_vBrick04_10 1;
BA_ "GenSigType" SG_ 2625896459 BATT_vBrick02_11 1;
BA_ "GenSigType" SG_ 2625896459 BATT_vBrick03_11 1;
BA_ "GenSigType" SG_ 2625896459 BATT_vBrick01_11 1;
BA_ "GenSigType" SG_ 2625896459 BATT_vBrick04_11 1;
BA_ "GenSigType" SG_ 2626158592 BATT_vBrick06_0 1;
BA_ "GenSigType" SG_ 2626158592 BATT_vBrick07_0 1;
BA_ "GenSigType" SG_ 2626158592 BATT_vBrick05_0 1;
BA_ "GenSigType" SG_ 2626158592 BATT_vBrick08_0 1;
BA_ "GenSigType" SG_ 2626158593 BATT_vBrick06_1 1;
BA_ "GenSigType" SG_ 2626158593 BATT_vBrick07_1 1;
BA_ "GenSigType" SG_ 2626158593 BATT_vBrick05_1 1;
BA_ "GenSigType" SG_ 2626158593 BATT_vBrick08_1 1;
BA_ "GenSigType" SG_ 2626158594 BATT_vBrick06_2 1;
BA_ "GenSigType" SG_ 2626158594 BATT_vBrick07_2 1;
BA_ "GenSigType" SG_ 2626158594 BATT_vBrick05_2 1;
BA_ "GenSigType" SG_ 2626158594 BATT_vBrick08_2 1;
BA_ "GenSigType" SG_ 2626158595 BATT_vBrick06_3 1;
BA_ "GenSigType" SG_ 2626158595 BATT_vBrick07_3 1;
BA_ "GenSigType" SG_ 2626158595 BATT_vBrick05_3 1;
BA_ "GenSigType" SG_ 2626158595 BATT_vBrick08_3 1;
BA_ "GenSigType" SG_ 2626158596 BATT_vBrick06_4 1;
BA_ "GenSigType" SG_ 2626158596 BATT_vBrick07_4 1;
BA_ "GenSigType" SG_ 2626158596 BATT_vBrick05_4 1;
BA_ "GenSigType" SG_ 2626158596 BATT_vBrick08_4 1;
BA_ "GenSigType" SG_ 2626158597 BATT_vBrick06_5 1;
BA_ "GenSigType" SG_ 2626158597 BATT_vBrick07_5 1;
BA_ "GenSigType" SG_ 2626158597 BATT_vBrick05_5 1;
BA_ "GenSigType" SG_ 2626158597 BATT_vBrick08_5 1;
BA_ "GenSigType" SG_ 2626158598 BATT_vBrick06_6 1;
BA_ "GenSigType" SG_ 2626158598 BATT_vBrick07_6 1;
BA_ "GenSigType" SG_ 2626158598 BATT_vBrick05_6 1;
BA_ "GenSigType" SG_ 2626158598 BATT_vBrick08_6 1;
BA_ "GenSigType" SG_ 2626158599 BATT_vBrick06_7 1;
BA_ "GenSigType" SG_ 2626158599 BATT_vBrick07_7 1;
BA_ "GenSigType" SG_ 2626158599 BATT_vBrick05_7 1;
BA_ "GenSigType" SG_ 2626158599 BATT_vBrick08_7 1;
BA_ "GenSigType" SG_ 2626158600 BATT_vBrick06_8 1;
BA_ "GenSigType" SG_ 2626158600 BATT_vBrick07_8 1;
BA_ "GenSigType" SG_ 2626158600 BATT_vBrick05_8 1;
BA_ "GenSigType" SG_ 2626158600 BATT_vBrick08_8 1;
BA_ "GenSigType" SG_ 2626158601 BATT_vBrick06_9 1;
BA_ "GenSigType" SG_ 2626158601 BATT_vBrick07_9 1;
BA_ "GenSigType" SG_ 2626158601 BATT_vBrick05_9 1;
BA_ "GenSigType" SG_ 2626158601 BATT_vBrick08_9 1;
BA_ "GenSigType" SG_ 2626158602 BATT_vBrick06_10 1;
BA_ "GenSigType" SG_ 2626158602 BATT_vBrick07_10 1;
BA_ "GenSigType" SG_ 2626158602 BATT_vBrick05_10 1;
BA_ "GenSigType" SG_ 2626158602 BATT_vBrick08_10 1;
BA_ "GenSigType" SG_ 2626158603 BATT_vBrick06_11 1;
BA_ "GenSigType" SG_ 2626158603 BATT_vBrick07_11 1;
BA_ "GenSigType" SG_ 2626158603 BATT_vBrick05_11 1;
BA_ "GenSigType" SG_ 2626158603 BATT_vBrick08_11 1;
BA_ "GenSigType" SG_ 2626420736 BATT_vBrick12_0 1;
BA_ "GenSigType" SG_ 2626420736 BATT_vBrick11_0 1;
BA_ "GenSigType" SG_ 2626420736 BATT_vBrick10_0 1;
BA_ "GenSigType" SG_ 2626420736 BATT_vBrick09_0 1;
BA_ "GenSigType" SG_ 2626420737 BATT_vBrick12_1 1;
BA_ "GenSigType" SG_ 2626420737 BATT_vBrick11_1 1;
BA_ "GenSigType" SG_ 2626420737 BATT_vBrick10_1 1;
BA_ "GenSigType" SG_ 2626420737 BATT_vBrick09_1 1;
BA_ "GenSigType" SG_ 2626420738 BATT_vBrick12_2 1;
BA_ "GenSigType" SG_ 2626420738 BATT_vBrick11_2 1;
BA_ "GenSigType" SG_ 2626420738 BATT_vBrick10_2 1;
BA_ "GenSigType" SG_ 2626420738 BATT_vBrick09_2 1;
BA_ "GenSigType" SG_ 2626420739 BATT_vBrick12_3 1;
BA_ "GenSigType" SG_ 2626420739 BATT_vBrick11_3 1;
BA_ "GenSigType" SG_ 2626420739 BATT_vBrick10_3 1;
BA_ "GenSigType" SG_ 2626420739 BATT_vBrick09_3 1;
BA_ "GenSigType" SG_ 2626420740 BATT_vBrick12_4 1;
BA_ "GenSigType" SG_ 2626420740 BATT_vBrick11_4 1;
BA_ "GenSigType" SG_ 2626420740 BATT_vBrick10_4 1;
BA_ "GenSigType" SG_ 2626420740 BATT_vBrick09_4 1;
BA_ "GenSigType" SG_ 2626420741 BATT_vBrick12_5 1;
BA_ "GenSigType" SG_ 2626420741 BATT_vBrick11_5 1;
BA_ "GenSigType" SG_ 2626420741 BATT_vBrick10_5 1;
BA_ "GenSigType" SG_ 2626420741 BATT_vBrick09_5 1;
BA_ "GenSigType" SG_ 2626420742 BATT_vBrick12_6 1;
BA_ "GenSigType" SG_ 2626420742 BATT_vBrick11_6 1;
BA_ "GenSigType" SG_ 2626420742 BATT_vBrick10_6 1;
BA_ "GenSigType" SG_ 2626420742 BATT_vBrick09_6 1;
BA_ "GenSigType" SG_ 2626420743 BATT_vBrick12_7 1;
BA_ "GenSigType" SG_ 2626420743 BATT_vBrick11_7 1;
BA_ "GenSigType" SG_ 2626420743 BATT_vBrick10_7 1;
BA_ "GenSigType" SG_ 2626420743 BATT_vBrick09_7 1;
BA_ "GenSigType" SG_ 2626420744 BATT_vBrick12_8 1;
BA_ "GenSigType" SG_ 2626420744 BATT_vBrick11_8 1;
BA_ "GenSigType" SG_ 2626420744 BATT_vBrick10_8 1;
BA_ "GenSigType" SG_ 2626420744 BATT_vBrick09_8 1;
BA_ "GenSigType" SG_ 2626420745 BATT_vBrick12_9 1;
BA_ "GenSigType" SG_ 2626420745 BATT_vBrick11_9 1;
BA_ "GenSigType" SG_ 2626420745 BATT_vBrick10_9 1;
BA_ "GenSigType" SG_ 2626420745 BATT_vBrick09_9 1;
BA_ "GenSigType" SG_ 2626420746 BATT_vBrick12_10 1;
BA_ "GenSigType" SG_ 2626420746 BATT_vBrick11_10 1;
BA_ "GenSigType" SG_ 2626420746 BATT_vBrick10_10 1;
BA_ "GenSigType" SG_ 2626420746 BATT_vBrick09_10 1;
BA_ "GenSigType" SG_ 2626420747 BATT_vBrick12_11 1;
BA_ "GenSigType" SG_ 2626420747 BATT_vBrick11_11 1;
BA_ "GenSigType" SG_ 2626420747 BATT_vBrick10_11 1;
BA_ "GenSigType" SG_ 2626420747 BATT_vBrick09_11 1;
BA_ "GenSigType" SG_ 2626682880 BATT_vBrick14_0 1;
BA_ "GenSigType" SG_ 2626682880 BATT_vBrick13_0 1;
BA_ "GenSigType" SG_ 2626682881 BATT_vBrick14_1 1;
BA_ "GenSigType" SG_ 2626682881 BATT_vBrick13_1 1;
BA_ "GenSigType" SG_ 2626682882 BATT_vBrick14_2 1;
BA_ "GenSigType" SG_ 2626682882 BATT_vBrick13_2 1;
BA_ "GenSigType" SG_ 2626682883 BATT_vBrick14_3 1;
BA_ "GenSigType" SG_ 2626682883 BATT_vBrick13_3 1;
BA_ "GenSigType" SG_ 2626682884 BATT_vBrick14_4 1;
BA_ "GenSigType" SG_ 2626682884 BATT_vBrick13_4 1;
BA_ "GenSigType" SG_ 2626682885 BATT_vBrick14_5 1;
BA_ "GenSigType" SG_ 2626682885 BATT_vBrick13_5 1;
BA_ "GenSigType" SG_ 2626682886 BATT_vBrick14_6 1;
BA_ "GenSigType" SG_ 2626682886 BATT_vBrick13_6 1;
BA_ "GenSigType" SG_ 2626682887 BATT_vBrick14_7 1;
BA_ "GenSigType" SG_ 2626682887 BATT_vBrick13_7 1;
BA_ "GenSigType" SG_ 2626682888 BATT_vBrick14_8 1;
BA_ "GenSigType" SG_ 2626682888 BATT_vBrick13_8 1;
BA_ "GenSigType" SG_ 2626682889 BATT_vBrick14_9 1;
BA_ "GenSigType" SG_ 2626682889 BATT_vBrick13_9 1;
BA_ "GenSigType" SG_ 2626682890 BATT_vBrick14_10 1;
BA_ "GenSigType" SG_ 2626682890 BATT_vBrick13_10 1;
BA_ "GenSigType" SG_ 2626682891 BATT_vBrick14_11 1;
BA_ "GenSigType" SG_ 2626682891 BATT_vBrick13_11 1;
BA_ "GenSigType" SG_ 2626748416 BATT_HarnessImpedance_7_0 1;
BA_ "GenSigType" SG_ 2626748416 BATT_HarnessImpedance_6_0 1;
BA_ "GenSigType" SG_ 2626748416 BATT_HarnessImpedance_5_0 1;
BA_ "GenSigType" SG_ 2626748416 BATT_HarnessImpedance_1_0 1;
BA_ "GenSigType" SG_ 2626748416 BATT_HarnessImpedance_0_0 1;
BA_ "GenSigType" SG_ 2626748416 BATT_HarnessImpedance_3_0 1;
BA_ "GenSigType" SG_ 2626748416 BATT_HarnessImpedance_4_0 1;
BA_ "GenSigType" SG_ 2626748416 BATT_HarnessImpedance_2_0 1;
BA_ "GenSigType" SG_ 2626748416 BATT_HarnessImpedance_8_0 1;
BA_ "GenSigType" SG_ 2626748416 BATT_HarnessImpedance_12_0 1;
BA_ "GenSigType" SG_ 2626748416 BATT_HarnessImpedance_13_0 1;
BA_ "GenSigType" SG_ 2626748416 BATT_HarnessImpedance_14_0 1;
BA_ "GenSigType" SG_ 2626748416 BATT_HarnessImpedance_11_0 1;
BA_ "GenSigType" SG_ 2626748416 BATT_HarnessImpedance_10_0 1;
BA_ "GenSigType" SG_ 2626748416 BATT_HarnessImpedance_9_0 1;
BA_ "GenSigType" SG_ 2626748417 BATT_HarnessImpedance_2_1 1;
BA_ "GenSigType" SG_ 2626748417 BATT_HarnessImpedance_3_1 1;
BA_ "GenSigType" SG_ 2626748417 BATT_HarnessImpedance_1_1 1;
BA_ "GenSigType" SG_ 2626748417 BATT_HarnessImpedance_0_1 1;
BA_ "GenSigType" SG_ 2626748417 BATT_HarnessImpedance_6_1 1;
BA_ "GenSigType" SG_ 2626748417 BATT_HarnessImpedance_11_1 1;
BA_ "GenSigType" SG_ 2626748417 BATT_HarnessImpedance_13_1 1;
BA_ "GenSigType" SG_ 2626748417 BATT_HarnessImpedance_12_1 1;
BA_ "GenSigType" SG_ 2626748417 BATT_HarnessImpedance_4_1 1;
BA_ "GenSigType" SG_ 2626748417 BATT_HarnessImpedance_14_1 1;
BA_ "GenSigType" SG_ 2626748417 BATT_HarnessImpedance_5_1 1;
BA_ "GenSigType" SG_ 2626748417 BATT_HarnessImpedance_9_1 1;
BA_ "GenSigType" SG_ 2626748417 BATT_HarnessImpedance_7_1 1;
BA_ "GenSigType" SG_ 2626748417 BATT_HarnessImpedance_10_1 1;
BA_ "GenSigType" SG_ 2626748417 BATT_HarnessImpedance_8_1 1;
BA_ "GenSigType" SG_ 2626748418 BATT_HarnessImpedance_7_2 1;
BA_ "GenSigType" SG_ 2626748418 BATT_HarnessImpedance_3_2 1;
BA_ "GenSigType" SG_ 2626748418 BATT_HarnessImpedance_4_2 1;
BA_ "GenSigType" SG_ 2626748418 BATT_HarnessImpedance_6_2 1;
BA_ "GenSigType" SG_ 2626748418 BATT_HarnessImpedance_1_2 1;
BA_ "GenSigType" SG_ 2626748418 BATT_HarnessImpedance_2_2 1;
BA_ "GenSigType" SG_ 2626748418 BATT_HarnessImpedance_0_2 1;
BA_ "GenSigType" SG_ 2626748418 BATT_HarnessImpedance_8_2 1;
BA_ "GenSigType" SG_ 2626748418 BATT_HarnessImpedance_10_2 1;
BA_ "GenSigType" SG_ 2626748418 BATT_HarnessImpedance_14_2 1;
BA_ "GenSigType" SG_ 2626748418 BATT_HarnessImpedance_13_2 1;
BA_ "GenSigType" SG_ 2626748418 BATT_HarnessImpedance_11_2 1;
BA_ "GenSigType" SG_ 2626748418 BATT_HarnessImpedance_12_2 1;
BA_ "GenSigType" SG_ 2626748418 BATT_HarnessImpedance_9_2 1;
BA_ "GenSigType" SG_ 2626748418 BATT_HarnessImpedance_5_2 1;
BA_ "GenSigType" SG_ 2626748419 BATT_HarnessImpedance_6_3 1;
BA_ "GenSigType" SG_ 2626748419 BATT_HarnessImpedance_8_3 1;
BA_ "GenSigType" SG_ 2626748419 BATT_HarnessImpedance_11_3 1;
BA_ "GenSigType" SG_ 2626748419 BATT_HarnessImpedance_7_3 1;
BA_ "GenSigType" SG_ 2626748419 BATT_HarnessImpedance_4_3 1;
BA_ "GenSigType" SG_ 2626748419 BATT_HarnessImpedance_5_3 1;
BA_ "GenSigType" SG_ 2626748419 BATT_HarnessImpedance_2_3 1;
BA_ "GenSigType" SG_ 2626748419 BATT_HarnessImpedance_3_3 1;
BA_ "GenSigType" SG_ 2626748419 BATT_HarnessImpedance_10_3 1;
BA_ "GenSigType" SG_ 2626748419 BATT_HarnessImpedance_14_3 1;
BA_ "GenSigType" SG_ 2626748419 BATT_HarnessImpedance_1_3 1;
BA_ "GenSigType" SG_ 2626748419 BATT_HarnessImpedance_0_3 1;
BA_ "GenSigType" SG_ 2626748419 BATT_HarnessImpedance_12_3 1;
BA_ "GenSigType" SG_ 2626748419 BATT_HarnessImpedance_13_3 1;
BA_ "GenSigType" SG_ 2626748419 BATT_HarnessImpedance_9_3 1;
BA_ "GenSigType" SG_ 2626748420 BATT_HarnessImpedance_13_4 1;
BA_ "GenSigType" SG_ 2626748420 BATT_HarnessImpedance_1_4 1;
BA_ "GenSigType" SG_ 2626748420 BATT_HarnessImpedance_12_4 1;
BA_ "GenSigType" SG_ 2626748420 BATT_HarnessImpedance_9_4 1;
BA_ "GenSigType" SG_ 2626748420 BATT_HarnessImpedance_14_4 1;
BA_ "GenSigType" SG_ 2626748420 BATT_HarnessImpedance_7_4 1;
BA_ "GenSigType" SG_ 2626748420 BATT_HarnessImpedance_10_4 1;
BA_ "GenSigType" SG_ 2626748420 BATT_HarnessImpedance_5_4 1;
BA_ "GenSigType" SG_ 2626748420 BATT_HarnessImpedance_11_4 1;
BA_ "GenSigType" SG_ 2626748420 BATT_HarnessImpedance_6_4 1;
BA_ "GenSigType" SG_ 2626748420 BATT_HarnessImpedance_8_4 1;
BA_ "GenSigType" SG_ 2626748420 BATT_HarnessImpedance_3_4 1;
BA_ "GenSigType" SG_ 2626748420 BATT_HarnessImpedance_0_4 1;
BA_ "GenSigType" SG_ 2626748420 BATT_HarnessImpedance_4_4 1;
BA_ "GenSigType" SG_ 2626748420 BATT_HarnessImpedance_2_4 1;
BA_ "GenSigType" SG_ 2626748421 BATT_HarnessImpedance_0_5 1;
BA_ "GenSigType" SG_ 2626748421 BATT_HarnessImpedance_14_5 1;
BA_ "GenSigType" SG_ 2626748421 BATT_HarnessImpedance_1_5 1;
BA_ "GenSigType" SG_ 2626748421 BATT_HarnessImpedance_6_5 1;
BA_ "GenSigType" SG_ 2626748421 BATT_HarnessImpedance_11_5 1;
BA_ "GenSigType" SG_ 2626748421 BATT_HarnessImpedance_10_5 1;
BA_ "GenSigType" SG_ 2626748421 BATT_HarnessImpedance_3_5 1;
BA_ "GenSigType" SG_ 2626748421 BATT_HarnessImpedance_12_5 1;
BA_ "GenSigType" SG_ 2626748421 BATT_HarnessImpedance_7_5 1;
BA_ "GenSigType" SG_ 2626748421 BATT_HarnessImpedance_9_5 1;
BA_ "GenSigType" SG_ 2626748421 BATT_HarnessImpedance_8_5 1;
BA_ "GenSigType" SG_ 2626748421 BATT_HarnessImpedance_4_5 1;
BA_ "GenSigType" SG_ 2626748421 BATT_HarnessImpedance_5_5 1;
BA_ "GenSigType" SG_ 2626748421 BATT_HarnessImpedance_2_5 1;
BA_ "GenSigType" SG_ 2626748421 BATT_HarnessImpedance_13_5 1;
BA_ "GenSigType" SG_ 2626748422 BATT_HarnessImpedance_0_6 1;
BA_ "GenSigType" SG_ 2626748422 BATT_HarnessImpedance_2_6 1;
BA_ "GenSigType" SG_ 2626748422 BATT_HarnessImpedance_1_6 1;
BA_ "GenSigType" SG_ 2626748422 BATT_HarnessImpedance_4_6 1;
BA_ "GenSigType" SG_ 2626748422 BATT_HarnessImpedance_3_6 1;
BA_ "GenSigType" SG_ 2626748422 BATT_HarnessImpedance_6_6 1;
BA_ "GenSigType" SG_ 2626748422 BATT_HarnessImpedance_5_6 1;
BA_ "GenSigType" SG_ 2626748422 BATT_HarnessImpedance_7_6 1;
BA_ "GenSigType" SG_ 2626748422 BATT_HarnessImpedance_14_6 1;
BA_ "GenSigType" SG_ 2626748422 BATT_HarnessImpedance_12_6 1;
BA_ "GenSigType" SG_ 2626748422 BATT_HarnessImpedance_8_6 1;
BA_ "GenSigType" SG_ 2626748422 BATT_HarnessImpedance_13_6 1;
BA_ "GenSigType" SG_ 2626748422 BATT_HarnessImpedance_9_6 1;
BA_ "GenSigType" SG_ 2626748422 BATT_HarnessImpedance_10_6 1;
BA_ "GenSigType" SG_ 2626748422 BATT_HarnessImpedance_11_6 1;
BA_ "GenSigType" SG_ 2626748423 BATT_HarnessImpedance_13_7 1;
BA_ "GenSigType" SG_ 2626748423 BATT_HarnessImpedance_14_7 1;
BA_ "GenSigType" SG_ 2626748423 BATT_HarnessImpedance_1_7 1;
BA_ "GenSigType" SG_ 2626748423 BATT_HarnessImpedance_4_7 1;
BA_ "GenSigType" SG_ 2626748423 BATT_HarnessImpedance_0_7 1;
BA_ "GenSigType" SG_ 2626748423 BATT_HarnessImpedance_2_7 1;
BA_ "GenSigType" SG_ 2626748423 BATT_HarnessImpedance_3_7 1;
BA_ "GenSigType" SG_ 2626748423 BATT_HarnessImpedance_12_7 1;
BA_ "GenSigType" SG_ 2626748423 BATT_HarnessImpedance_11_7 1;
BA_ "GenSigType" SG_ 2626748423 BATT_HarnessImpedance_7_7 1;
BA_ "GenSigType" SG_ 2626748423 BATT_HarnessImpedance_9_7 1;
BA_ "GenSigType" SG_ 2626748423 BATT_HarnessImpedance_8_7 1;
BA_ "GenSigType" SG_ 2626748423 BATT_HarnessImpedance_10_7 1;
BA_ "GenSigType" SG_ 2626748423 BATT_HarnessImpedance_5_7 1;
BA_ "GenSigType" SG_ 2626748423 BATT_HarnessImpedance_6_7 1;
BA_ "GenSigType" SG_ 2626748424 BATT_HarnessImpedance_0_8 1;
BA_ "GenSigType" SG_ 2626748424 BATT_HarnessImpedance_5_8 1;
BA_ "GenSigType" SG_ 2626748424 BATT_HarnessImpedance_3_8 1;
BA_ "GenSigType" SG_ 2626748424 BATT_HarnessImpedance_4_8 1;
BA_ "GenSigType" SG_ 2626748424 BATT_HarnessImpedance_8_8 1;
BA_ "GenSigType" SG_ 2626748424 BATT_HarnessImpedance_1_8 1;
BA_ "GenSigType" SG_ 2626748424 BATT_HarnessImpedance_11_8 1;
BA_ "GenSigType" SG_ 2626748424 BATT_HarnessImpedance_10_8 1;
BA_ "GenSigType" SG_ 2626748424 BATT_HarnessImpedance_7_8 1;
BA_ "GenSigType" SG_ 2626748424 BATT_HarnessImpedance_9_8 1;
BA_ "GenSigType" SG_ 2626748424 BATT_HarnessImpedance_12_8 1;
BA_ "GenSigType" SG_ 2626748424 BATT_HarnessImpedance_13_8 1;
BA_ "GenSigType" SG_ 2626748424 BATT_HarnessImpedance_14_8 1;
BA_ "GenSigType" SG_ 2626748424 BATT_HarnessImpedance_2_8 1;
BA_ "GenSigType" SG_ 2626748424 BATT_HarnessImpedance_6_8 1;
BA_ "GenSigType" SG_ 2626748425 BATT_HarnessImpedance_3_9 1;
BA_ "GenSigType" SG_ 2626748425 BATT_HarnessImpedance_2_9 1;
BA_ "GenSigType" SG_ 2626748425 BATT_HarnessImpedance_1_9 1;
BA_ "GenSigType" SG_ 2626748425 BATT_HarnessImpedance_11_9 1;
BA_ "GenSigType" SG_ 2626748425 BATT_HarnessImpedance_12_9 1;
BA_ "GenSigType" SG_ 2626748425 BATT_HarnessImpedance_13_9 1;
BA_ "GenSigType" SG_ 2626748425 BATT_HarnessImpedance_10_9 1;
BA_ "GenSigType" SG_ 2626748425 BATT_HarnessImpedance_14_9 1;
BA_ "GenSigType" SG_ 2626748425 BATT_HarnessImpedance_5_9 1;
BA_ "GenSigType" SG_ 2626748425 BATT_HarnessImpedance_4_9 1;
BA_ "GenSigType" SG_ 2626748425 BATT_HarnessImpedance_6_9 1;
BA_ "GenSigType" SG_ 2626748425 BATT_HarnessImpedance_7_9 1;
BA_ "GenSigType" SG_ 2626748425 BATT_HarnessImpedance_8_9 1;
BA_ "GenSigType" SG_ 2626748425 BATT_HarnessImpedance_9_9 1;
BA_ "GenSigType" SG_ 2626748425 BATT_HarnessImpedance_0_9 1;
BA_ "GenSigType" SG_ 2626748426 BATT_HarnessImpedance_5_10 1;
BA_ "GenSigType" SG_ 2626748426 BATT_HarnessImpedance_14_10 1;
BA_ "GenSigType" SG_ 2626748426 BATT_HarnessImpedance_13_10 1;
BA_ "GenSigType" SG_ 2626748426 BATT_HarnessImpedance_8_10 1;
BA_ "GenSigType" SG_ 2626748426 BATT_HarnessImpedance_7_10 1;
BA_ "GenSigType" SG_ 2626748426 BATT_HarnessImpedance_2_10 1;
BA_ "GenSigType" SG_ 2626748426 BATT_HarnessImpedance_1_10 1;
BA_ "GenSigType" SG_ 2626748426 BATT_HarnessImpedance_10_10 1;
BA_ "GenSigType" SG_ 2626748426 BATT_HarnessImpedance_9_10 1;
BA_ "GenSigType" SG_ 2626748426 BATT_HarnessImpedance_4_10 1;
BA_ "GenSigType" SG_ 2626748426 BATT_HarnessImpedance_3_10 1;
BA_ "GenSigType" SG_ 2626748426 BATT_HarnessImpedance_12_10 1;
BA_ "GenSigType" SG_ 2626748426 BATT_HarnessImpedance_11_10 1;
BA_ "GenSigType" SG_ 2626748426 BATT_HarnessImpedance_6_10 1;
BA_ "GenSigType" SG_ 2626748426 BATT_HarnessImpedance_0_10 1;
BA_ "GenSigType" SG_ 2626748427 BATT_HarnessImpedance_13_11 1;
BA_ "GenSigType" SG_ 2626748427 BATT_HarnessImpedance_12_11 1;
BA_ "GenSigType" SG_ 2626748427 BATT_HarnessImpedance_14_11 1;
BA_ "GenSigType" SG_ 2626748427 BATT_HarnessImpedance_11_11 1;
BA_ "GenSigType" SG_ 2626748427 BATT_HarnessImpedance_6_11 1;
BA_ "GenSigType" SG_ 2626748427 BATT_HarnessImpedance_5_11 1;
BA_ "GenSigType" SG_ 2626748427 BATT_HarnessImpedance_4_11 1;
BA_ "GenSigType" SG_ 2626748427 BATT_HarnessImpedance_3_11 1;
BA_ "GenSigType" SG_ 2626748427 BATT_HarnessImpedance_2_11 1;
BA_ "GenSigType" SG_ 2626748427 BATT_HarnessImpedance_8_11 1;
BA_ "GenSigType" SG_ 2626748427 BATT_HarnessImpedance_7_11 1;
BA_ "GenSigType" SG_ 2626748427 BATT_HarnessImpedance_10_11 1;
BA_ "GenSigType" SG_ 2626748427 BATT_HarnessImpedance_9_11 1;
BA_ "GenSigType" SG_ 2626748427 BATT_HarnessImpedance_1_11 1;
BA_ "GenSigType" SG_ 2626748427 BATT_HarnessImpedance_0_11 1;
BA_ "GenSigType" SG_ 2626813952 BATT_HrnsImpDelta_1_0 1;
BA_ "GenSigType" SG_ 2626813952 BATT_HrnsImpDelta_3_0 1;
BA_ "GenSigType" SG_ 2626813952 BATT_HrnsImpDelta_0_0 1;
BA_ "GenSigType" SG_ 2626813952 BATT_HrnsImpDelta_2_0 1;
BA_ "GenSigType" SG_ 2626813953 BATT_HrnsImpDelta_3_1 1;
BA_ "GenSigType" SG_ 2626813953 BATT_HrnsImpDelta_1_1 1;
BA_ "GenSigType" SG_ 2626813953 BATT_HrnsImpDelta_2_1 1;
BA_ "GenSigType" SG_ 2626813953 BATT_HrnsImpDelta_0_1 1;
BA_ "GenSigType" SG_ 2626813954 BATT_HrnsImpDelta_0_2 1;
BA_ "GenSigType" SG_ 2626813954 BATT_HrnsImpDelta_3_2 1;
BA_ "GenSigType" SG_ 2626813954 BATT_HrnsImpDelta_2_2 1;
BA_ "GenSigType" SG_ 2626813954 BATT_HrnsImpDelta_1_2 1;
BA_ "GenSigType" SG_ 2626813955 BATT_HrnsImpDelta_0_3 1;
BA_ "GenSigType" SG_ 2626813955 BATT_HrnsImpDelta_1_3 1;
BA_ "GenSigType" SG_ 2626813955 BATT_HrnsImpDelta_3_3 1;
BA_ "GenSigType" SG_ 2626813955 BATT_HrnsImpDelta_2_3 1;
BA_ "GenSigType" SG_ 2626813956 BATT_HrnsImpDelta_1_4 1;
BA_ "GenSigType" SG_ 2626813956 BATT_HrnsImpDelta_3_4 1;
BA_ "GenSigType" SG_ 2626813956 BATT_HrnsImpDelta_2_4 1;
BA_ "GenSigType" SG_ 2626813956 BATT_HrnsImpDelta_0_4 1;
BA_ "GenSigType" SG_ 2626813957 BATT_HrnsImpDelta_2_5 1;
BA_ "GenSigType" SG_ 2626813957 BATT_HrnsImpDelta_3_5 1;
BA_ "GenSigType" SG_ 2626813957 BATT_HrnsImpDelta_1_5 1;
BA_ "GenSigType" SG_ 2626813957 BATT_HrnsImpDelta_0_5 1;
BA_ "GenSigSNA" SG_ 2621702151 BATT_capBrick04_7 65535;
BA_ "GenSigSNA" SG_ 2621702151 BATT_capBrick03_7 65535;
BA_ "GenSigSNA" SG_ 2621702151 BATT_capBrick02_7 65535;
BA_ "GenSigSNA" SG_ 2621702151 BATT_capBrick01_7 65535;
BA_ "GenSigSNA" SG_ 2621702152 BATT_capBrick04_8 65535;
BA_ "GenSigSNA" SG_ 2621702152 BATT_capBrick03_8 65535;
BA_ "GenSigSNA" SG_ 2621702152 BATT_capBrick02_8 65535;
BA_ "GenSigSNA" SG_ 2621702152 BATT_capBrick01_8 65535;
BA_ "GenSigSNA" SG_ 2621702153 BATT_capBrick04_9 65535;
BA_ "GenSigSNA" SG_ 2621702153 BATT_capBrick03_9 65535;
BA_ "GenSigSNA" SG_ 2621702153 BATT_capBrick02_9 65535;
BA_ "GenSigSNA" SG_ 2621702153 BATT_capBrick01_9 65535;
BA_ "GenSigSNA" SG_ 2621702154 BATT_capBrick04_10 65535;
BA_ "GenSigSNA" SG_ 2621702154 BATT_capBrick03_10 65535;
BA_ "GenSigSNA" SG_ 2621702154 BATT_capBrick02_10 65535;
BA_ "GenSigSNA" SG_ 2621702154 BATT_capBrick01_10 65535;
BA_ "GenSigSNA" SG_ 2621702155 BATT_capBrick04_11 65535;
BA_ "GenSigSNA" SG_ 2621702155 BATT_capBrick03_11 65535;
BA_ "GenSigSNA" SG_ 2621702155 BATT_capBrick02_11 65535;
BA_ "GenSigSNA" SG_ 2621702155 BATT_capBrick01_11 65535;
BA_ "GenSigSNA" SG_ 2621964288 BATT_capBrick08_0 65535;
BA_ "GenSigSNA" SG_ 2621964288 BATT_capBrick07_0 65535;
BA_ "GenSigSNA" SG_ 2621964288 BATT_capBrick06_0 65535;
BA_ "GenSigSNA" SG_ 2621964288 BATT_capBrick05_0 65535;
BA_ "GenSigSNA" SG_ 2621964289 BATT_capBrick08_1 65535;
BA_ "GenSigSNA" SG_ 2621964289 BATT_capBrick07_1 65535;
BA_ "GenSigSNA" SG_ 2621964289 BATT_capBrick06_1 65535;
BA_ "GenSigSNA" SG_ 2621964289 BATT_capBrick05_1 65535;
BA_ "GenSigSNA" SG_ 2621964290 BATT_capBrick08_2 65535;
BA_ "GenSigSNA" SG_ 2621964290 BATT_capBrick07_2 65535;
BA_ "GenSigSNA" SG_ 2621964290 BATT_capBrick06_2 65535;
BA_ "GenSigSNA" SG_ 2621964290 BATT_capBrick05_2 65535;
BA_ "GenSigSNA" SG_ 2621964291 BATT_capBrick08_3 65535;
BA_ "GenSigSNA" SG_ 2621964291 BATT_capBrick07_3 65535;
BA_ "GenSigSNA" SG_ 2621964291 BATT_capBrick06_3 65535;
BA_ "GenSigSNA" SG_ 2621964291 BATT_capBrick05_3 65535;
BA_ "GenSigSNA" SG_ 2621964292 BATT_capBrick08_4 65535;
BA_ "GenSigSNA" SG_ 2621964292 BATT_capBrick07_4 65535;
BA_ "GenSigSNA" SG_ 2621964292 BATT_capBrick06_4 65535;
BA_ "GenSigSNA" SG_ 2621964292 BATT_capBrick05_4 65535;
BA_ "GenSigSNA" SG_ 2621964293 BATT_capBrick08_5 65535;
BA_ "GenSigSNA" SG_ 2621964293 BATT_capBrick07_5 65535;
BA_ "GenSigSNA" SG_ 2621964293 BATT_capBrick06_5 65535;
BA_ "GenSigSNA" SG_ 2621964293 BATT_capBrick05_5 65535;
BA_ "GenSigSNA" SG_ 2621964294 BATT_capBrick08_6 65535;
BA_ "GenSigSNA" SG_ 2621964294 BATT_capBrick07_6 65535;
BA_ "GenSigSNA" SG_ 2621964294 BATT_capBrick06_6 65535;
BA_ "GenSigSNA" SG_ 2621964294 BATT_capBrick05_6 65535;
BA_ "GenSigSNA" SG_ 2621964295 BATT_capBrick08_7 65535;
BA_ "GenSigSNA" SG_ 2621964295 BATT_capBrick07_7 65535;
BA_ "GenSigSNA" SG_ 2621964295 BATT_capBrick06_7 65535;
BA_ "GenSigSNA" SG_ 2621964295 BATT_capBrick05_7 65535;
BA_ "GenSigSNA" SG_ 2621964296 BATT_capBrick08_8 65535;
BA_ "GenSigSNA" SG_ 2621964296 BATT_capBrick07_8 65535;
BA_ "GenSigSNA" SG_ 2621964296 BATT_capBrick06_8 65535;
BA_ "GenSigSNA" SG_ 2621964296 BATT_capBrick05_8 65535;
BA_ "GenSigSNA" SG_ 2621964297 BATT_capBrick08_9 65535;
BA_ "GenSigSNA" SG_ 2621964297 BATT_capBrick07_9 65535;
BA_ "GenSigSNA" SG_ 2621964297 BATT_capBrick06_9 65535;
BA_ "GenSigSNA" SG_ 2621964297 BATT_capBrick05_9 65535;
BA_ "GenSigSNA" SG_ 2621964298 BATT_capBrick08_10 65535;
BA_ "GenSigSNA" SG_ 2621964298 BATT_capBrick07_10 65535;
BA_ "GenSigSNA" SG_ 2621964298 BATT_capBrick06_10 65535;
BA_ "GenSigSNA" SG_ 2621964298 BATT_capBrick05_10 65535;
BA_ "GenSigSNA" SG_ 2621964299 BATT_capBrick08_11 65535;
BA_ "GenSigSNA" SG_ 2621964299 BATT_capBrick07_11 65535;
BA_ "GenSigSNA" SG_ 2621964299 BATT_capBrick06_11 65535;
BA_ "GenSigSNA" SG_ 2621964299 BATT_capBrick05_11 65535;
BA_ "GenSigSNA" SG_ 2622226432 BATT_capBrick12_0 65535;
BA_ "GenSigSNA" SG_ 2622226432 BATT_capBrick11_0 65535;
BA_ "GenSigSNA" SG_ 2622226432 BATT_capBrick09_0 65535;
BA_ "GenSigSNA" SG_ 2622226432 BATT_capBrick10_0 65535;
BA_ "GenSigSNA" SG_ 2622226433 BATT_capBrick12_1 65535;
BA_ "GenSigSNA" SG_ 2622226433 BATT_capBrick11_1 65535;
BA_ "GenSigSNA" SG_ 2622226433 BATT_capBrick09_1 65535;
BA_ "GenSigSNA" SG_ 2622226433 BATT_capBrick10_1 65535;
BA_ "GenSigSNA" SG_ 2622226434 BATT_capBrick12_2 65535;
BA_ "GenSigSNA" SG_ 2622226434 BATT_capBrick11_2 65535;
BA_ "GenSigSNA" SG_ 2622226434 BATT_capBrick09_2 65535;
BA_ "GenSigSNA" SG_ 2622226434 BATT_capBrick10_2 65535;
BA_ "GenSigSNA" SG_ 2622226435 BATT_capBrick12_3 65535;
BA_ "GenSigSNA" SG_ 2622226435 BATT_capBrick11_3 65535;
BA_ "GenSigSNA" SG_ 2622226435 BATT_capBrick09_3 65535;
BA_ "GenSigSNA" SG_ 2622226435 BATT_capBrick10_3 65535;
BA_ "GenSigSNA" SG_ 2622226436 BATT_capBrick12_4 65535;
BA_ "GenSigSNA" SG_ 2622226436 BATT_capBrick11_4 65535;
BA_ "GenSigSNA" SG_ 2622226436 BATT_capBrick09_4 65535;
BA_ "GenSigSNA" SG_ 2622226436 BATT_capBrick10_4 65535;
BA_ "GenSigSNA" SG_ 2622226437 BATT_capBrick12_5 65535;
BA_ "GenSigSNA" SG_ 2622226437 BATT_capBrick11_5 65535;
BA_ "GenSigSNA" SG_ 2622226437 BATT_capBrick09_5 65535;
BA_ "GenSigSNA" SG_ 2622226437 BATT_capBrick10_5 65535;
BA_ "GenSigSNA" SG_ 2622226438 BATT_capBrick12_6 65535;
BA_ "GenSigSNA" SG_ 2622226438 BATT_capBrick11_6 65535;
BA_ "GenSigSNA" SG_ 2622226438 BATT_capBrick09_6 65535;
BA_ "GenSigSNA" SG_ 2622226438 BATT_capBrick10_6 65535;
BA_ "GenSigSNA" SG_ 2622226439 BATT_capBrick12_7 65535;
BA_ "GenSigSNA" SG_ 2622226439 BATT_capBrick11_7 65535;
BA_ "GenSigSNA" SG_ 2622226439 BATT_capBrick09_7 65535;
BA_ "GenSigSNA" SG_ 2622226439 BATT_capBrick10_7 65535;
BA_ "GenSigSNA" SG_ 2622226440 BATT_capBrick12_8 65535;
BA_ "GenSigSNA" SG_ 2622226440 BATT_capBrick11_8 65535;
BA_ "GenSigSNA" SG_ 2622226440 BATT_capBrick09_8 65535;
BA_ "GenSigSNA" SG_ 2622226440 BATT_capBrick10_8 65535;
BA_ "GenSigSNA" SG_ 2622226441 BATT_capBrick12_9 65535;
BA_ "GenSigSNA" SG_ 2622226441 BATT_capBrick11_9 65535;
BA_ "GenSigSNA" SG_ 2622226441 BATT_capBrick09_9 65535;
BA_ "GenSigSNA" SG_ 2622226441 BATT_capBrick10_9 65535;
BA_ "GenSigSNA" SG_ 2622226442 BATT_capBrick12_10 65535;
BA_ "GenSigSNA" SG_ 2622226442 BATT_capBrick11_10 65535;
BA_ "GenSigSNA" SG_ 2622226442 BATT_capBrick09_10 65535;
BA_ "GenSigSNA" SG_ 2622226442 BATT_capBrick10_10 65535;
BA_ "GenSigSNA" SG_ 2622226443 BATT_capBrick12_11 65535;
BA_ "GenSigSNA" SG_ 2622226443 BATT_capBrick11_11 65535;
BA_ "GenSigSNA" SG_ 2622226443 BATT_capBrick09_11 65535;
BA_ "GenSigSNA" SG_ 2622226443 BATT_capBrick10_11 65535;
BA_ "GenSigSNA" SG_ 2622488576 BATT_capBrick14_0 65535;
BA_ "GenSigSNA" SG_ 2622488576 BATT_capBrick13_0 65535;
BA_ "GenSigSNA" SG_ 2622488577 BATT_capBrick14_1 65535;
BA_ "GenSigSNA" SG_ 2622488577 BATT_capBrick13_1 65535;
BA_ "GenSigSNA" SG_ 2622488578 BATT_capBrick14_2 65535;
BA_ "GenSigSNA" SG_ 2622488578 BATT_capBrick13_2 65535;
BA_ "GenSigSNA" SG_ 2622488579 BATT_capBrick14_3 65535;
BA_ "GenSigSNA" SG_ 2622488579 BATT_capBrick13_3 65535;
BA_ "GenSigSNA" SG_ 2622488580 BATT_capBrick14_4 65535;
BA_ "GenSigSNA" SG_ 2622488580 BATT_capBrick13_4 65535;
BA_ "GenSigSNA" SG_ 2622488581 BATT_capBrick14_5 65535;
BA_ "GenSigSNA" SG_ 2622488581 BATT_capBrick13_5 65535;
BA_ "GenSigSNA" SG_ 2622488582 BATT_capBrick14_6 65535;
BA_ "GenSigSNA" SG_ 2622488582 BATT_capBrick13_6 65535;
BA_ "GenSigSNA" SG_ 2622488583 BATT_capBrick14_7 65535;
BA_ "GenSigSNA" SG_ 2622488583 BATT_capBrick13_7 65535;
BA_ "GenSigSNA" SG_ 2622488584 BATT_capBrick14_8 65535;
BA_ "GenSigSNA" SG_ 2622488584 BATT_capBrick13_8 65535;
BA_ "GenSigSNA" SG_ 2622488585 BATT_capBrick14_9 65535;
BA_ "GenSigSNA" SG_ 2622488585 BATT_capBrick13_9 65535;
BA_ "GenSigSNA" SG_ 2622488586 BATT_capBrick14_10 65535;
BA_ "GenSigSNA" SG_ 2622488586 BATT_capBrick13_10 65535;
BA_ "GenSigSNA" SG_ 2622488587 BATT_capBrick14_11 65535;
BA_ "GenSigSNA" SG_ 2622488587 BATT_capBrick13_11 65535;
BA_ "GenSigSNA" SG_ 2625896448 BATT_vBrick02_0 65535;
BA_ "GenSigSNA" SG_ 2625896448 BATT_vBrick03_0 65535;
BA_ "GenSigSNA" SG_ 2625896448 BATT_vBrick01_0 65535;
BA_ "GenSigSNA" SG_ 2625896448 BATT_vBrick04_0 65535;
BA_ "GenSigSNA" SG_ 2625896449 BATT_vBrick02_1 65535;
BA_ "GenSigSNA" SG_ 2625896449 BATT_vBrick03_1 65535;
BA_ "GenSigSNA" SG_ 2625896449 BATT_vBrick01_1 65535;
BA_ "GenSigSNA" SG_ 2625896449 BATT_vBrick04_1 65535;
BA_ "GenSigSNA" SG_ 2625896450 BATT_vBrick02_2 65535;
BA_ "GenSigSNA" SG_ 2625896450 BATT_vBrick03_2 65535;
BA_ "GenSigSNA" SG_ 2625896450 BATT_vBrick01_2 65535;
BA_ "GenSigSNA" SG_ 2625896450 BATT_vBrick04_2 65535;
BA_ "GenSigSNA" SG_ 2625896451 BATT_vBrick02_3 65535;
BA_ "GenSigSNA" SG_ 2625896451 BATT_vBrick03_3 65535;
BA_ "GenSigSNA" SG_ 2625896451 BATT_vBrick01_3 65535;
BA_ "GenSigSNA" SG_ 2625896451 BATT_vBrick04_3 65535;
BA_ "GenSigSNA" SG_ 2625896452 BATT_vBrick02_4 65535;
BA_ "GenSigSNA" SG_ 2625896452 BATT_vBrick03_4 65535;
BA_ "GenSigSNA" SG_ 2625896452 BATT_vBrick01_4 65535;
BA_ "GenSigSNA" SG_ 2625896452 BATT_vBrick04_4 65535;
BA_ "GenSigSNA" SG_ 2625896453 BATT_vBrick02_5 65535;
BA_ "GenSigSNA" SG_ 2625896453 BATT_vBrick03_5 65535;
BA_ "GenSigSNA" SG_ 2625896453 BATT_vBrick01_5 65535;
BA_ "GenSigSNA" SG_ 2625896453 BATT_vBrick04_5 65535;
BA_ "GenSigSNA" SG_ 2625896454 BATT_vBrick02_6 65535;
BA_ "GenSigSNA" SG_ 2625896454 BATT_vBrick03_6 65535;
BA_ "GenSigSNA" SG_ 2625896454 BATT_vBrick01_6 65535;
BA_ "GenSigSNA" SG_ 2625896454 BATT_vBrick04_6 65535;
BA_ "GenSigSNA" SG_ 2625896455 BATT_vBrick02_7 65535;
BA_ "GenSigSNA" SG_ 2625896455 BATT_vBrick03_7 65535;
BA_ "GenSigSNA" SG_ 2625896455 BATT_vBrick01_7 65535;
BA_ "GenSigSNA" SG_ 2625896455 BATT_vBrick04_7 65535;
BA_ "GenSigSNA" SG_ 2625896456 BATT_vBrick02_8 65535;
BA_ "GenSigSNA" SG_ 2625896456 BATT_vBrick03_8 65535;
BA_ "GenSigSNA" SG_ 2625896456 BATT_vBrick01_8 65535;
BA_ "GenSigSNA" SG_ 2625896456 BATT_vBrick04_8 65535;
BA_ "GenSigSNA" SG_ 2625896457 BATT_vBrick02_9 65535;
BA_ "GenSigSNA" SG_ 2625896457 BATT_vBrick03_9 65535;
BA_ "GenSigSNA" SG_ 2625896457 BATT_vBrick01_9 65535;
BA_ "GenSigSNA" SG_ 2625896457 BATT_vBrick04_9 65535;
BA_ "GenSigSNA" SG_ 2625896458 BATT_vBrick02_10 65535;
BA_ "GenSigSNA" SG_ 2625896458 BATT_vBrick03_10 65535;
BA_ "GenSigSNA" SG_ 2625896458 BATT_vBrick01_10 65535;
BA_ "GenSigSNA" SG_ 2625896458 BATT_vBrick04_10 65535;
BA_ "GenSigSNA" SG_ 2625896459 BATT_vBrick02_11 65535;
BA_ "GenSigSNA" SG_ 2625896459 BATT_vBrick03_11 65535;
BA_ "GenSigSNA" SG_ 2625896459 BATT_vBrick01_11 65535;
BA_ "GenSigSNA" SG_ 2625896459 BATT_vBrick04_11 65535;
BA_ "GenSigSNA" SG_ 2626158592 BATT_vBrick06_0 65535;
BA_ "GenSigSNA" SG_ 2626158592 BATT_vBrick07_0 65535;
BA_ "GenSigSNA" SG_ 2626158592 BATT_vBrick05_0 65535;
BA_ "GenSigSNA" SG_ 2626158592 BATT_vBrick08_0 65535;
BA_ "GenSigSNA" SG_ 2626158593 BATT_vBrick06_1 65535;
BA_ "GenSigSNA" SG_ 2626158593 BATT_vBrick07_1 65535;
BA_ "GenSigSNA" SG_ 2626158593 BATT_vBrick05_1 65535;
BA_ "GenSigSNA" SG_ 2626158593 BATT_vBrick08_1 65535;
BA_ "GenSigSNA" SG_ 2626158594 BATT_vBrick06_2 65535;
BA_ "GenSigSNA" SG_ 2626158594 BATT_vBrick07_2 65535;
BA_ "GenSigSNA" SG_ 2626158594 BATT_vBrick05_2 65535;
BA_ "GenSigSNA" SG_ 2626158594 BATT_vBrick08_2 65535;
BA_ "GenSigSNA" SG_ 2626158595 BATT_vBrick06_3 65535;
BA_ "GenSigSNA" SG_ 2626158595 BATT_vBrick07_3 65535;
BA_ "GenSigSNA" SG_ 2626158595 BATT_vBrick05_3 65535;
BA_ "GenSigSNA" SG_ 2626158595 BATT_vBrick08_3 65535;
BA_ "GenSigSNA" SG_ 2626158596 BATT_vBrick06_4 65535;
BA_ "GenSigSNA" SG_ 2626158596 BATT_vBrick07_4 65535;
BA_ "GenSigSNA" SG_ 2626158596 BATT_vBrick05_4 65535;
BA_ "GenSigSNA" SG_ 2626158596 BATT_vBrick08_4 65535;
BA_ "GenSigSNA" SG_ 2626158597 BATT_vBrick06_5 65535;
BA_ "GenSigSNA" SG_ 2626158597 BATT_vBrick07_5 65535;
BA_ "GenSigSNA" SG_ 2626158597 BATT_vBrick05_5 65535;
BA_ "GenSigSNA" SG_ 2626158597 BATT_vBrick08_5 65535;
BA_ "GenSigSNA" SG_ 2626158598 BATT_vBrick06_6 65535;
BA_ "GenSigSNA" SG_ 2626158598 BATT_vBrick07_6 65535;
BA_ "GenSigSNA" SG_ 2626158598 BATT_vBrick05_6 65535;
BA_ "GenSigSNA" SG_ 2626158598 BATT_vBrick08_6 65535;
BA_ "GenSigSNA" SG_ 2626158599 BATT_vBrick06_7 65535;
BA_ "GenSigSNA" SG_ 2626158599 BATT_vBrick07_7 65535;
BA_ "GenSigSNA" SG_ 2626158599 BATT_vBrick05_7 65535;
BA_ "GenSigSNA" SG_ 2626158599 BATT_vBrick08_7 65535;
BA_ "GenSigSNA" SG_ 2626158600 BATT_vBrick06_8 65535;
BA_ "GenSigSNA" SG_ 2626158600 BATT_vBrick07_8 65535;
BA_ "GenSigSNA" SG_ 2626158600 BATT_vBrick05_8 65535;
BA_ "GenSigSNA" SG_ 2626158600 BATT_vBrick08_8 65535;
BA_ "GenSigSNA" SG_ 2626158601 BATT_vBrick06_9 65535;
BA_ "GenSigSNA" SG_ 2626158601 BATT_vBrick07_9 65535;
BA_ "GenSigSNA" SG_ 2626158601 BATT_vBrick05_9 65535;
BA_ "GenSigSNA" SG_ 2626158601 BATT_vBrick08_9 65535;
BA_ "GenSigSNA" SG_ 2626158602 BATT_vBrick06_10 65535;
BA_ "GenSigSNA" SG_ 2626158602 BATT_vBrick07_10 65535;
BA_ "GenSigSNA" SG_ 2626158602 BATT_vBrick05_10 65535;
BA_ "GenSigSNA" SG_ 2626158602 BATT_vBrick08_10 65535;
BA_ "GenSigSNA" SG_ 2626158603 BATT_vBrick06_11 65535;
BA_ "GenSigSNA" SG_ 2626158603 BATT_vBrick07_11 65535;
BA_ "GenSigSNA" SG_ 2626158603 BATT_vBrick05_11 65535;
BA_ "GenSigSNA" SG_ 2626158603 BATT_vBrick08_11 65535;
BA_ "GenSigSNA" SG_ 2626420736 BATT_vBrick12_0 65535;
BA_ "GenSigSNA" SG_ 2626420736 BATT_vBrick11_0 65535;
BA_ "GenSigSNA" SG_ 2626420736 BATT_vBrick10_0 65535;
BA_ "GenSigSNA" SG_ 2626420736 BATT_vBrick09_0 65535;
BA_ "GenSigSNA" SG_ 2626420737 BATT_vBrick12_1 65535;
BA_ "GenSigSNA" SG_ 2626420737 BATT_vBrick11_1 65535;
BA_ "GenSigSNA" SG_ 2626420737 BATT_vBrick10_1 65535;
BA_ "GenSigSNA" SG_ 2626420737 BATT_vBrick09_1 65535;
BA_ "GenSigSNA" SG_ 2626420738 BATT_vBrick12_2 65535;
BA_ "GenSigSNA" SG_ 2626420738 BATT_vBrick11_2 65535;
BA_ "GenSigSNA" SG_ 2626420738 BATT_vBrick10_2 65535;
BA_ "GenSigSNA" SG_ 2626420738 BATT_vBrick09_2 65535;
BA_ "GenSigSNA" SG_ 2626420739 BATT_vBrick12_3 65535;
BA_ "GenSigSNA" SG_ 2626420739 BATT_vBrick11_3 65535;
BA_ "GenSigSNA" SG_ 2626420739 BATT_vBrick10_3 65535;
BA_ "GenSigSNA" SG_ 2626420739 BATT_vBrick09_3 65535;
BA_ "GenSigSNA" SG_ 2626420740 BATT_vBrick12_4 65535;
BA_ "GenSigSNA" SG_ 2626420740 BATT_vBrick11_4 65535;
BA_ "GenSigSNA" SG_ 2626420740 BATT_vBrick10_4 65535;
BA_ "GenSigSNA" SG_ 2626420740 BATT_vBrick09_4 65535;
BA_ "GenSigSNA" SG_ 2626420741 BATT_vBrick12_5 65535;
BA_ "GenSigSNA" SG_ 2626420741 BATT_vBrick11_5 65535;
BA_ "GenSigSNA" SG_ 2626420741 BATT_vBrick10_5 65535;
BA_ "GenSigSNA" SG_ 2626420741 BATT_vBrick09_5 65535;
BA_ "GenSigSNA" SG_ 2626420742 BATT_vBrick12_6 65535;
BA_ "GenSigSNA" SG_ 2626420742 BATT_vBrick11_6 65535;
BA_ "GenSigSNA" SG_ 2626420742 BATT_vBrick10_6 65535;
BA_ "GenSigSNA" SG_ 2626420742 BATT_vBrick09_6 65535;
BA_ "GenSigSNA" SG_ 2626420743 BATT_vBrick12_7 65535;
BA_ "GenSigSNA" SG_ 2626420743 BATT_vBrick11_7 65535;
BA_ "GenSigSNA" SG_ 2626420743 BATT_vBrick10_7 65535;
BA_ "GenSigSNA" SG_ 2626420743 BATT_vBrick09_7 65535;
BA_ "GenSigSNA" SG_ 2626420744 BATT_vBrick12_8 65535;
BA_ "GenSigSNA" SG_ 2626420744 BATT_vBrick11_8 65535;
BA_ "GenSigSNA" SG_ 2626420744 BATT_vBrick10_8 65535;
BA_ "GenSigSNA" SG_ 2626420744 BATT_vBrick09_8 65535;
BA_ "GenSigSNA" SG_ 2626420745 BATT_vBrick12_9 65535;
BA_ "GenSigSNA" SG_ 2626420745 BATT_vBrick11_9 65535;
BA_ "GenSigSNA" SG_ 2626420745 BATT_vBrick10_9 65535;
BA_ "GenSigSNA" SG_ 2626420745 BATT_vBrick09_9 65535;
BA_ "GenSigSNA" SG_ 2626420746 BATT_vBrick12_10 65535;
BA_ "GenSigSNA" SG_ 2626420746 BATT_vBrick11_10 65535;
BA_ "GenSigSNA" SG_ 2626420746 BATT_vBrick10_10 65535;
BA_ "GenSigSNA" SG_ 2626420746 BATT_vBrick09_10 65535;
BA_ "GenSigSNA" SG_ 2626420747 BATT_vBrick12_11 65535;
BA_ "GenSigSNA" SG_ 2626420747 BATT_vBrick11_11 65535;
BA_ "GenSigSNA" SG_ 2626420747 BATT_vBrick10_11 65535;
BA_ "GenSigSNA" SG_ 2626420747 BATT_vBrick09_11 65535;
BA_ "GenSigSNA" SG_ 2626682880 BATT_vBrick14_0 65535;
BA_ "GenSigSNA" SG_ 2626682880 BATT_vBrick13_0 65535;
BA_ "GenSigSNA" SG_ 2626682881 BATT_vBrick14_1 65535;
BA_ "GenSigSNA" SG_ 2626682881 BATT_vBrick13_1 65535;
BA_ "GenSigSNA" SG_ 2626682882 BATT_vBrick14_2 65535;
BA_ "GenSigSNA" SG_ 2626682882 BATT_vBrick13_2 65535;
BA_ "GenSigSNA" SG_ 2626682883 BATT_vBrick14_3 65535;
BA_ "GenSigSNA" SG_ 2626682883 BATT_vBrick13_3 65535;
BA_ "GenSigSNA" SG_ 2626682884 BATT_vBrick14_4 65535;
BA_ "GenSigSNA" SG_ 2626682884 BATT_vBrick13_4 65535;
BA_ "GenSigSNA" SG_ 2626682885 BATT_vBrick14_5 65535;
BA_ "GenSigSNA" SG_ 2626682885 BATT_vBrick13_5 65535;
BA_ "GenSigSNA" SG_ 2626682886 BATT_vBrick14_6 65535;
BA_ "GenSigSNA" SG_ 2626682886 BATT_vBrick13_6 65535;
BA_ "GenSigSNA" SG_ 2626682887 BATT_vBrick14_7 65535;
BA_ "GenSigSNA" SG_ 2626682887 BATT_vBrick13_7 65535;
BA_ "GenSigSNA" SG_ 2626682888 BATT_vBrick14_8 65535;
BA_ "GenSigSNA" SG_ 2626682888 BATT_vBrick13_8 65535;
BA_ "GenSigSNA" SG_ 2626682889 BATT_vBrick14_9 65535;
BA_ "GenSigSNA" SG_ 2626682889 BATT_vBrick13_9 65535;
BA_ "GenSigSNA" SG_ 2626682890 BATT_vBrick14_10 65535;
BA_ "GenSigSNA" SG_ 2626682890 BATT_vBrick13_10 65535;
BA_ "GenSigSNA" SG_ 2626682891 BATT_vBrick14_11 65535;
BA_ "GenSigSNA" SG_ 2626682891 BATT_vBrick13_11 65535;
BA_ "GenSigSNA" SG_ 2626748416 BATT_HarnessImpedance_7_0 65535;
BA_ "GenSigSNA" SG_ 2626748416 BATT_HarnessImpedance_6_0 65535;
BA_ "GenSigSNA" SG_ 2626748416 BATT_HarnessImpedance_5_0 65535;
BA_ "GenSigSNA" SG_ 2626748416 BATT_HarnessImpedance_1_0 65535;
BA_ "GenSigSNA" SG_ 2626748416 BATT_HarnessImpedance_0_0 65535;
BA_ "GenSigSNA" SG_ 2626748416 BATT_HarnessImpedance_3_0 65535;
BA_ "GenSigSNA" SG_ 2626748416 BATT_HarnessImpedance_4_0 65535;
BA_ "GenSigSNA" SG_ 2626748416 BATT_HarnessImpedance_2_0 65535;
BA_ "GenSigSNA" SG_ 2626748416 BATT_HarnessImpedance_8_0 65535;
BA_ "GenSigSNA" SG_ 2626748416 BATT_HarnessImpedance_12_0 65535;
BA_ "GenSigSNA" SG_ 2626748416 BATT_HarnessImpedance_13_0 65535;
BA_ "GenSigSNA" SG_ 2626748416 BATT_HarnessImpedance_14_0 65535;
BA_ "GenSigSNA" SG_ 2626748416 BATT_HarnessImpedance_11_0 65535;
BA_ "GenSigSNA" SG_ 2626748416 BATT_HarnessImpedance_10_0 65535;
BA_ "GenSigSNA" SG_ 2626748416 BATT_HarnessImpedance_9_0 65535;
BA_ "GenSigSNA" SG_ 2626748417 BATT_HarnessImpedance_2_1 65535;
BA_ "GenSigSNA" SG_ 2626748417 BATT_HarnessImpedance_3_1 65535;
BA_ "GenSigSNA" SG_ 2626748417 BATT_HarnessImpedance_1_1 65535;
BA_ "GenSigSNA" SG_ 2626748417 BATT_HarnessImpedance_0_1 65535;
BA_ "GenSigSNA" SG_ 2626748417 BATT_HarnessImpedance_6_1 65535;
BA_ "GenSigSNA" SG_ 2626748417 BATT_HarnessImpedance_11_1 65535;
BA_ "GenSigSNA" SG_ 2626748417 BATT_HarnessImpedance_13_1 65535;
BA_ "GenSigSNA" SG_ 2626748417 BATT_HarnessImpedance_12_1 65535;
BA_ "GenSigSNA" SG_ 2626748417 BATT_HarnessImpedance_4_1 65535;
BA_ "GenSigSNA" SG_ 2626748417 BATT_HarnessImpedance_14_1 65535;
BA_ "GenSigSNA" SG_ 2626748417 BATT_HarnessImpedance_5_1 65535;
BA_ "GenSigSNA" SG_ 2626748417 BATT_HarnessImpedance_9_1 65535;
BA_ "GenSigSNA" SG_ 2626748417 BATT_HarnessImpedance_7_1 65535;
BA_ "GenSigSNA" SG_ 2626748417 BATT_HarnessImpedance_10_1 65535;
BA_ "GenSigSNA" SG_ 2626748417 BATT_HarnessImpedance_8_1 65535;
BA_ "GenSigSNA" SG_ 2626748418 BATT_HarnessImpedance_7_2 65535;
BA_ "GenSigSNA" SG_ 2626748418 BATT_HarnessImpedance_3_2 65535;
BA_ "GenSigSNA" SG_ 2626748418 BATT_HarnessImpedance_4_2 65535;
BA_ "GenSigSNA" SG_ 2626748418 BATT_HarnessImpedance_6_2 65535;
BA_ "GenSigSNA" SG_ 2626748418 BATT_HarnessImpedance_1_2 65535;
BA_ "GenSigSNA" SG_ 2626748418 BATT_HarnessImpedance_2_2 65535;
BA_ "GenSigSNA" SG_ 2626748418 BATT_HarnessImpedance_0_2 65535;
BA_ "GenSigSNA" SG_ 2626748418 BATT_HarnessImpedance_8_2 65535;
BA_ "GenSigSNA" SG_ 2626748418 BATT_HarnessImpedance_10_2 65535;
BA_ "GenSigSNA" SG_ 2626748418 BATT_HarnessImpedance_14_2 65535;
BA_ "GenSigSNA" SG_ 2626748418 BATT_HarnessImpedance_13_2 65535;
BA_ "GenSigSNA" SG_ 2626748418 BATT_HarnessImpedance_11_2 65535;
BA_ "GenSigSNA" SG_ 2626748418 BATT_HarnessImpedance_12_2 65535;
BA_ "GenSigSNA" SG_ 2626748418 BATT_HarnessImpedance_9_2 65535;
BA_ "GenSigSNA" SG_ 2626748418 BATT_HarnessImpedance_5_2 65535;
BA_ "GenSigSNA" SG_ 2626748419 BATT_HarnessImpedance_6_3 65535;
BA_ "GenSigSNA" SG_ 2626748419 BATT_HarnessImpedance_8_3 65535;
BA_ "GenSigSNA" SG_ 2626748419 BATT_HarnessImpedance_11_3 65535;
BA_ "GenSigSNA" SG_ 2626748419 BATT_HarnessImpedance_7_3 65535;
BA_ "GenSigSNA" SG_ 2626748419 BATT_HarnessImpedance_4_3 65535;
BA_ "GenSigSNA" SG_ 2626748419 BATT_HarnessImpedance_5_3 65535;
BA_ "GenSigSNA" SG_ 2626748419 BATT_HarnessImpedance_2_3 65535;
BA_ "GenSigSNA" SG_ 2626748419 BATT_HarnessImpedance_3_3 65535;
BA_ "GenSigSNA" SG_ 2626748419 BATT_HarnessImpedance_10_3 65535;
BA_ "GenSigSNA" SG_ 2626748419 BATT_HarnessImpedance_14_3 65535;
BA_ "GenSigSNA" SG_ 2626748419 BATT_HarnessImpedance_1_3 65535;
BA_ "GenSigSNA" SG_ 2626748419 BATT_HarnessImpedance_0_3 65535;
BA_ "GenSigSNA" SG_ 2626748419 BATT_HarnessImpedance_12_3 65535;
BA_ "GenSigSNA" SG_ 2626748419 BATT_HarnessImpedance_13_3 65535;
BA_ "GenSigSNA" SG_ 2626748419 BATT_HarnessImpedance_9_3 65535;
BA_ "GenSigSNA" SG_ 2626748420 BATT_HarnessImpedance_13_4 65535;
BA_ "GenSigSNA" SG_ 2626748420 BATT_HarnessImpedance_1_4 65535;
BA_ "GenSigSNA" SG_ 2626748420 BATT_HarnessImpedance_12_4 65535;
BA_ "GenSigSNA" SG_ 2626748420 BATT_HarnessImpedance_9_4 65535;
BA_ "GenSigSNA" SG_ 2626748420 BATT_HarnessImpedance_14_4 65535;
BA_ "GenSigSNA" SG_ 2626748420 BATT_HarnessImpedance_7_4 65535;
BA_ "GenSigSNA" SG_ 2626748420 BATT_HarnessImpedance_10_4 65535;
BA_ "GenSigSNA" SG_ 2626748420 BATT_HarnessImpedance_5_4 65535;
BA_ "GenSigSNA" SG_ 2626748420 BATT_HarnessImpedance_11_4 65535;
BA_ "GenSigSNA" SG_ 2626748420 BATT_HarnessImpedance_6_4 65535;
BA_ "GenSigSNA" SG_ 2626748420 BATT_HarnessImpedance_8_4 65535;
BA_ "GenSigSNA" SG_ 2626748420 BATT_HarnessImpedance_3_4 65535;
BA_ "GenSigSNA" SG_ 2626748420 BATT_HarnessImpedance_0_4 65535;
BA_ "GenSigSNA" SG_ 2626748420 BATT_HarnessImpedance_4_4 65535;
BA_ "GenSigSNA" SG_ 2626748420 BATT_HarnessImpedance_2_4 65535;
BA_ "GenSigSNA" SG_ 2626748421 BATT_HarnessImpedance_0_5 65535;
BA_ "GenSigSNA" SG_ 2626748421 BATT_HarnessImpedance_14_5 65535;
BA_ "GenSigSNA" SG_ 2626748421 BATT_HarnessImpedance_1_5 65535;
BA_ "GenSigSNA" SG_ 2626748421 BATT_HarnessImpedance_6_5 65535;
BA_ "GenSigSNA" SG_ 2626748421 BATT_HarnessImpedance_11_5 65535;
BA_ "GenSigSNA" SG_ 2626748421 BATT_HarnessImpedance_10_5 65535;
BA_ "GenSigSNA" SG_ 2626748421 BATT_HarnessImpedance_3_5 65535;
BA_ "GenSigSNA" SG_ 2626748421 BATT_HarnessImpedance_12_5 65535;
BA_ "GenSigSNA" SG_ 2626748421 BATT_HarnessImpedance_7_5 65535;
BA_ "GenSigSNA" SG_ 2626748421 BATT_HarnessImpedance_9_5 65535;
BA_ "GenSigSNA" SG_ 2626748421 BATT_HarnessImpedance_8_5 65535;
BA_ "GenSigSNA" SG_ 2626748421 BATT_HarnessImpedance_4_5 65535;
BA_ "GenSigSNA" SG_ 2626748421 BATT_HarnessImpedance_5_5 65535;
BA_ "GenSigSNA" SG_ 2626748421 BATT_HarnessImpedance_2_5 65535;
BA_ "GenSigSNA" SG_ 2626748421 BATT_HarnessImpedance_13_5 65535;
BA_ "GenSigSNA" SG_ 2626748422 BATT_HarnessImpedance_0_6 65535;
BA_ "GenSigSNA" SG_ 2626748422 BATT_HarnessImpedance_2_6 65535;
BA_ "GenSigSNA" SG_ 2626748422 BATT_HarnessImpedance_1_6 65535;
BA_ "GenSigSNA" SG_ 2626748422 BATT_HarnessImpedance_4_6 65535;
BA_ "GenSigSNA" SG_ 2626748422 BATT_HarnessImpedance_3_6 65535;
BA_ "GenSigSNA" SG_ 2626748422 BATT_HarnessImpedance_6_6 65535;
BA_ "GenSigSNA" SG_ 2626748422 BATT_HarnessImpedance_5_6 65535;
BA_ "GenSigSNA" SG_ 2626748422 BATT_HarnessImpedance_7_6 65535;
BA_ "GenSigSNA" SG_ 2626748422 BATT_HarnessImpedance_14_6 65535;
BA_ "GenSigSNA" SG_ 2626748422 BATT_HarnessImpedance_12_6 65535;
BA_ "GenSigSNA" SG_ 2626748422 BATT_HarnessImpedance_8_6 65535;
BA_ "GenSigSNA" SG_ 2626748422 BATT_HarnessImpedance_13_6 65535;
BA_ "GenSigSNA" SG_ 2626748422 BATT_HarnessImpedance_9_6 65535;
BA_ "GenSigSNA" SG_ 2626748422 BATT_HarnessImpedance_10_6 65535;
BA_ "GenSigSNA" SG_ 2626748422 BATT_HarnessImpedance_11_6 65535;
BA_ "GenSigSNA" SG_ 2626748423 BATT_HarnessImpedance_13_7 65535;
BA_ "GenSigSNA" SG_ 2626748423 BATT_HarnessImpedance_14_7 65535;
BA_ "GenSigSNA" SG_ 2626748423 BATT_HarnessImpedance_1_7 65535;
BA_ "GenSigSNA" SG_ 2626748423 BATT_HarnessImpedance_4_7 65535;
BA_ "GenSigSNA" SG_ 2626748423 BATT_HarnessImpedance_0_7 65535;
BA_ "GenSigSNA" SG_ 2626748423 BATT_HarnessImpedance_2_7 65535;
BA_ "GenSigSNA" SG_ 2626748423 BATT_HarnessImpedance_3_7 65535;
BA_ "GenSigSNA" SG_ 2626748423 BATT_HarnessImpedance_12_7 65535;
BA_ "GenSigSNA" SG_ 2626748423 BATT_HarnessImpedance_11_7 65535;
BA_ "GenSigSNA" SG_ 2626748423 BATT_HarnessImpedance_7_7 65535;
BA_ "GenSigSNA" SG_ 2626748423 BATT_HarnessImpedance_9_7 65535;
BA_ "GenSigSNA" SG_ 2626748423 BATT_HarnessImpedance_8_7 65535;
BA_ "GenSigSNA" SG_ 2626748423 BATT_HarnessImpedance_10_7 65535;
BA_ "GenSigSNA" SG_ 2626748423 BATT_HarnessImpedance_5_7 65535;
BA_ "GenSigSNA" SG_ 2626748423 BATT_HarnessImpedance_6_7 65535;
BA_ "GenSigSNA" SG_ 2626748424 BATT_HarnessImpedance_0_8 65535;
BA_ "GenSigSNA" SG_ 2626748424 BATT_HarnessImpedance_5_8 65535;
BA_ "GenSigSNA" SG_ 2626748424 BATT_HarnessImpedance_3_8 65535;
BA_ "GenSigSNA" SG_ 2626748424 BATT_HarnessImpedance_4_8 65535;
BA_ "GenSigSNA" SG_ 2626748424 BATT_HarnessImpedance_8_8 65535;
BA_ "GenSigSNA" SG_ 2626748424 BATT_HarnessImpedance_1_8 65535;
BA_ "GenSigSNA" SG_ 2626748424 BATT_HarnessImpedance_11_8 65535;
BA_ "GenSigSNA" SG_ 2626748424 BATT_HarnessImpedance_10_8 65535;
BA_ "GenSigSNA" SG_ 2626748424 BATT_HarnessImpedance_7_8 65535;
BA_ "GenSigSNA" SG_ 2626748424 BATT_HarnessImpedance_9_8 65535;
BA_ "GenSigSNA" SG_ 2626748424 BATT_HarnessImpedance_12_8 65535;
BA_ "GenSigSNA" SG_ 2626748424 BATT_HarnessImpedance_13_8 65535;
BA_ "GenSigSNA" SG_ 2626748424 BATT_HarnessImpedance_14_8 65535;
BA_ "GenSigSNA" SG_ 2626748424 BATT_HarnessImpedance_2_8 65535;
BA_ "GenSigSNA" SG_ 2626748424 BATT_HarnessImpedance_6_8 65535;
BA_ "GenSigSNA" SG_ 2626748425 BATT_HarnessImpedance_3_9 65535;
BA_ "GenSigSNA" SG_ 2626748425 BATT_HarnessImpedance_2_9 65535;
BA_ "GenSigSNA" SG_ 2626748425 BATT_HarnessImpedance_1_9 65535;
BA_ "GenSigSNA" SG_ 2626748425 BATT_HarnessImpedance_11_9 65535;
BA_ "GenSigSNA" SG_ 2626748425 BATT_HarnessImpedance_12_9 65535;
BA_ "GenSigSNA" SG_ 2626748425 BATT_HarnessImpedance_13_9 65535;
BA_ "GenSigSNA" SG_ 2626748425 BATT_HarnessImpedance_10_9 65535;
BA_ "GenSigSNA" SG_ 2626748425 BATT_HarnessImpedance_14_9 65535;
BA_ "GenSigSNA" SG_ 2626748425 BATT_HarnessImpedance_5_9 65535;
BA_ "GenSigSNA" SG_ 2626748425 BATT_HarnessImpedance_4_9 65535;
BA_ "GenSigSNA" SG_ 2626748425 BATT_HarnessImpedance_6_9 65535;
BA_ "GenSigSNA" SG_ 2626748425 BATT_HarnessImpedance_7_9 65535;
BA_ "GenSigSNA" SG_ 2626748425 BATT_HarnessImpedance_8_9 65535;
BA_ "GenSigSNA" SG_ 2626748425 BATT_HarnessImpedance_9_9 65535;
BA_ "GenSigSNA" SG_ 2626748425 BATT_HarnessImpedance_0_9 65535;
BA_ "GenSigSNA" SG_ 2626748426 BATT_HarnessImpedance_5_10 65535;
BA_ "GenSigSNA" SG_ 2626748426 BATT_HarnessImpedance_14_10 65535;
BA_ "GenSigSNA" SG_ 2626748426 BATT_HarnessImpedance_13_10 65535;
BA_ "GenSigSNA" SG_ 2626748426 BATT_HarnessImpedance_8_10 65535;
BA_ "GenSigSNA" SG_ 2626748426 BATT_HarnessImpedance_7_10 65535;
BA_ "GenSigSNA" SG_ 2626748426 BATT_HarnessImpedance_2_10 65535;
BA_ "GenSigSNA" SG_ 2626748426 BATT_HarnessImpedance_1_10 65535;
BA_ "GenSigSNA" SG_ 2626748426 BATT_HarnessImpedance_10_10 65535;
BA_ "GenSigSNA" SG_ 2626748426 BATT_HarnessImpedance_9_10 65535;
BA_ "GenSigSNA" SG_ 2626748426 BATT_HarnessImpedance_4_10 65535;
BA_ "GenSigSNA" SG_ 2626748426 BATT_HarnessImpedance_3_10 65535;
BA_ "GenSigSNA" SG_ 2626748426 BATT_HarnessImpedance_12_10 65535;
BA_ "GenSigSNA" SG_ 2626748426 BATT_HarnessImpedance_11_10 65535;
BA_ "GenSigSNA" SG_ 2626748426 BATT_HarnessImpedance_6_10 65535;
BA_ "GenSigSNA" SG_ 2626748426 BATT_HarnessImpedance_0_10 65535;
BA_ "GenSigSNA" SG_ 2626748427 BATT_HarnessImpedance_13_11 65535;
BA_ "GenSigSNA" SG_ 2626748427 BATT_HarnessImpedance_12_11 65535;
BA_ "GenSigSNA" SG_ 2626748427 BATT_HarnessImpedance_14_11 65535;
BA_ "GenSigSNA" SG_ 2626748427 BATT_HarnessImpedance_11_11 65535;
BA_ "GenSigSNA" SG_ 2626748427 BATT_HarnessImpedance_6_11 65535;
BA_ "GenSigSNA" SG_ 2626748427 BATT_HarnessImpedance_5_11 65535;
BA_ "GenSigSNA" SG_ 2626748427 BATT_HarnessImpedance_4_11 65535;
BA_ "GenSigSNA" SG_ 2626748427 BATT_HarnessImpedance_3_11 65535;
BA_ "GenSigSNA" SG_ 2626748427 BATT_HarnessImpedance_2_11 65535;
BA_ "GenSigSNA" SG_ 2626748427 BATT_HarnessImpedance_8_11 65535;
BA_ "GenSigSNA" SG_ 2626748427 BATT_HarnessImpedance_7_11 65535;
BA_ "GenSigSNA" SG_ 2626748427 BATT_HarnessImpedance_10_11 65535;
BA_ "GenSigSNA" SG_ 2626748427 BATT_HarnessImpedance_9_11 65535;
BA_ "GenSigSNA" SG_ 2626748427 BATT_HarnessImpedance_1_11 65535;
BA_ "GenSigSNA" SG_ 2626748427 BATT_HarnessImpedance_0_11 65535;
BA_ "GenSigSNA" SG_ 2626813952 BATT_HrnsImpDelta_1_0 65535;
BA_ "GenSigSNA" SG_ 2626813952 BATT_HrnsImpDelta_3_0 65535;
BA_ "GenSigSNA" SG_ 2626813952 BATT_HrnsImpDelta_0_0 65535;
BA_ "GenSigSNA" SG_ 2626813952 BATT_HrnsImpDelta_2_0 65535;
BA_ "GenSigSNA" SG_ 2626813953 BATT_HrnsImpDelta_3_1 65535;
BA_ "GenSigSNA" SG_ 2626813953 BATT_HrnsImpDelta_1_1 65535;
BA_ "GenSigSNA" SG_ 2626813953 BATT_HrnsImpDelta_2_1 65535;
BA_ "GenSigSNA" SG_ 2626813953 BATT_HrnsImpDelta_0_1 65535;
BA_ "GenSigSNA" SG_ 2626813954 BATT_HrnsImpDelta_0_2 65535;
BA_ "GenSigSNA" SG_ 2626813954 BATT_HrnsImpDelta_3_2 65535;
BA_ "GenSigSNA" SG_ 2626813954 BATT_HrnsImpDelta_2_2 65535;
BA_ "GenSigSNA" SG_ 2626813954 BATT_HrnsImpDelta_1_2 65535;
BA_ "GenSigSNA" SG_ 2626813955 BATT_HrnsImpDelta_0_3 65535;
BA_ "GenSigSNA" SG_ 2626813955 BATT_HrnsImpDelta_1_3 65535;
BA_ "GenSigSNA" SG_ 2626813955 BATT_HrnsImpDelta_3_3 65535;
BA_ "GenSigSNA" SG_ 2626813955 BATT_HrnsImpDelta_2_3 65535;
BA_ "GenSigSNA" SG_ 2626813956 BATT_HrnsImpDelta_1_4 65535;
BA_ "GenSigSNA" SG_ 2626813956 BATT_HrnsImpDelta_3_4 65535;
BA_ "GenSigSNA" SG_ 2626813956 BATT_HrnsImpDelta_2_4 65535;
BA_ "GenSigSNA" SG_ 2626813956 BATT_HrnsImpDelta_0_4 65535;
BA_ "GenSigSNA" SG_ 2626813957 BATT_HrnsImpDelta_2_5 65535;
BA_ "GenSigSNA" SG_ 2626813957 BATT_HrnsImpDelta_3_5 65535;
BA_ "GenSigSNA" SG_ 2626813957 BATT_HrnsImpDelta_1_5 65535;
BA_ "GenSigSNA" SG_ 2626813957 BATT_HrnsImpDelta_0_5 65535;
VAL_ 2621702151 BATT_capBrick04_7  65535 "SNA"  ;
VAL_ 2621702151 BATT_capBrick03_7  65535 "SNA"  ;
VAL_ 2621702151 BATT_capBrick02_7  65535 "SNA"  ;
VAL_ 2621702151 BATT_capBrick01_7  65535 "SNA"  ;
VAL_ 2621702152 BATT_capBrick04_8  65535 "SNA"  ;
VAL_ 2621702152 BATT_capBrick03_8  65535 "SNA"  ;
VAL_ 2621702152 BATT_capBrick02_8  65535 "SNA"  ;
VAL_ 2621702152 BATT_capBrick01_8  65535 "SNA"  ;
VAL_ 2621702153 BATT_capBrick04_9  65535 "SNA"  ;
VAL_ 2621702153 BATT_capBrick03_9  65535 "SNA"  ;
VAL_ 2621702153 BATT_capBrick02_9  65535 "SNA"  ;
VAL_ 2621702153 BATT_capBrick01_9  65535 "SNA"  ;
VAL_ 2621702154 BATT_capBrick04_10  65535 "SNA"  ;
VAL_ 2621702154 BATT_capBrick03_10  65535 "SNA"  ;
VAL_ 2621702154 BATT_capBrick02_10  65535 "SNA"  ;
VAL_ 2621702154 BATT_capBrick01_10  65535 "SNA"  ;
VAL_ 2621702155 BATT_capBrick04_11  65535 "SNA"  ;
VAL_ 2621702155 BATT_capBrick03_11  65535 "SNA"  ;
VAL_ 2621702155 BATT_capBrick02_11  65535 "SNA"  ;
VAL_ 2621702155 BATT_capBrick01_11  65535 "SNA"  ;
VAL_ 2621964288 BATT_capBrick08_0  65535 "SNA"  ;
VAL_ 2621964288 BATT_capBrick07_0  65535 "SNA"  ;
VAL_ 2621964288 BATT_capBrick06_0  65535 "SNA"  ;
VAL_ 2621964288 BATT_capBrick05_0  65535 "SNA"  ;
VAL_ 2621964289 BATT_capBrick08_1  65535 "SNA"  ;
VAL_ 2621964289 BATT_capBrick07_1  65535 "SNA"  ;
VAL_ 2621964289 BATT_capBrick06_1  65535 "SNA"  ;
VAL_ 2621964289 BATT_capBrick05_1  65535 "SNA"  ;
VAL_ 2621964290 BATT_capBrick08_2  65535 "SNA"  ;
VAL_ 2621964290 BATT_capBrick07_2  65535 "SNA"  ;
VAL_ 2621964290 BATT_capBrick06_2  65535 "SNA"  ;
VAL_ 2621964290 BATT_capBrick05_2  65535 "SNA"  ;
VAL_ 2621964291 BATT_capBrick08_3  65535 "SNA"  ;
VAL_ 2621964291 BATT_capBrick07_3  65535 "SNA"  ;
VAL_ 2621964291 BATT_capBrick06_3  65535 "SNA"  ;
VAL_ 2621964291 BATT_capBrick05_3  65535 "SNA"  ;
VAL_ 2621964292 BATT_capBrick08_4  65535 "SNA"  ;
VAL_ 2621964292 BATT_capBrick07_4  65535 "SNA"  ;
VAL_ 2621964292 BATT_capBrick06_4  65535 "SNA"  ;
VAL_ 2621964292 BATT_capBrick05_4  65535 "SNA"  ;
VAL_ 2621964293 BATT_capBrick08_5  65535 "SNA"  ;
VAL_ 2621964293 BATT_capBrick07_5  65535 "SNA"  ;
VAL_ 2621964293 BATT_capBrick06_5  65535 "SNA"  ;
VAL_ 2621964293 BATT_capBrick05_5  65535 "SNA"  ;
VAL_ 2621964294 BATT_capBrick08_6  65535 "SNA"  ;
VAL_ 2621964294 BATT_capBrick07_6  65535 "SNA"  ;
VAL_ 2621964294 BATT_capBrick06_6  65535 "SNA"  ;
VAL_ 2621964294 BATT_capBrick05_6  65535 "SNA"  ;
VAL_ 2621964295 BATT_capBrick08_7  65535 "SNA"  ;
VAL_ 2621964295 BATT_capBrick07_7  65535 "SNA"  ;
VAL_ 2621964295 BATT_capBrick06_7  65535 "SNA"  ;
VAL_ 2621964295 BATT_capBrick05_7  65535 "SNA"  ;
VAL_ 2621964296 BATT_capBrick08_8  65535 "SNA"  ;
VAL_ 2621964296 BATT_capBrick07_8  65535 "SNA"  ;
VAL_ 2621964296 BATT_capBrick06_8  65535 "SNA"  ;
VAL_ 2621964296 BATT_capBrick05_8  65535 "SNA"  ;
VAL_ 2621964297 BATT_capBrick08_9  65535 "SNA"  ;
VAL_ 2621964297 BATT_capBrick07_9  65535 "SNA"  ;
VAL_ 2621964297 BATT_capBrick06_9  65535 "SNA"  ;
VAL_ 2621964297 BATT_capBrick05_9  65535 "SNA"  ;
VAL_ 2621964298 BATT_capBrick08_10  65535 "SNA"  ;
VAL_ 2621964298 BATT_capBrick07_10  65535 "SNA"  ;
VAL_ 2621964298 BATT_capBrick06_10  65535 "SNA"  ;
VAL_ 2621964298 BATT_capBrick05_10  65535 "SNA"  ;
VAL_ 2621964299 BATT_capBrick08_11  65535 "SNA"  ;
VAL_ 2621964299 BATT_capBrick07_11  65535 "SNA"  ;
VAL_ 2621964299 BATT_capBrick06_11  65535 "SNA"  ;
VAL_ 2621964299 BATT_capBrick05_11  65535 "SNA"  ;
VAL_ 2622226432 BATT_capBrick12_0  65535 "SNA"  ;
VAL_ 2622226432 BATT_capBrick11_0  65535 "SNA"  ;
VAL_ 2622226432 BATT_capBrick09_0  65535 "SNA"  ;
VAL_ 2622226432 BATT_capBrick10_0  65535 "SNA"  ;
VAL_ 2622226433 BATT_capBrick12_1  65535 "SNA"  ;
VAL_ 2622226433 BATT_capBrick11_1  65535 "SNA"  ;
VAL_ 2622226433 BATT_capBrick09_1  65535 "SNA"  ;
VAL_ 2622226433 BATT_capBrick10_1  65535 "SNA"  ;
VAL_ 2622226434 BATT_capBrick12_2  65535 "SNA"  ;
VAL_ 2622226434 BATT_capBrick11_2  65535 "SNA"  ;
VAL_ 2622226434 BATT_capBrick09_2  65535 "SNA"  ;
VAL_ 2622226434 BATT_capBrick10_2  65535 "SNA"  ;
VAL_ 2622226435 BATT_capBrick12_3  65535 "SNA"  ;
VAL_ 2622226435 BATT_capBrick11_3  65535 "SNA"  ;
VAL_ 2622226435 BATT_capBrick09_3  65535 "SNA"  ;
VAL_ 2622226435 BATT_capBrick10_3  65535 "SNA"  ;
VAL_ 2622226436 BATT_capBrick12_4  65535 "SNA"  ;
VAL_ 2622226436 BATT_capBrick11_4  65535 "SNA"  ;
VAL_ 2622226436 BATT_capBrick09_4  65535 "SNA"  ;
VAL_ 2622226436 BATT_capBrick10_4  65535 "SNA"  ;
VAL_ 2622226437 BATT_capBrick12_5  65535 "SNA"  ;
VAL_ 2622226437 BATT_capBrick11_5  65535 "SNA"  ;
VAL_ 2622226437 BATT_capBrick09_5  65535 "SNA"  ;
VAL_ 2622226437 BATT_capBrick10_5  65535 "SNA"  ;
VAL_ 2622226438 BATT_capBrick12_6  65535 "SNA"  ;
VAL_ 2622226438 BATT_capBrick11_6  65535 "SNA"  ;
VAL_ 2622226438 BATT_capBrick09_6  65535 "SNA"  ;
VAL_ 2622226438 BATT_capBrick10_6  65535 "SNA"  ;
VAL_ 2622226439 BATT_capBrick12_7  65535 "SNA"  ;
VAL_ 2622226439 BATT_capBrick11_7  65535 "SNA"  ;
VAL_ 2622226439 BATT_capBrick09_7  65535 "SNA"  ;
VAL_ 2622226439 BATT_capBrick10_7  65535 "SNA"  ;
VAL_ 2622226440 BATT_capBrick12_8  65535 "SNA"  ;
VAL_ 2622226440 BATT_capBrick11_8  65535 "SNA"  ;
VAL_ 2622226440 BATT_capBrick09_8  65535 "SNA"  ;
VAL_ 2622226440 BATT_capBrick10_8  65535 "SNA"  ;
VAL_ 2622226441 BATT_capBrick12_9  65535 "SNA"  ;
VAL_ 2622226441 BATT_capBrick11_9  65535 "SNA"  ;
VAL_ 2622226441 BATT_capBrick09_9  65535 "SNA"  ;
VAL_ 2622226441 BATT_capBrick10_9  65535 "SNA"  ;
VAL_ 2622226442 BATT_capBrick12_10  65535 "SNA"  ;
VAL_ 2622226442 BATT_capBrick11_10  65535 "SNA"  ;
VAL_ 2622226442 BATT_capBrick09_10  65535 "SNA"  ;
VAL_ 2622226442 BATT_capBrick10_10  65535 "SNA"  ;
VAL_ 2622226443 BATT_capBrick12_11  65535 "SNA"  ;
VAL_ 2622226443 BATT_capBrick11_11  65535 "SNA"  ;
VAL_ 2622226443 BATT_capBrick09_11  65535 "SNA"  ;
VAL_ 2622226443 BATT_capBrick10_11  65535 "SNA"  ;
VAL_ 2622488576 BATT_capBrick14_0  65535 "SNA"  ;
VAL_ 2622488576 BATT_capBrick13_0  65535 "SNA"  ;
VAL_ 2622488577 BATT_capBrick14_1  65535 "SNA"  ;
VAL_ 2622488577 BATT_capBrick13_1  65535 "SNA"  ;
VAL_ 2622488578 BATT_capBrick14_2  65535 "SNA"  ;
VAL_ 2622488578 BATT_capBrick13_2  65535 "SNA"  ;
VAL_ 2622488579 BATT_capBrick14_3  65535 "SNA"  ;
VAL_ 2622488579 BATT_capBrick13_3  65535 "SNA"  ;
VAL_ 2622488580 BATT_capBrick14_4  65535 "SNA"  ;
VAL_ 2622488580 BATT_capBrick13_4  65535 "SNA"  ;
VAL_ 2622488581 BATT_capBrick14_5  65535 "SNA"  ;
VAL_ 2622488581 BATT_capBrick13_5  65535 "SNA"  ;
VAL_ 2622488582 BATT_capBrick14_6  65535 "SNA"  ;
VAL_ 2622488582 BATT_capBrick13_6  65535 "SNA"  ;
VAL_ 2622488583 BATT_capBrick14_7  65535 "SNA"  ;
VAL_ 2622488583 BATT_capBrick13_7  65535 "SNA"  ;
VAL_ 2622488584 BATT_capBrick14_8  65535 "SNA"  ;
VAL_ 2622488584 BATT_capBrick13_8  65535 "SNA"  ;
VAL_ 2622488585 BATT_capBrick14_9  65535 "SNA"  ;
VAL_ 2622488585 BATT_capBrick13_9  65535 "SNA"  ;
VAL_ 2622488586 BATT_capBrick14_10  65535 "SNA"  ;
VAL_ 2622488586 BATT_capBrick13_10  65535 "SNA"  ;
VAL_ 2622488587 BATT_capBrick14_11  65535 "SNA"  ;
VAL_ 2622488587 BATT_capBrick13_11  65535 "SNA"  ;
VAL_ 2625896448 BATT_vBrick02_0  65535 "SNA"  ;
VAL_ 2625896448 BATT_vBrick03_0  65535 "SNA"  ;
VAL_ 2625896448 BATT_vBrick01_0  65535 "SNA"  ;
VAL_ 2625896448 BATT_vBrick04_0  65535 "SNA"  ;
VAL_ 2625896449 BATT_vBrick02_1  65535 "SNA"  ;
VAL_ 2625896449 BATT_vBrick03_1  65535 "SNA"  ;
VAL_ 2625896449 BATT_vBrick01_1  65535 "SNA"  ;
VAL_ 2625896449 BATT_vBrick04_1  65535 "SNA"  ;
VAL_ 2625896450 BATT_vBrick02_2  65535 "SNA"  ;
VAL_ 2625896450 BATT_vBrick03_2  65535 "SNA"  ;
VAL_ 2625896450 BATT_vBrick01_2  65535 "SNA"  ;
VAL_ 2625896450 BATT_vBrick04_2  65535 "SNA"  ;
VAL_ 2625896451 BATT_vBrick02_3  65535 "SNA"  ;
VAL_ 2625896451 BATT_vBrick03_3  65535 "SNA"  ;
VAL_ 2625896451 BATT_vBrick01_3  65535 "SNA"  ;
VAL_ 2625896451 BATT_vBrick04_3  65535 "SNA"  ;
VAL_ 2625896452 BATT_vBrick02_4  65535 "SNA"  ;
VAL_ 2625896452 BATT_vBrick03_4  65535 "SNA"  ;
VAL_ 2625896452 BATT_vBrick01_4  65535 "SNA"  ;
VAL_ 2625896452 BATT_vBrick04_4  65535 "SNA"  ;
VAL_ 2625896453 BATT_vBrick02_5  65535 "SNA"  ;
VAL_ 2625896453 BATT_vBrick03_5  65535 "SNA"  ;
VAL_ 2625896453 BATT_vBrick01_5  65535 "SNA"  ;
VAL_ 2625896453 BATT_vBrick04_5  65535 "SNA"  ;
VAL_ 2625896454 BATT_vBrick02_6  65535 "SNA"  ;
VAL_ 2625896454 BATT_vBrick03_6  65535 "SNA"  ;
VAL_ 2625896454 BATT_vBrick01_6  65535 "SNA"  ;
VAL_ 2625896454 BATT_vBrick04_6  65535 "SNA"  ;
VAL_ 2625896455 BATT_vBrick02_7  65535 "SNA"  ;
VAL_ 2625896455 BATT_vBrick03_7  65535 "SNA"  ;
VAL_ 2625896455 BATT_vBrick01_7  65535 "SNA"  ;
VAL_ 2625896455 BATT_vBrick04_7  65535 "SNA"  ;
VAL_ 2625896456 BATT_vBrick02_8  65535 "SNA"  ;
VAL_ 2625896456 BATT_vBrick03_8  65535 "SNA"  ;
VAL_ 2625896456 BATT_vBrick01_8  65535 "SNA"  ;
VAL_ 2625896456 BATT_vBrick04_8  65535 "SNA"  ;
VAL_ 2625896457 BATT_vBrick02_9  65535 "SNA"  ;
VAL_ 2625896457 BATT_vBrick03_9  65535 "SNA"  ;
VAL_ 2625896457 BATT_vBrick01_9  65535 "SNA"  ;
VAL_ 2625896457 BATT_vBrick04_9  65535 "SNA"  ;
VAL_ 2625896458 BATT_vBrick02_10  65535 "SNA"  ;
VAL_ 2625896458 BATT_vBrick03_10  65535 "SNA"  ;
VAL_ 2625896458 BATT_vBrick01_10  65535 "SNA"  ;
VAL_ 2625896458 BATT_vBrick04_10  65535 "SNA"  ;
VAL_ 2625896459 BATT_vBrick02_11  65535 "SNA"  ;
VAL_ 2625896459 BATT_vBrick03_11  65535 "SNA"  ;
VAL_ 2625896459 BATT_vBrick01_11  65535 "SNA"  ;
VAL_ 2625896459 BATT_vBrick04_11  65535 "SNA"  ;
VAL_ 2626158592 BATT_vBrick06_0  65535 "SNA"  ;
VAL_ 2626158592 BATT_vBrick07_0  65535 "SNA"  ;
VAL_ 2626158592 BATT_vBrick05_0  65535 "SNA"  ;
VAL_ 2626158592 BATT_vBrick08_0  65535 "SNA"  ;
VAL_ 2626158593 BATT_vBrick06_1  65535 "SNA"  ;
VAL_ 2626158593 BATT_vBrick07_1  65535 "SNA"  ;
VAL_ 2626158593 BATT_vBrick05_1  65535 "SNA"  ;
VAL_ 2626158593 BATT_vBrick08_1  65535 "SNA"  ;
VAL_ 2626158594 BATT_vBrick06_2  65535 "SNA"  ;
VAL_ 2626158594 BATT_vBrick07_2  65535 "SNA"  ;
VAL_ 2626158594 BATT_vBrick05_2  65535 "SNA"  ;
VAL_ 2626158594 BATT_vBrick08_2  65535 "SNA"  ;
VAL_ 2626158595 BATT_vBrick06_3  65535 "SNA"  ;
VAL_ 2626158595 BATT_vBrick07_3  65535 "SNA"  ;
VAL_ 2626158595 BATT_vBrick05_3  65535 "SNA"  ;
VAL_ 2626158595 BATT_vBrick08_3  65535 "SNA"  ;
VAL_ 2626158596 BATT_vBrick06_4  65535 "SNA"  ;
VAL_ 2626158596 BATT_vBrick07_4  65535 "SNA"  ;
VAL_ 2626158596 BATT_vBrick05_4  65535 "SNA"  ;
VAL_ 2626158596 BATT_vBrick08_4  65535 "SNA"  ;
VAL_ 2626158597 BATT_vBrick06_5  65535 "SNA"  ;
VAL_ 2626158597 BATT_vBrick07_5  65535 "SNA"  ;
VAL_ 2626158597 BATT_vBrick05_5  65535 "SNA"  ;
VAL_ 2626158597 BATT_vBrick08_5  65535 "SNA"  ;
VAL_ 2626158598 BATT_vBrick06_6  65535 "SNA"  ;
VAL_ 2626158598 BATT_vBrick07_6  65535 "SNA"  ;
VAL_ 2626158598 BATT_vBrick05_6  65535 "SNA"  ;
VAL_ 2626158598 BATT_vBrick08_6  65535 "SNA"  ;
VAL_ 2626158599 BATT_vBrick06_7  65535 "SNA"  ;
VAL_ 2626158599 BATT_vBrick07_7  65535 "SNA"  ;
VAL_ 2626158599 BATT_vBrick05_7  65535 "SNA"  ;
VAL_ 2626158599 BATT_vBrick08_7  65535 "SNA"  ;
VAL_ 2626158600 BATT_vBrick06_8  65535 "SNA"  ;
VAL_ 2626158600 BATT_vBrick07_8  65535 "SNA"  ;
VAL_ 2626158600 BATT_vBrick05_8  65535 "SNA"  ;
VAL_ 2626158600 BATT_vBrick08_8  65535 "SNA"  ;
VAL_ 2626158601 BATT_vBrick06_9  65535 "SNA"  ;
VAL_ 2626158601 BATT_vBrick07_9  65535 "SNA"  ;
VAL_ 2626158601 BATT_vBrick05_9  65535 "SNA"  ;
VAL_ 2626158601 BATT_vBrick08_9  65535 "SNA"  ;
VAL_ 2626158602 BATT_vBrick06_10  65535 "SNA"  ;
VAL_ 2626158602 BATT_vBrick07_10  65535 "SNA"  ;
VAL_ 2626158602 BATT_vBrick05_10  65535 "SNA"  ;
VAL_ 2626158602 BATT_vBrick08_10  65535 "SNA"  ;
VAL_ 2626158603 BATT_vBrick06_11  65535 "SNA"  ;
VAL_ 2626158603 BATT_vBrick07_11  65535 "SNA"  ;
VAL_ 2626158603 BATT_vBrick05_11  65535 "SNA"  ;
VAL_ 2626158603 BATT_vBrick08_11  65535 "SNA"  ;
VAL_ 2626420736 BATT_vBrick12_0  65535 "SNA"  ;
VAL_ 2626420736 BATT_vBrick11_0  65535 "SNA"  ;
VAL_ 2626420736 BATT_vBrick10_0  65535 "SNA"  ;
VAL_ 2626420736 BATT_vBrick09_0  65535 "SNA"  ;
VAL_ 2626420737 BATT_vBrick12_1  65535 "SNA"  ;
VAL_ 2626420737 BATT_vBrick11_1  65535 "SNA"  ;
VAL_ 2626420737 BATT_vBrick10_1  65535 "SNA"  ;
VAL_ 2626420737 BATT_vBrick09_1  65535 "SNA"  ;
VAL_ 2626420738 BATT_vBrick12_2  65535 "SNA"  ;
VAL_ 2626420738 BATT_vBrick11_2  65535 "SNA"  ;
VAL_ 2626420738 BATT_vBrick10_2  65535 "SNA"  ;
VAL_ 2626420738 BATT_vBrick09_2  65535 "SNA"  ;
VAL_ 2626420739 BATT_vBrick12_3  65535 "SNA"  ;
VAL_ 2626420739 BATT_vBrick11_3  65535 "SNA"  ;
VAL_ 2626420739 BATT_vBrick10_3  65535 "SNA"  ;
VAL_ 2626420739 BATT_vBrick09_3  65535 "SNA"  ;
VAL_ 2626420740 BATT_vBrick12_4  65535 "SNA"  ;
VAL_ 2626420740 BATT_vBrick11_4  65535 "SNA"  ;
VAL_ 2626420740 BATT_vBrick10_4  65535 "SNA"  ;
VAL_ 2626420740 BATT_vBrick09_4  65535 "SNA"  ;
VAL_ 2626420741 BATT_vBrick12_5  65535 "SNA"  ;
VAL_ 2626420741 BATT_vBrick11_5  65535 "SNA"  ;
VAL_ 2626420741 BATT_vBrick10_5  65535 "SNA"  ;
VAL_ 2626420741 BATT_vBrick09_5  65535 "SNA"  ;
VAL_ 2626420742 BATT_vBrick12_6  65535 "SNA"  ;
VAL_ 2626420742 BATT_vBrick11_6  65535 "SNA"  ;
VAL_ 2626420742 BATT_vBrick10_6  65535 "SNA"  ;
VAL_ 2626420742 BATT_vBrick09_6  65535 "SNA"  ;
VAL_ 2626420743 BATT_vBrick12_7  65535 "SNA"  ;
VAL_ 2626420743 BATT_vBrick11_7  65535 "SNA"  ;
VAL_ 2626420743 BATT_vBrick10_7  65535 "SNA"  ;
VAL_ 2626420743 BATT_vBrick09_7  65535 "SNA"  ;
VAL_ 2626420744 BATT_vBrick12_8  65535 "SNA"  ;
VAL_ 2626420744 BATT_vBrick11_8  65535 "SNA"  ;
VAL_ 2626420744 BATT_vBrick10_8  65535 "SNA"  ;
VAL_ 2626420744 BATT_vBrick09_8  65535 "SNA"  ;
VAL_ 2626420745 BATT_vBrick12_9  65535 "SNA"  ;
VAL_ 2626420745 BATT_vBrick11_9  65535 "SNA"  ;
VAL_ 2626420745 BATT_vBrick10_9  65535 "SNA"  ;
VAL_ 2626420745 BATT_vBrick09_9  65535 "SNA"  ;
VAL_ 2626420746 BATT_vBrick12_10  65535 "SNA"  ;
VAL_ 2626420746 BATT_vBrick11_10  65535 "SNA"  ;
VAL_ 2626420746 BATT_vBrick10_10  65535 "SNA"  ;
VAL_ 2626420746 BATT_vBrick09_10  65535 "SNA"  ;
VAL_ 2626420747 BATT_vBrick12_11  65535 "SNA"  ;
VAL_ 2626420747 BATT_vBrick11_11  65535 "SNA"  ;
VAL_ 2626420747 BATT_vBrick10_11  65535 "SNA"  ;
VAL_ 2626420747 BATT_vBrick09_11  65535 "SNA"  ;
VAL_ 2626682880 BATT_vBrick14_0  65535 "SNA"  ;
VAL_ 2626682880 BATT_vBrick13_0  65535 "SNA"  ;
VAL_ 2626682881 BATT_vBrick14_1  65535 "SNA"  ;
VAL_ 2626682881 BATT_vBrick13_1  65535 "SNA"  ;
VAL_ 2626682882 BATT_vBrick14_2  65535 "SNA"  ;
VAL_ 2626682882 BATT_vBrick13_2  65535 "SNA"  ;
VAL_ 2626682883 BATT_vBrick14_3  65535 "SNA"  ;
VAL_ 2626682883 BATT_vBrick13_3  65535 "SNA"  ;
VAL_ 2626682884 BATT_vBrick14_4  65535 "SNA"  ;
VAL_ 2626682884 BATT_vBrick13_4  65535 "SNA"  ;
VAL_ 2626682885 BATT_vBrick14_5  65535 "SNA"  ;
VAL_ 2626682885 BATT_vBrick13_5  65535 "SNA"  ;
VAL_ 2626682886 BATT_vBrick14_6  65535 "SNA"  ;
VAL_ 2626682886 BATT_vBrick13_6  65535 "SNA"  ;
VAL_ 2626682887 BATT_vBrick14_7  65535 "SNA"  ;
VAL_ 2626682887 BATT_vBrick13_7  65535 "SNA"  ;
VAL_ 2626682888 BATT_vBrick14_8  65535 "SNA"  ;
VAL_ 2626682888 BATT_vBrick13_8  65535 "SNA"  ;
VAL_ 2626682889 BATT_vBrick14_9  65535 "SNA"  ;
VAL_ 2626682889 BATT_vBrick13_9  65535 "SNA"  ;
VAL_ 2626682890 BATT_vBrick14_10  65535 "SNA"  ;
VAL_ 2626682890 BATT_vBrick13_10  65535 "SNA"  ;
VAL_ 2626682891 BATT_vBrick14_11  65535 "SNA"  ;
VAL_ 2626682891 BATT_vBrick13_11  65535 "SNA"  ;
